VERSION ""

NS_ :

BS_:

BU_: AHLM ASBS CADM CBC DIAGNOST DPDM DTCM ECM EHPS ESC ESL ESM ETM EVCU2 GPF IC IRCM LTM OCM ORC PTS RF_HUB SCCM SGW TBM TCM

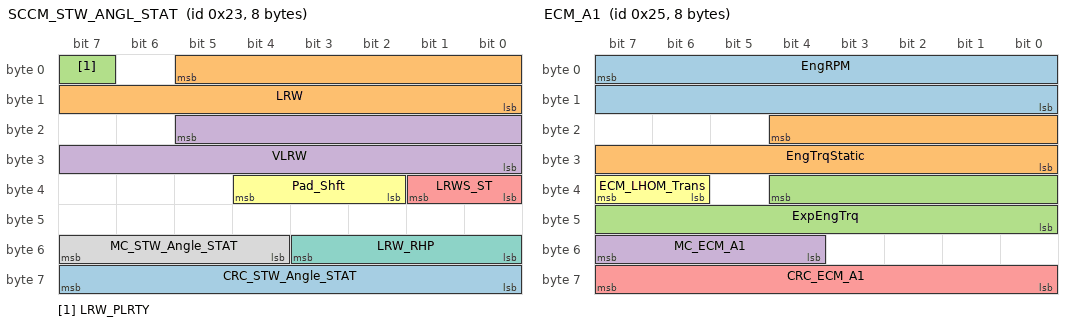
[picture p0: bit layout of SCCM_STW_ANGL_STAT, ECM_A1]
BO_ 35 SCCM_STW_ANGL_STAT: 8 SCCM
 SG_ CRC_STW_Angle_STAT : 56|8@1+ (1,0) [0|0] ""  CADM,ECM,ESC,ETM,EVCU2,IRCM,ORC,SGW,TCM
 SG_ LRW : 5|14@0+ (0.5,-2048) [-2048|2047] "Degrees"  CADM,CBC,DTCM,ECM,EHPS,ESC,EVCU2,IC,IRCM,ORC,SGW,TCM
 SG_ LRW_PLRTY : 7|1@1+ (1,0) [0|0] ""  CADM,ESC,ETM,IC,IRCM,ORC,SGW
 SG_ VLRW : 21|14@0+ (0.5,-2048) [-2048|2047] "∞/s"  CADM,DTCM,ECM,EHPS,ESC,EVCU2,IRCM,SGW
 SG_ LRWS_ST : 32|2@1+ (1,0) [0|0] ""  CADM,CBC,DTCM,ESC,IC,IRCM,ORC,SGW
 SG_ Pad_Shft : 34|3@1+ (1,0) [0|0] ""  ECM,SGW,TCM
 SG_ LRW_RHP : 48|4@1+ (0.1,-0.4) [-0.4|0.4] "Degrees"  CADM,EHPS,SGW
 SG_ MC_STW_Angle_STAT : 52|4@1+ (1,0) [0|15] ""  CADM,ECM,ESC,ETM,EVCU2,IRCM,ORC,SGW,TCM

BO_ 37 ECM_A1: 8 ECM
 SG_ EngRPM : 7|16@0+ (1,0) [0|65534] "rpm"  AHLM,CADM,CBC,DTCM,EHPS,ESC,ETM,EVCU2,IC,IRCM,ORC,RF_HUB,SGW,TBM,TCM
 SG_ EngTrqStatic : 20|13@0+ (0.25,-500) [-500|1547.5] "Nm"  CADM,DTCM,ESC,ETM,IRCM,ORC,SGW,TBM,TCM
 SG_ ExpEngTrq : 36|13@0+ (0.25,-500) [-500|1547.5] "Nm"  CADM,DTCM,ESC,IRCM,SGW
 SG_ MC_ECM_A1 : 52|4@1+ (1,0) [0|15] ""  CADM,ESC,IRCM,SGW,TCM
 SG_ CRC_ECM_A1 : 56|8@1+ (1,0) [0|0] ""  CADM,ESC,IRCM,SGW,TCM
 SG_ ECM_LHOM_Trans : 38|2@1+ (1,0) [0|0] ""  SGW,TCM

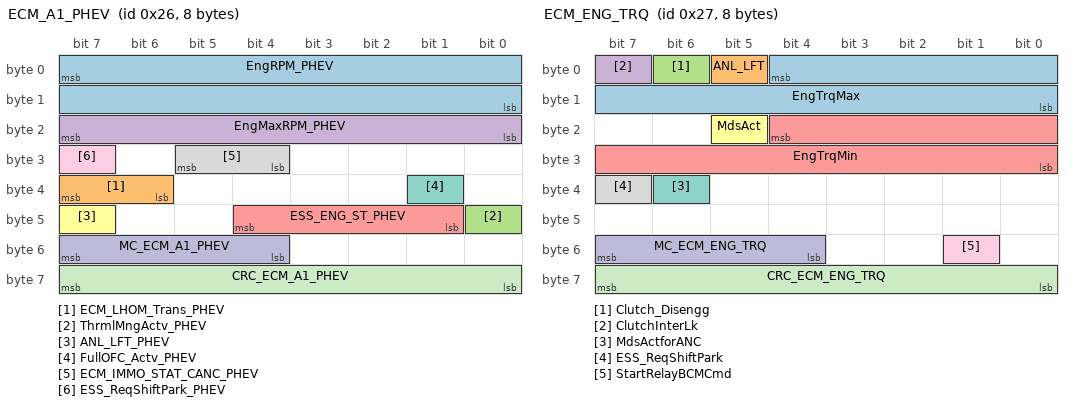
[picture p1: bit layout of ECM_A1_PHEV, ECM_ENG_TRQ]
BO_ 38 ECM_A1_PHEV: 8 ECM
 SG_ EngRPM_PHEV : 7|16@0+ (1,0) [0|65534] "rpm"  AHLM,CADM,CBC,EHPS,ESC,ETM,EVCU2,IC,IRCM,ORC,RF_HUB,SGW,TBM,TCM
 SG_ ECM_LHOM_Trans_PHEV : 38|2@1+ (1,0) [0|0] ""  EVCU2,SGW
 SG_ ThrmlMngActv_PHEV : 40|1@1+ (1,0) [0|0] ""  CADM,EVCU2,IRCM,SGW
 SG_ EngMaxRPM_PHEV : 16|8@1+ (50,0) [0|12700] "rpm"  EVCU2,SGW
 SG_ ESS_ENG_ST_PHEV : 41|4@1+ (1,0) [0|0] ""  CADM,CBC,DTCM,EHPS,ESC,EVCU2,IC,IRCM,ORC,PTS,SGW,TCM
 SG_ ANL_LFT_PHEV : 47|1@1+ (1,0) [0|0] ""  CBC,SGW
 SG_ FullOFC_Actv_PHEV : 33|1@1+ (1,0) [0|0] ""  ESC,SGW
 SG_ ECM_IMMO_STAT_CANC_PHEV : 28|2@1+ (1,0) [0|0] ""  CBC,EVCU2,SGW
 SG_ ESS_ReqShiftPark_PHEV : 31|1@1+ (1,0) [0|0] ""  SGW,TCM
 SG_ MC_ECM_A1_PHEV : 52|4@1+ (1,0) [0|15] ""  CADM,DTCM,ESC,EVCU2,IRCM,SGW,TCM
 SG_ CRC_ECM_A1_PHEV : 56|8@1+ (1,0) [0|0] ""  CADM,DTCM,ESC,EVCU2,IRCM,SGW,TCM

BO_ 39 ECM_ENG_TRQ: 8 ECM
 SG_ EngTrqMax : 4|13@0+ (0.25,-500) [-500|1547.5] "Nm"  CADM,DTCM,ESC,IRCM,SGW,TCM
 SG_ ANL_LFT : 5|1@1+ (1,0) [0|0] ""  CBC,SGW
 SG_ Clutch_Disengg : 6|1@1+ (1,0) [0|0] ""  CADM,CBC,DTCM,ECM,ESC,IRCM,ORC,SGW
 SG_ ClutchInterLk : 7|1@1+ (1,0) [0|0] ""  DTCM,ECM,ESC,ORC,SGW
 SG_ EngTrqMin : 20|13@0+ (0.25,-500) [-500|1547.5] "Nm"  CADM,DTCM,ESC,IRCM,SGW
 SG_ MdsAct : 21|1@1+ (1,0) [0|0] ""  ETM,SGW,TBM
 SG_ MdsActforANC : 38|1@1+ (1,0) [0|0] ""  CBC,SGW
 SG_ ESS_ReqShiftPark : 39|1@1+ (1,0) [0|0] ""  RF_HUB,SGW,TCM
 SG_ StartRelayBCMCmd : 49|1@1+ (1,0) [0|0] ""  CBC,SGW
 SG_ MC_ECM_ENG_TRQ : 52|4@1+ (1,0) [0|15] ""  CADM,ESC,IRCM,SGW
 SG_ CRC_ECM_ENG_TRQ : 56|8@1+ (1,0) [0|0] ""  CADM,ESC,IRCM,SGW

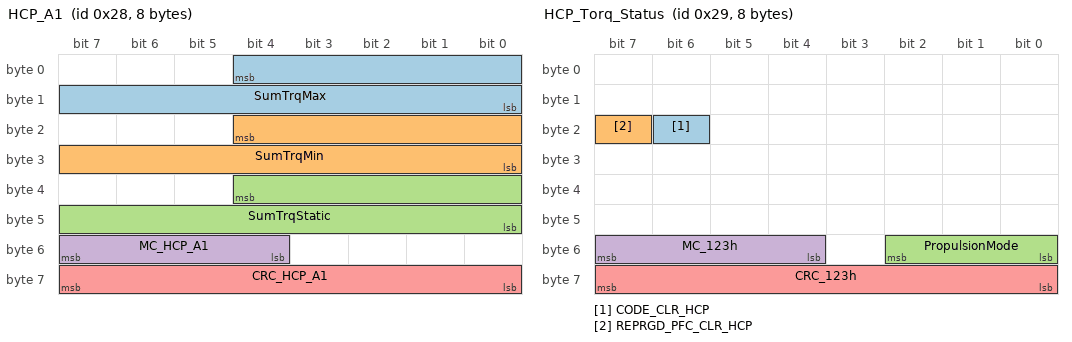
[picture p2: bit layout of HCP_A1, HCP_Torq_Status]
BO_ 40 HCP_A1: 8 EVCU2
 SG_ SumTrqMax : 4|13@0+ (0.25,-500) [-500|1547.5] "Nm"  CADM,DTCM,ESC,IRCM,SGW,TCM
 SG_ SumTrqMin : 20|13@0+ (0.25,-500) [-500|1547.5] "Nm"  CADM,IRCM,SGW
 SG_ SumTrqStatic : 36|13@0+ (0.25,-500) [-500|1547.5] "Nm"  CADM,DTCM,ESC,IRCM,ORC,SGW,TCM
 SG_ MC_HCP_A1 : 52|4@1+ (1,0) [0|15] ""  CADM,DTCM,ECM,ESC,IRCM,SGW,TCM
 SG_ CRC_HCP_A1 : 56|8@1+ (1,0) [0|0] ""  CADM,DTCM,ECM,ESC,IRCM,SGW,TCM

BO_ 41 HCP_Torq_Status: 8 EVCU2
 SG_ CODE_CLR_HCP : 22|1@1+ (1,0) [0|0] ""  ECM,SGW
 SG_ REPRGD_PFC_CLR_HCP : 23|1@1+ (1,0) [0|0] ""  ECM,SGW
 SG_ PropulsionMode : 48|3@1+ (1,0) [0|0] ""  ECM,SGW
 SG_ MC_123h : 52|4@1+ (1,0) [0|15] ""  ECM,SGW,TCM
 SG_ CRC_123h : 56|8@1+ (1,0) [0|255] ""  ECM,SGW,TCM

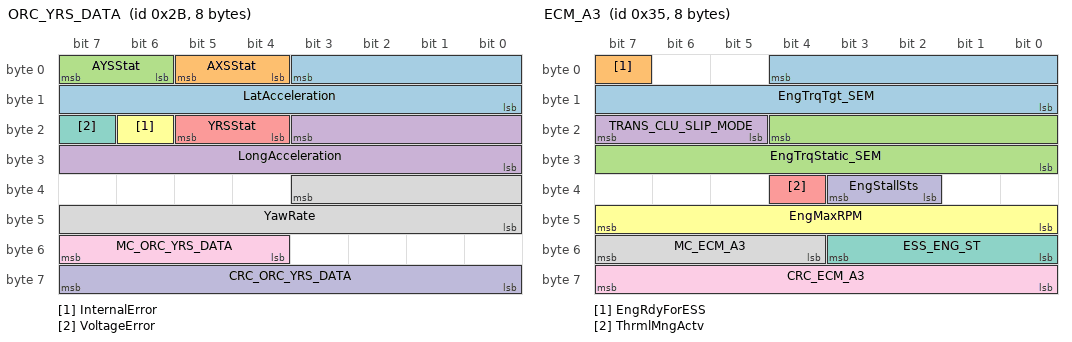
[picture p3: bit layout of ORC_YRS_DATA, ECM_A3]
BO_ 43 ORC_YRS_DATA: 8 ORC
 SG_ LatAcceleration : 3|12@0+ (0.02,-40.96) [-40.96|40.92] "m/s≤"  ESC,EVCU2,SGW
 SG_ AXSStat : 4|2@1+ (1,0) [0|0] ""  ESC,EVCU2,SGW
 SG_ AYSStat : 6|2@1+ (1,0) [0|0] ""  ESC,SGW
 SG_ LongAcceleration : 19|12@0+ (0.02,-40.96) [-40.96|40.92] "m/s≤"  ESC,EVCU2,SGW
 SG_ YRSStat : 20|2@1+ (1,0) [0|0] ""  ESC,EVCU2,SGW
 SG_ InternalError : 22|1@1+ (1,0) [0|0] ""  ESC,SGW
 SG_ VoltageError : 23|1@1+ (1,0) [0|0] ""  ESC,SGW
 SG_ YawRate : 35|12@0+ (0.08,-163.84) [-163.84|163.68] "∞/s"  CADM,ESC,EVCU2,SGW
 SG_ MC_ORC_YRS_DATA : 52|4@1+ (1,0) [0|15] ""  ESC,EVCU2,SGW
 SG_ CRC_ORC_YRS_DATA : 56|8@1+ (1,0) [0|0] ""  ESC,EVCU2,SGW

BO_ 47 WHEEL_SPEED_2: 8 ESC
 SG_ BrkPdlRawStat : 33|10@0+ (0.0048828125,0) [0|4.9951171875] "Volts"  ECM,ETM,ORC,SGW,TBM
 SG_ RAW_OBD_VEHACCEL_X : 48|8@1+ (0.08,-10.24) [-10.24|10.16] "m/s≤"  ECM,SGW

BO_ 53 ECM_A3: 8 ECM
 SG_ EngTrqTgt_SEM : 4|13@0+ (0.25,-500) [-500|1547.5] "Nm"  SGW,TCM
 SG_ EngRdyForESS : 7|1@1+ (1,0) [0|0] ""  SGW,TCM
 SG_ EngTrqStatic_SEM : 20|13@0+ (0.25,-500) [-500|1547.5] "Nm"  SGW,TCM
 SG_ TRANS_CLU_SLIP_MODE : 21|3@1+ (1,0) [0|0] ""  SGW,TCM
 SG_ ThrmlMngActv : 36|1@1+ (1,0) [0|0] ""  CADM,IRCM,SGW
 SG_ EngMaxRPM : 40|8@1+ (50,0) [0|12700] "rpm"  SGW
 SG_ ESS_ENG_ST : 48|4@1+ (1,0) [0|0] ""  CADM,CBC,DTCM,EHPS,ESC,ETM,IC,IRCM,ORC,PTS,RF_HUB,SGW,TBM,TCM
 SG_ MC_ECM_A3 : 52|4@1+ (1,0) [0|15] ""  CADM,EHPS,IRCM,PTS,RF_HUB,SGW,TCM
 SG_ CRC_ECM_A3 : 56|8@1+ (1,0) [0|0] ""  CADM,IRCM,PTS,RF_HUB,SGW,TCM
 SG_ EngStallSts : 34|2@1+ (1,0) [0|0] ""  RF_HUB,SGW

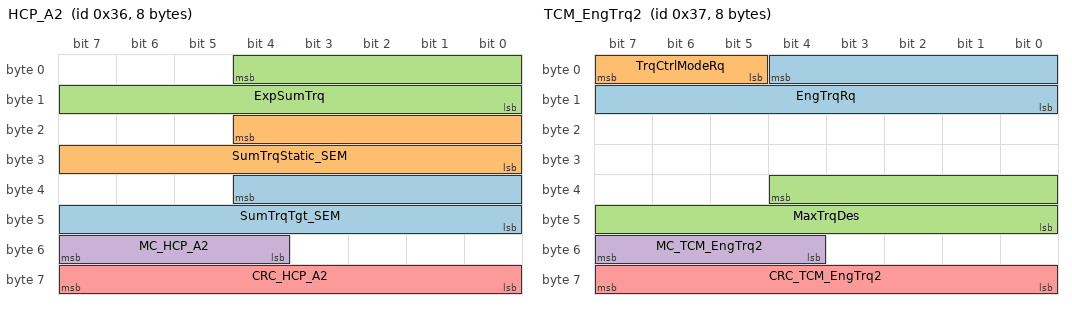
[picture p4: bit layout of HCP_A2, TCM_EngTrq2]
BO_ 54 HCP_A2: 8 EVCU2
 SG_ SumTrqTgt_SEM : 36|13@0+ (0.25,-500) [-500|1547.5] "Nm"  ECM,SGW,TCM
 SG_ SumTrqStatic_SEM : 20|13@0+ (0.25,-500) [-500|1547.5] "Nm"  ECM,SGW,TCM
 SG_ ExpSumTrq : 4|13@0+ (0.25,-500) [-500|1547.5] "Nm"  CADM,DTCM,ESC,IRCM,SGW
 SG_ MC_HCP_A2 : 52|4@1+ (1,0) [0|15] ""  CADM,DTCM,ECM,ESC,IRCM,SGW,TCM
 SG_ CRC_HCP_A2 : 56|8@1+ (1,0) [0|0] ""  CADM,DTCM,ECM,ESC,IRCM,SGW,TCM

BO_ 55 TCM_EngTrq2: 8 TCM
 SG_ EngTrqRq : 4|13@0+ (0.25,-500) [-500|1547.5] "Nm"  ECM,ESC,EVCU2,SGW
 SG_ TrqCtrlModeRq : 5|3@1+ (1,0) [0|0] ""  ECM,ESC,EVCU2,SGW
 SG_ MaxTrqDes : 36|13@0+ (0.25,-500) [-500|1547.5] "Nm"  ECM,EVCU2,SGW
 SG_ MC_TCM_EngTrq2 : 52|4@1+ (1,0) [0|15] ""  CADM,ECM,ESC,EVCU2,IRCM,SGW
 SG_ CRC_TCM_EngTrq2 : 56|8@1+ (1,0) [0|0] ""  CADM,ECM,ESC,EVCU2,IRCM,SGW

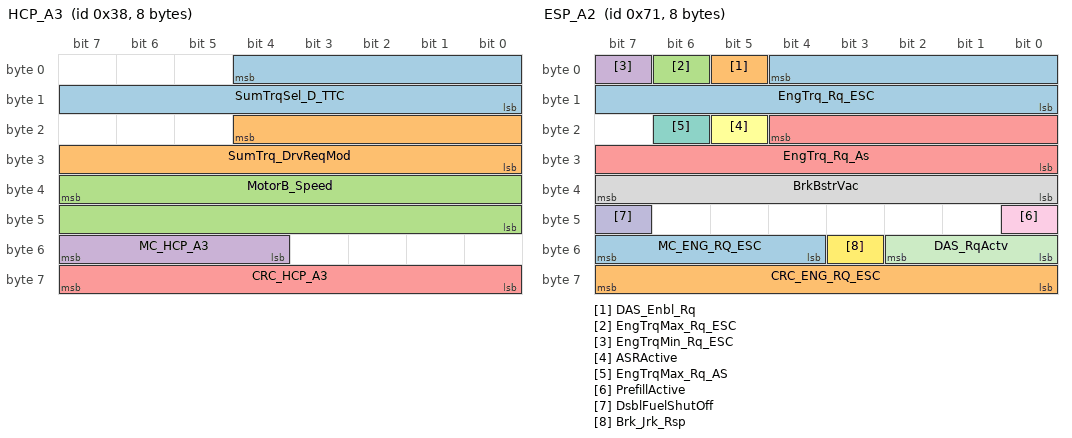
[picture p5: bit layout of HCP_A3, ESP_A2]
BO_ 56 HCP_A3: 8 EVCU2
 SG_ SumTrqSel_D_TTC : 4|13@0+ (0.25,-500) [-500|1547.5] "Nm"  CADM,DTCM,ESC,IRCM,ORC,SGW,TCM
 SG_ SumTrq_DrvReqMod : 20|13@0+ (0.25,-500) [-500|1547.5] "Nm"  CADM,DTCM,ESC,IRCM,SGW,TCM
 SG_ MotorB_Speed : 39|16@0+ (1,-16382) [-16382|49151] "rpm"  DTCM,ECM,ESC,SGW,TCM
 SG_ MC_HCP_A3 : 52|4@1+ (1,0) [0|15] ""  CADM,DTCM,ECM,ESC,IRCM,SGW,TCM
 SG_ CRC_HCP_A3 : 56|8@1+ (1,0) [0|0] ""  CADM,DTCM,ECM,ESC,IRCM,SGW,TCM

BO_ 113 ESP_A2: 8 ESC
 SG_ EngTrq_Rq_ESC : 4|13@0+ (0.25,-500) [-500|1547.5] "Nm"  DTCM,ECM,ETM,EVCU2,SGW,TBM
 SG_ DAS_Enbl_Rq : 5|1@1+ (1,0) [0|0] ""  CADM,EVCU2,IRCM,SGW
 SG_ EngTrqMax_Rq_ESC : 6|1@1+ (1,0) [0|0] ""  ECM,EVCU2,SGW,TCM
 SG_ EngTrqMin_Rq_ESC : 7|1@1+ (1,0) [0|0] ""  ECM,EVCU2,SGW,TCM
 SG_ EngTrq_Rq_As : 20|13@0+ (0.25,-500) [-500|1547.5] "Nm"  CADM,ECM,IRCM,ORC,SGW
 SG_ ASRActive : 21|1@1+ (1,0) [0|0] ""  ETM,ORC,SGW,TBM,TCM
 SG_ EngTrqMax_Rq_AS : 22|1@1+ (1,0) [0|0] ""  ECM,ORC,SGW
 SG_ BrkBstrVac : 32|8@1+ (0.55,-119.7) [-119.7|20] "kPa"  ECM,ORC,SGW
 SG_ PrefillActive : 40|1@1+ (1,0) [0|0] ""  CADM,IRCM,SGW
 SG_ DsblFuelShutOff : 47|1@1+ (1,0) [0|0] ""  ECM,SGW
 SG_ DAS_RqActv : 48|3@1+ (1,0) [0|0] ""  CADM,IRCM,ORC,SGW
 SG_ Brk_Jrk_Rsp : 51|1@1+ (1,0) [0|0] ""  CADM,IRCM,ORC,SGW
 SG_ MC_ENG_RQ_ESC : 52|4@1+ (1,0) [0|15] ""  CADM,ECM,EVCU2,IRCM,SGW,TCM
 SG_ CRC_ENG_RQ_ESC : 56|8@1+ (1,0) [0|0] ""  CADM,ECM,EVCU2,IRCM,SGW,TCM

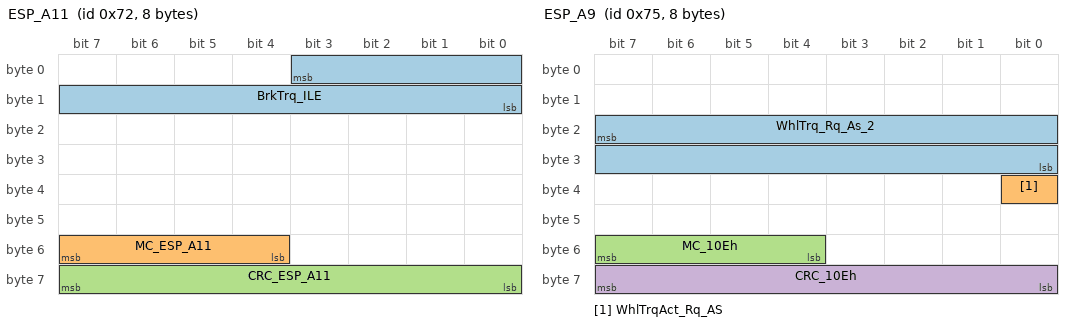
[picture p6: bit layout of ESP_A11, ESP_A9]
BO_ 114 ESP_A11: 8 ESC
 SG_ BrkTrq_ILE : 3|12@0+ (3,0) [0|12282] "Nm"  EVCU2,SGW,TCM
 SG_ MC_ESP_A11 : 52|4@1+ (1,0) [0|15] ""  EVCU2,SGW,TCM
 SG_ CRC_ESP_A11 : 56|8@1+ (1,0) [0|0] ""  EVCU2,SGW,TCM

BO_ 117 ESP_A9: 8 ESC
 SG_ WhlTrq_Rq_As_2 : 23|16@0+ (2,-36878) [-36878|94190] "Nm"  EVCU2,ORC,SGW
 SG_ WhlTrqAct_Rq_AS : 32|1@1+ (1,0) [0|0] ""  EVCU2,SGW
 SG_ MC_10Eh : 52|4@1+ (1,0) [0|15] ""  ECM,EVCU2,SGW
 SG_ CRC_10Eh : 56|8@1+ (1,0) [0|255] ""  ECM,EVCU2,SGW

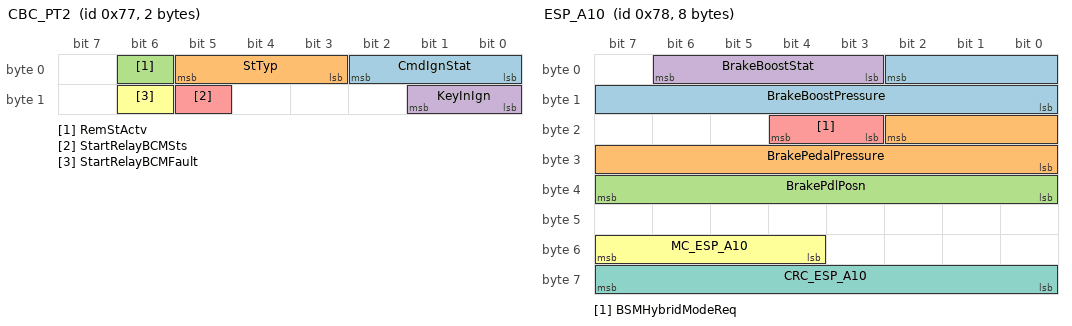
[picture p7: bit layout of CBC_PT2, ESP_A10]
BO_ 119 CBC_PT2: 2 CBC
 SG_ CmdIgnStat : 0|3@1+ (1,0) [0|0] ""  AHLM,ASBS,CADM,DPDM,DTCM,ECM,EHPS,ESC,ESL,ESM,EVCU2,IC,IRCM,OCM,ORC,PTS,RF_HUB,SCCM,SGW,TCM
 SG_ StTyp : 3|3@1+ (1,0) [0|0] ""  DTCM,RF_HUB,SGW
 SG_ RemStActv : 6|1@1+ (1,0) [0|0] ""  DTCM,ECM,ESM,EVCU2,IC,ORC,RF_HUB,SGW,TCM
 SG_ KeyInIgn : 8|2@1+ (1,0) [0|0] ""  ESC,ESL,EVCU2,IC,RF_HUB,SGW
 SG_ StartRelayBCMSts : 13|1@1+ (1,0) [0|0] ""  ECM,SGW
 SG_ StartRelayBCMFault : 14|1@1+ (1,0) [0|0] ""  ECM,SGW

BO_ 120 ESP_A10: 8 ESC
 SG_ BrakeBoostPressure : 2|11@0+ (0.1,0) [0|200] "bar"  ECM,EVCU2,SGW,TCM
 SG_ BrakePedalPressure : 18|11@0+ (0.1,0) [0|200] "bar"  ECM,EVCU2,SGW,TCM
 SG_ BrakePdlPosn : 32|8@1+ (0.4,0) [0|100] "%"  ECM,ETM,EVCU2,ORC,SGW,TBM,TCM
 SG_ BrakeBoostStat : 3|4@1+ (1,0) [0|0] ""  SGW
 SG_ BSMHybridModeReq : 19|2@1+ (1,0) [0|0] ""  EVCU2,SGW
 SG_ MC_ESP_A10 : 52|4@1+ (1,0) [0|15] ""  ECM,EVCU2,SGW,TCM
 SG_ CRC_ESP_A10 : 56|8@1+ (1,0) [0|0] ""  ECM,EVCU2,SGW,TCM

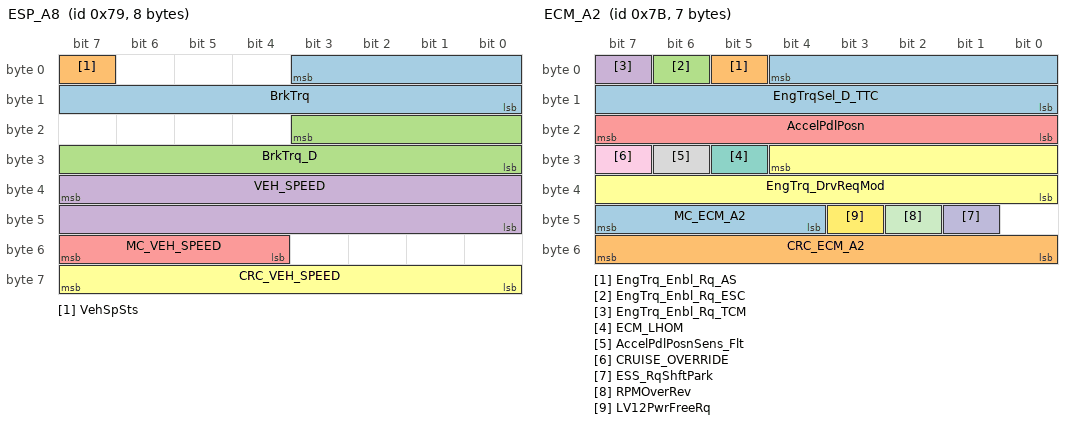
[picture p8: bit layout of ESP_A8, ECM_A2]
BO_ 121 ESP_A8: 8 ESC
 SG_ BrkTrq : 3|12@0+ (3,0) [0|12282] "Nm"  CADM,CBC,DTCM,ECM,EVCU2,IRCM,ORC,SGW,TCM
 SG_ VehSpSts : 7|1@1+ (1,0) [0|0] ""  CADM,EVCU2,IRCM,SGW
 SG_ BrkTrq_D : 19|12@0+ (3,0) [0|12282] "Nm"  CADM,DTCM,ECM,EVCU2,IRCM,SGW,TCM
 SG_ VEH_SPEED : 39|16@0+ (0.0078125,0) [0|511.984375] "km/h"  AHLM,ASBS,CADM,CBC,DTCM,ECM,EHPS,ESL,ETM,EVCU2,IC,IRCM,ORC,PTS,RF_HUB,SGW,TBM,TCM
 SG_ MC_VEH_SPEED : 52|4@1+ (1,0) [0|15] ""  CADM,ECM,ESL,ESM,EVCU2,IC,IRCM,ORC,PTS,RF_HUB,SGW,TCM
 SG_ CRC_VEH_SPEED : 56|8@1+ (1,0) [0|0] ""  CADM,ECM,ESL,ESM,EVCU2,IC,IRCM,ORC,PTS,RF_HUB,SGW,TCM

BO_ 123 ECM_A2: 7 ECM
 SG_ EngTrqSel_D_TTC : 4|13@0+ (0.25,-500) [-500|1547.5] "Nm"  CADM,DTCM,ESC,IRCM,ORC,SGW,TCM
 SG_ EngTrq_Enbl_Rq_AS : 5|1@1+ (1,0) [0|0] ""  CADM,ESC,IRCM,SGW
 SG_ EngTrq_Enbl_Rq_ESC : 6|1@1+ (1,0) [0|0] ""  CADM,ESC,IRCM,SGW
 SG_ EngTrq_Enbl_Rq_TCM : 7|1@1+ (1,0) [0|0] ""  ORC,SGW,TCM
 SG_ AccelPdlPosn : 16|8@1+ (0.4,0) [0|100] "%"  CBC,DTCM,ESC,ETM,IC,SGW,TBM,TCM
 SG_ EngTrq_DrvReqMod : 28|13@0+ (0.25,-500) [-500|1547.5] "Nm"  DTCM,ESC,SGW,TCM
 SG_ ECM_LHOM : 29|1@1+ (1,0) [0|0] ""  CADM,IRCM,SGW
 SG_ AccelPdlPosnSens_Flt : 30|1@1+ (1,0) [0|0] ""  CADM,CBC,DTCM,ESC,IRCM,SGW,TCM
 SG_ CRUISE_OVERRIDE : 31|1@1+ (1,0) [0|0] ""  CADM,ESC,IRCM,ORC,SGW,TCM
 SG_ ESS_RqShftPark : 41|1@1+ (1,0) [0|0] ""  ORC,SGW
 SG_ RPMOverRev : 42|1@1+ (1,0) [0|0] ""  CADM,IRCM,SGW
 SG_ LV12PwrFreeRq : 43|1@1+ (1,0) [0|0] ""  ESC,SGW,TCM
 SG_ MC_ECM_A2 : 44|4@1+ (1,0) [0|15] ""  CADM,ESC,IRCM,SGW,TCM
 SG_ CRC_ECM_A2 : 48|8@1+ (1,0) [0|0] ""  CADM,ESC,IRCM,SGW,TCM

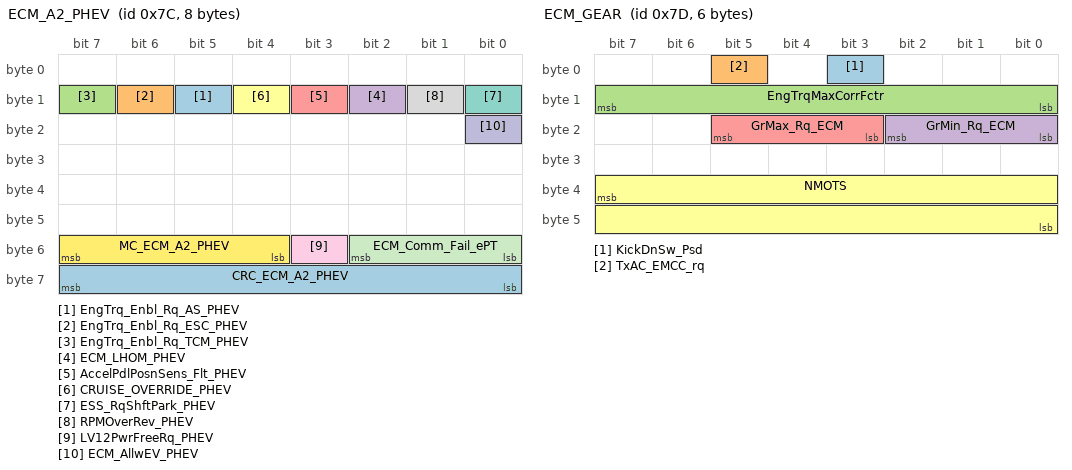
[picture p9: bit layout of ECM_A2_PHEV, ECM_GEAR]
BO_ 124 ECM_A2_PHEV: 8 ECM
 SG_ EngTrq_Enbl_Rq_AS_PHEV : 13|1@1+ (1,0) [0|0] ""  CADM,IRCM,SGW
 SG_ EngTrq_Enbl_Rq_ESC_PHEV : 14|1@1+ (1,0) [0|0] ""  CADM,EVCU2,IRCM,SGW
 SG_ EngTrq_Enbl_Rq_TCM_PHEV : 15|1@1+ (1,0) [0|0] ""  EVCU2,ORC,SGW
 SG_ ECM_LHOM_PHEV : 10|1@1+ (1,0) [0|0] ""  CADM,EVCU2,IRCM,SGW,TCM
 SG_ AccelPdlPosnSens_Flt_PHEV : 11|1@1+ (1,0) [0|0] ""  CADM,IRCM,SGW
 SG_ CRUISE_OVERRIDE_PHEV : 12|1@1+ (1,0) [0|0] ""  CADM,IRCM,SGW
 SG_ ESS_RqShftPark_PHEV : 8|1@1+ (1,0) [0|0] ""  ORC,SGW
 SG_ RPMOverRev_PHEV : 9|1@1+ (1,0) [0|0] ""  CADM,EVCU2,IRCM,SGW
 SG_ LV12PwrFreeRq_PHEV : 51|1@1+ (1,0) [0|0] ""  ESC,EVCU2,SGW
 SG_ ECM_AllwEV_PHEV : 16|1@1+ (1,0) [0|0] ""  EVCU2,SGW
 SG_ ECM_Comm_Fail_ePT : 48|3@1+ (1,0) [0|0] ""  EVCU2,SGW,TCM
 SG_ MC_ECM_A2_PHEV : 52|4@1+ (1,0) [0|15] ""  CADM,DTCM,ESC,EVCU2,IRCM,SGW,TCM
 SG_ CRC_ECM_A2_PHEV : 56|8@1+ (1,0) [0|0] ""  CADM,DTCM,ESC,EVCU2,IRCM,SGW,TCM

BO_ 125 ECM_GEAR: 6 ECM
 SG_ KickDnSw_Psd : 3|1@1+ (1,0) [0|0] ""  ESC,SGW
 SG_ TxAC_EMCC_rq : 5|1@1+ (1,0) [0|0] ""  SGW,TCM
 SG_ EngTrqMaxCorrFctr : 8|8@1+ (0.0078,0) [0|1.98] "Nm"  SGW,TCM
 SG_ GrMin_Rq_ECM : 16|3@1+ (1,0) [0|0] ""  SGW,TCM
 SG_ GrMax_Rq_ECM : 19|3@1+ (1,0) [0|0] ""  SGW,TCM
 SG_ NMOTS : 39|16@0+ (1,0) [0|65534] "rpm"  ESC,SGW,TCM

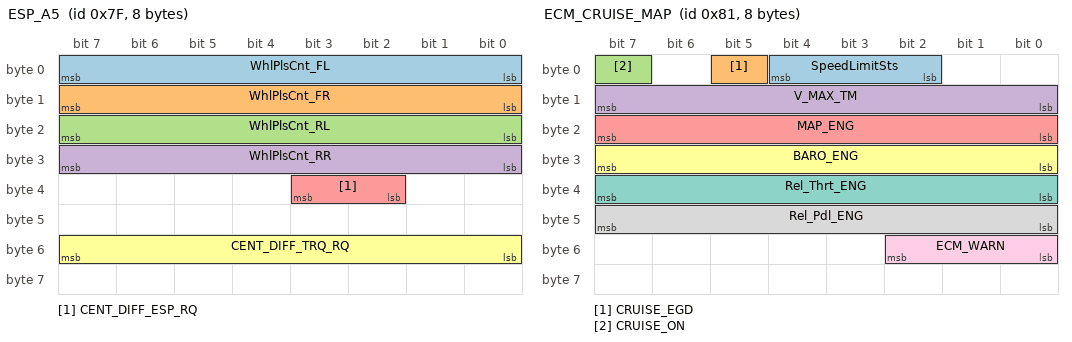
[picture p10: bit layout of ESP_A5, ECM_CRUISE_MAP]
BO_ 127 ESP_A5: 8 ESC
 SG_ WhlPlsCnt_FL : 0|8@1+ (1,0) [0|254] "Impulse"  CADM,CBC,IRCM,PTS,RF_HUB,SGW,TBM
 SG_ WhlPlsCnt_FR : 8|8@1+ (1,0) [0|254] "Impulse"  CADM,CBC,IRCM,PTS,RF_HUB,SGW,TBM
 SG_ WhlPlsCnt_RL : 16|8@1+ (1,0) [0|254] "Impulse"  CADM,CBC,IRCM,PTS,RF_HUB,SGW,TBM
 SG_ WhlPlsCnt_RR : 24|8@1+ (1,0) [0|254] "Impulse"  CADM,CBC,IRCM,PTS,RF_HUB,SGW,TBM
 SG_ CENT_DIFF_ESP_RQ : 34|2@1+ (1,0) [0|0] ""  DTCM,SGW
 SG_ CENT_DIFF_TRQ_RQ : 48|8@1+ (10,0) [0|2540] "Nm"  DTCM,SGW

BO_ 129 ECM_CRUISE_MAP: 8 ECM
 SG_ SpeedLimitSts : 2|3@1+ (1,0) [0|0] ""  CADM,IC,IRCM,ORC,SGW
 SG_ CRUISE_EGD : 5|1@1+ (1,0) [0|0] ""  CBC,ESC,ETM,IC,ORC,SGW,TBM,TCM
 SG_ CRUISE_ON : 7|1@1+ (1,0) [0|0] ""  CBC,ESC,IC,ORC,SGW,TCM
 SG_ V_MAX_TM : 8|8@1+ (1,0) [0|250] "km/h(mph)"  SGW,TCM
 SG_ MAP_ENG : 16|8@1+ (0.8,0) [0|203.2] "kPa"  ESC,ETM,SGW,TBM
 SG_ BARO_ENG : 24|8@1+ (1,0) [0|254] "kPaA"  ESC,ETM,SGW,TBM
 SG_ Rel_Thrt_ENG : 32|8@1+ (0.019607843,0) [0|4.98] "Volts"  ESC,ETM,SGW,TBM
 SG_ Rel_Pdl_ENG : 40|8@1+ (0.019607843,0) [0|4.98] "Volts"  ESC,ETM,SGW,TBM
 SG_ ECM_WARN : 48|3@1+ (1,0) [0|0] ""  IC,SGW

BO_ 131 ESP_A1: 8 ESC
 SG_ Brk_Stat : 0|2@1+ (1,0) [0|0] ""  CBC,ECM,ETM,IC,ORC,PTS,SGW,TBM
 SG_ BrkPdl_Stat : 2|2@1+ (1,0) [0|0] ""  CADM,CBC,DTCM,ECM,ETM,EVCU2,IRCM,ORC,RF_HUB,SGW,TBM,TCM
 SG_ BrkPdl_Flt : 4|1@1+ (1,0) [0|0] ""  CADM,ECM,ETM,EVCU2,IRCM,ORC,SGW,TBM
 SG_ BrkIntrvntn_Actv_ESP : 5|1@1+ (1,0) [0|0] ""  CADM,DTCM,ECM,ETM,EVCU2,ORC,SGW,TBM,TCM
 SG_ BrkIntrvntn_Actv_AS : 6|1@1+ (1,0) [0|0] ""  CADM,ETM,IRCM,SGW,TBM,TCM
 SG_ BrkIntrvntn_Enbl : 7|1@1+ (1,0) [0|0] ""  ECM,ORC,SGW,TCM
 SG_ EmgBrk_Actv : 8|1@1+ (1,0) [0|0] ""  ORC,SGW
 SG_ FullBrk_Actv : 9|1@1+ (1,0) [0|0] ""  ORC,SGW
 SG_ ESP_Sys_Stat : 10|2@1+ (1,0) [0|0] ""  ECM,ETM,EVCU2,SGW,TBM,TCM
 SG_ SelSpdSts : 12|2@1+ (1,0) [0|0] ""  CBC,DTCM,ECM,EVCU2,IC,SGW,TCM
 SG_ ABS_BrkEvt : 14|1@1+ (1,0) [0|0] ""  CADM,CBC,DTCM,ETM,EVCU2,ORC,SGW,TBM,TCM
 SG_ DTR_CC_Engaged : 15|1@1+ (1,0) [0|0] ""  CBC,ECM,EVCU2,SGW,TCM
 SG_ GrMin_Rq_ESC : 16|3@1+ (1,0) [0|0] ""  SGW,TCM
 SG_ GrMax_Rq_ESC : 19|3@1+ (1,0) [0|0] ""  SGW,TCM
 SG_ GrMinMax_Rq_DTR : 22|1@1+ (1,0) [0|0] ""  SGW,TCM
 SG_ DTR_CC_Enabled : 23|1@1+ (1,0) [0|0] ""  ECM,EVCU2,SGW
 SG_ Brk_Thermdl : 25|1@1+ (1,0) [0|0] ""  CADM,EVCU2,IRCM,SGW
 SG_ ShftChrDsp_Rq_ESC : 26|4@1+ (1,0) [0|0] ""  ECM,SGW,TCM
 SG_ RollTestMd_Actv : 30|2@1+ (1,0) [0|0] ""  CADM,DTCM,ECM,IRCM,SGW
 SG_ REF_VEH_SPEED : 33|10@0+ (0.5,0) [0|511] "km/h"  EVCU2,ORC,SGW,TCM
 SG_ SPCR_AS_Off_Rq : 38|2@1+ (1,0) [0|0] ""  CADM,ECM,EVCU2,IRCM,SGW
 SG_ MC_Brk_Stat : 52|4@1+ (1,0) [0|15] ""  CADM,ECM,EVCU2,IC,IRCM,PTS,RF_HUB,SGW,TCM
 SG_ CRC_Brk_Stat : 56|8@1+ (1,0) [0|0] ""  CADM,ECM,EVCU2,IC,IRCM,PTS,RF_HUB,SGW,TCM
 SG_ HillHolderActive : 24|1@1+ (1,0) [0|0] ""  SGW,TCM

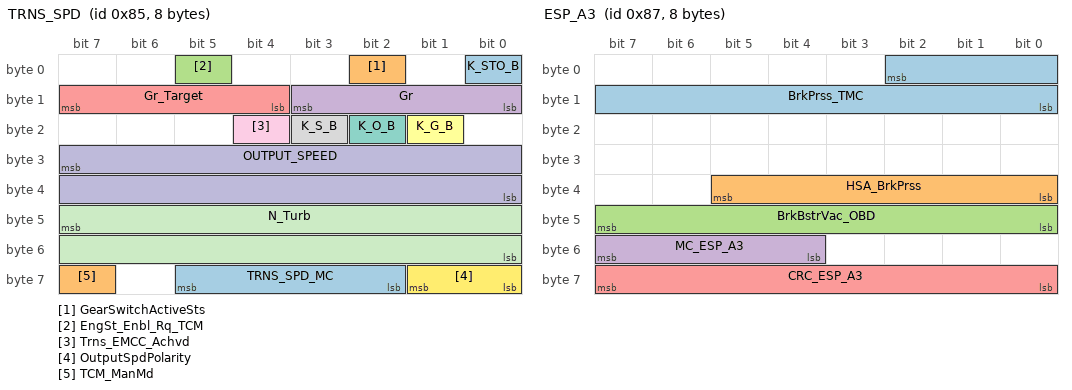
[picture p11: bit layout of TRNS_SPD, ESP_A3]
BO_ 133 TRNS_SPD: 8 TCM
 SG_ K_STO_B : 0|1@1+ (1,0) [0|0] ""  ECM,ETM,EVCU2,SGW,TBM
 SG_ GearSwitchActiveSts : 2|1@1+ (1,0) [0|0] ""  ESC,ETM,SGW,TBM
 SG_ EngSt_Enbl_Rq_TCM : 5|1@1+ (1,0) [0|0] ""  ETM,RF_HUB,SGW,TBM
 SG_ Gr : 8|4@1+ (1,0) [0|0] ""  CBC,DTCM,ECM,ESC,ETM,EVCU2,IC,ORC,RF_HUB,SGW,TBM
 SG_ Gr_Target : 12|4@1+ (1,0) [0|0] ""  CBC,DTCM,ECM,ESC,EVCU2,SGW
 SG_ K_G_B : 17|1@1+ (1,0) [0|0] ""  ECM,ESC,ETM,EVCU2,SGW,TBM
 SG_ K_O_B : 18|1@1+ (1,0) [0|0] ""  ECM,ESC,ETM,EVCU2,SGW,TBM
 SG_ K_S_B : 19|1@1+ (1,0) [0|0] ""  ECM,ESC,ETM,EVCU2,SGW,TBM
 SG_ Trns_EMCC_Achvd : 20|1@1+ (1,0) [0|0] ""  ECM,ETM,SGW,TBM
 SG_ OUTPUT_SPEED : 31|16@0+ (1,0) [0|65534] "rpm"  DTCM,ECM,ESC,ETM,EVCU2,SGW,TBM
 SG_ N_Turb : 47|16@0+ (1,0) [0|65534] "rpm"  ECM,ETM,EVCU2,SGW,TBM
 SG_ OutputSpdPolarity : 56|2@1+ (1,0) [0|0] ""  ESC,ETM,EVCU2,SGW,TBM
 SG_ TRNS_SPD_MC : 58|4@1+ (1,0) [0|15] ""  ECM,ESC,ETM,EVCU2,SGW,TBM
 SG_ TCM_ManMd : 63|1@1+ (1,0) [0|0] ""  DTCM,ECM,ETM,EVCU2,IC,SGW

BO_ 135 ESP_A3: 8 ESC
 SG_ BrkPrss_TMC : 2|11@0+ (0.1,0) [0|200] "bar"  ECM,ETM,ORC,SGW,TBM,TCM
 SG_ HSA_BrkPrss : 32|6@1+ (1,0) [0|50] "bar"  ECM,ETM,ORC,SGW,TBM
 SG_ BrkBstrVac_OBD : 40|8@1+ (0.019607843,0) [0|5] "Volts"  ECM,SGW
 SG_ MC_ESP_A3 : 52|4@1+ (1,0) [0|15] ""  ECM,PTS,SGW,TCM
 SG_ CRC_ESP_A3 : 56|8@1+ (1,0) [0|0] ""  ECM,PTS,SGW,TCM

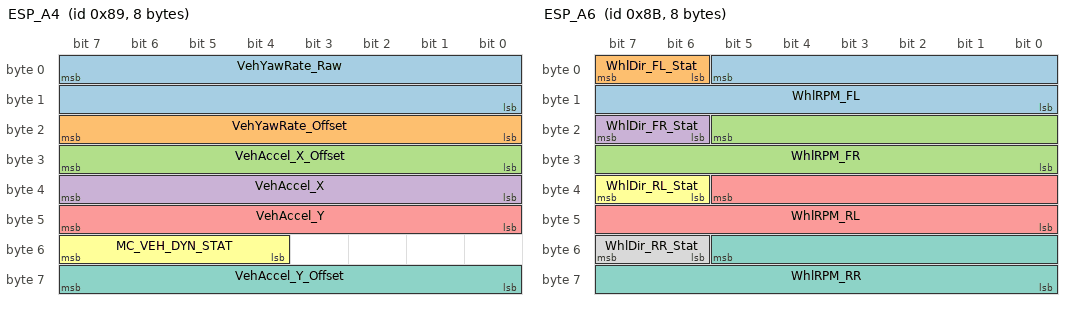
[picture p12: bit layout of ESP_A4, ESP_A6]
BO_ 137 ESP_A4: 8 ESC
 SG_ VehYawRate_Raw : 7|16@0+ (0.01,-327.68) [-327.68|327.66] "∞/s"  CADM,CBC,DTCM,ECM,ETM,IRCM,ORC,SGW,TBM
 SG_ VehYawRate_Offset : 16|8@1+ (0.08,-10.24) [-6.96|6.96] ""  CADM,DTCM,ECM,IRCM,ORC,SGW
 SG_ VehAccel_X_Offset : 24|8@1+ (0.02,-2.56) [-2.56|2.52] "m/s≤"  CADM,DTCM,ECM,ETM,IRCM,ORC,SGW,TBM,TCM
 SG_ VehAccel_X : 32|8@1+ (0.08,-10.24) [-10.24|10.08] "m/s≤"  CADM,CBC,DTCM,ECM,ETM,IRCM,ORC,SGW,TBM,TCM
 SG_ VehAccel_Y : 40|8@1+ (0.08,-10.24) [-10.24|10.08] "m/s≤"  CADM,CBC,DTCM,ECM,ETM,EVCU2,IRCM,ORC,SGW,TBM,TCM
 SG_ MC_VEH_DYN_STAT : 52|4@1+ (1,0) [0|15] ""  CADM,ECM,ETM,IRCM,ORC,PTS,SGW
 SG_ VehAccel_Y_Offset : 56|8@1+ (0.02,-2.56) [-2.56|2.52] "m/s≤"  CADM,DTCM,ECM,ETM,IRCM,ORC,SGW,TBM,TCM

BO_ 139 ESP_A6: 8 ESC
 SG_ WhlRPM_FL : 5|14@0+ (0.5,0) [0|8191] "rpm"  CADM,DTCM,ECM,ETM,EVCU2,IRCM,ORC,PTS,SGW,TBM,TCM
 SG_ WhlDir_FL_Stat : 6|2@1+ (1,0) [0|0] ""  CADM,CBC,EVCU2,IRCM,PTS,SGW,TBM,TCM
 SG_ WhlRPM_FR : 21|14@0+ (0.5,0) [0|8191] "rpm"  CADM,DTCM,ECM,ETM,EVCU2,IRCM,ORC,PTS,SGW,TBM,TCM
 SG_ WhlDir_FR_Stat : 22|2@1+ (1,0) [0|0] ""  CADM,CBC,EVCU2,IRCM,PTS,SGW,TBM,TCM
 SG_ WhlRPM_RL : 37|14@0+ (0.5,0) [0|8191] "rpm"  CADM,DTCM,ECM,ETM,EVCU2,IRCM,ORC,PTS,SGW,TBM,TCM
 SG_ WhlDir_RL_Stat : 38|2@1+ (1,0) [0|0] ""  CADM,CBC,EVCU2,IRCM,PTS,SGW,TBM,TCM
 SG_ WhlRPM_RR : 53|14@0+ (0.5,0) [0|8191] "rpm"  CADM,DTCM,ECM,ETM,EVCU2,IRCM,ORC,PTS,SGW,TBM,TCM
 SG_ WhlDir_RR_Stat : 54|2@1+ (1,0) [0|0] ""  CADM,CBC,EVCU2,IRCM,PTS,SGW,TBM,TCM

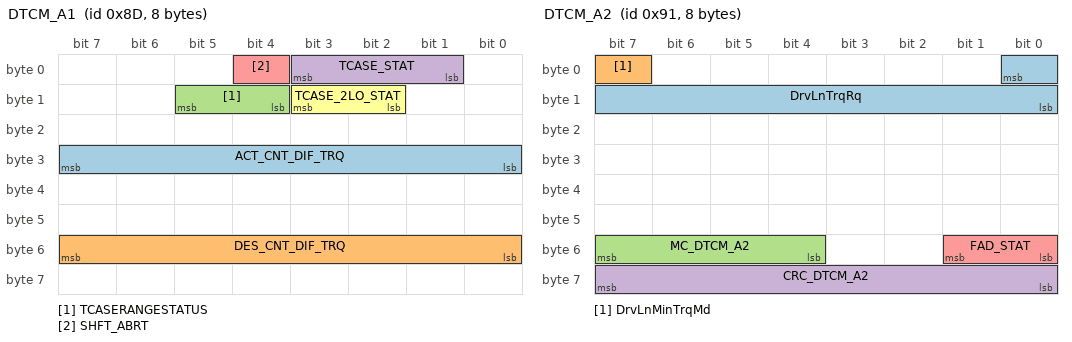
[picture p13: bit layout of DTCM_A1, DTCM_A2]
BO_ 141 DTCM_A1: 8 DTCM
 SG_ ACT_CNT_DIF_TRQ : 24|8@1+ (10,0) [0|2540] "Nm"  ESC,SGW
 SG_ DES_CNT_DIF_TRQ : 48|8@1+ (10,0) [0|2540] "Nm"  SGW
 SG_ TCASERANGESTATUS : 12|2@1+ (1,0) [0|0] ""  ECM,EVCU2,SGW,TCM
 SG_ TCASE_STAT : 1|3@1+ (1,0) [0|0] ""  ASBS,CADM,CBC,ECM,ESC,ETM,EVCU2,IC,IRCM,ORC,PTS,RF_HUB,SGW,TBM,TCM
 SG_ SHFT_ABRT : 4|1@1+ (1,0) [0|0] ""  SGW
 SG_ TCASE_2LO_STAT : 10|2@1+ (1,0) [0|0] ""  SGW

BO_ 145 DTCM_A2: 8 DTCM
 SG_ DrvLnTrqRq : 0|9@0+ (2,0) [0|1020] "Nm"  ECM,EVCU2,SGW
 SG_ DrvLnMinTrqMd : 7|1@1+ (1,0) [0|0] ""  ECM,EVCU2,SGW
 SG_ MC_DTCM_A2 : 52|4@1+ (1,0) [0|15] ""  ECM,EVCU2,SGW,TCM
 SG_ CRC_DTCM_A2 : 56|8@1+ (1,0) [0|0] ""  ECM,EVCU2,SGW,TCM
 SG_ FAD_STAT : 48|2@1+ (1,0) [0|0] ""  SGW,TCM

BO_TX_BU_ 125 : ECM,EVCU2;
BO_TX_BU_ 129 : ECM,EVCU2;

CM_ "Excel Convert to DBC - Written by Vector North America, Inc. 2018";
CM_ SG_ 35 CRC_STW_Angle_STAT "CRC-checksum byte 1 to 7 according to SAE J1850";
CM_ SG_ 35 LRW "Steering wheel angle";
CM_ SG_ 35 LRW_PLRTY "Steering angle polarity (0=ISO 8855 Polarity and CCW = Positive)";
CM_ SG_ 35 VLRW "Delta steering wheel angle";
CM_ SG_ 35 LRWS_ST "Steering wheel angle sensor status";
CM_ SG_ 35 Pad_Shft "Paddle Shift";
CM_ SG_ 35 LRW_RHP "Steering wheel angle remainder high precision";
CM_ SG_ 35 MC_STW_Angle_STAT "Message counter";
CM_ SG_ 37 EngRPM "Engine revolutions per minute";
CM_ SG_ 37 EngTrqStatic "Static engine torque / Effective engine torque";
CM_ SG_ 37 ExpEngTrq "Expected Engine Torque based on target engine speed";
CM_ SG_ 37 MC_ECM_A1 "Message counter";
CM_ SG_ 37 CRC_ECM_A1 "CRC-checksum byte 1 to 7 according to SAE J1850";
CM_ SG_ 37 ECM_LHOM_Trans "Torque Accuracy Information for Transmission";
CM_ SG_ 38 EngRPM_PHEV "Engine revolutions per minute";
CM_ SG_ 38 ECM_LHOM_Trans_PHEV "Torque Accuracy Information for Transmission";
CM_ SG_ 38 ThrmlMngActv_PHEV "Indicates ECM RPM Limitation Status, Active = 1";
CM_ SG_ 38 EngMaxRPM_PHEV "Engine maximum RPM";
CM_ SG_ 38 ESS_ENG_ST_PHEV "ESS Engine State";
CM_ SG_ 38 ANL_LFT_PHEV "Starter motor running (Cranking)";
CM_ SG_ 38 FullOFC_Actv_PHEV "Cylinder cut-out";
CM_ SG_ 38 ECM_IMMO_STAT_CANC_PHEV "ECM immobilizer status";
CM_ SG_ 38 ESS_ReqShiftPark_PHEV "ESS Request shift to Park.  1 = True, 0 = False";
CM_ SG_ 38 MC_ECM_A1_PHEV "Message counter";
CM_ SG_ 38 CRC_ECM_A1_PHEV "CRC-checksum byte 1 to 7 according to SAE J1850";
CM_ SG_ 39 EngTrqMax "Maximum engine torque";
CM_ SG_ 39 ANL_LFT "Starter motor running (Cranking)";
CM_ SG_ 39 Clutch_Disengg "Clutch upstop position:  Upstop=[0]; partial=[1]";
CM_ SG_ 39 ClutchInterLk "Clutch interlock switch, clutch depressed = [0]";
CM_ SG_ 39 EngTrqMin "Minimum engine torque";
CM_ SG_ 39 MdsAct "MDS Active";
CM_ SG_ 39 MdsActforANC "MDS active for ANC; Active = [1]";
CM_ SG_ 39 ESS_ReqShiftPark "ESS Request shift to Park.  1 = True, 0 = False";
CM_ SG_ 39 StartRelayBCMCmd "Engine restart request for StopStart function";
CM_ SG_ 39 MC_ECM_ENG_TRQ "Message counter";
CM_ SG_ 39 CRC_ECM_ENG_TRQ "CRC-checksum byte 1 to 7 according to SAE J1850";
CM_ SG_ 40 SumTrqMax "Maximum Sum Torque";
CM_ SG_ 40 SumTrqMin "Minimum Sum Torque";
CM_ SG_ 40 SumTrqStatic "Static Sum Torque / Effective Sum Torque";
CM_ SG_ 40 MC_HCP_A1 "Message counter";
CM_ SG_ 40 CRC_HCP_A1 "CRC-checksum byte 1 to 7 according to SAE J1850";
CM_ SG_ 41 CODE_CLR_HCP "Clear emission related faults; 0= not clear 1= Clear";
CM_ SG_ 41 REPRGD_PFC_CLR_HCP "Set readiness to 'incomplete'; 0 = Do nothing; 1= Set incomplete";
CM_ SG_ 41 PropulsionMode "Propulsion mode of the vehicle";
CM_ SG_ 41 MC_123h "Message counter";
CM_ SG_ 41 CRC_123h "CRC-checksum byte 1 to 7 according to SAE J1850";
CM_ SG_ 43 LatAcceleration "Raw lateral acceleration";
CM_ SG_ 43 AXSStat "Longitudinal signal status";
CM_ SG_ 43 AYSStat "Latitudinal signal status";
CM_ SG_ 43 LongAcceleration "Raw longitudinal acceleration";
CM_ SG_ 43 YRSStat "Yaw rate signal status";
CM_ SG_ 43 InternalError "ORC ESC internal error; True = [1]";
CM_ SG_ 43 VoltageError "ORC ESC voltage error; True = [1]";
CM_ SG_ 43 YawRate "Raw yaw acceleration";
CM_ SG_ 43 MC_ORC_YRS_DATA "Message counter";
CM_ SG_ 43 CRC_ORC_YRS_DATA "CRC-checksum byte 1 to 7 according to SAE J1850";
CM_ SG_ 47 BrkPdlRawStat "Brake pedal state raw value";
CM_ SG_ 47 RAW_OBD_VEHACCEL_X "Raw vehicle acceleration in the X direction";
CM_ SG_ 53 EngTrqTgt_SEM "Target Torque  - trans trq. request";
CM_ SG_ 53 EngRdyForESS "Engine is ready for ESS action (1 = ready)";
CM_ SG_ 53 EngTrqStatic_SEM "Static engine torque - trans trq request";
CM_ SG_ 53 TRANS_CLU_SLIP_MODE "Clutch Slip Request Mode";
CM_ SG_ 53 ThrmlMngActv "Indicates ECM RPM Limitation Status, Active = 1";
CM_ SG_ 53 EngMaxRPM "Engine maximum RPM";
CM_ SG_ 53 ESS_ENG_ST "ESS Engine State";
CM_ SG_ 53 MC_ECM_A3 "Message counter";
CM_ SG_ 53 CRC_ECM_A3 "CRC-checksum byte 1 to 7 according to SAE J1850";
CM_ SG_ 53 EngStallSts "Engine stall status message";
CM_ SG_ 54 SumTrqTgt_SEM "Target Torque  - Transmission Torque Request";
CM_ SG_ 54 SumTrqStatic_SEM "Static Sum Torque - Transmission Torque Request";
CM_ SG_ 54 ExpSumTrq "Expected Sum Torque based on target  transmission input speed";
CM_ SG_ 54 MC_HCP_A2 "Message counter";
CM_ SG_ 54 CRC_HCP_A2 "CRC-checksum byte 1 to 7 according to SAE J1850";
CM_ SG_ 55 EngTrqRq "Requested engine torque";
CM_ SG_ 55 TrqCtrlModeRq "Torque control mode request";
CM_ SG_ 55 MaxTrqDes "Maximum engine torque desired";
CM_ SG_ 55 MC_TCM_EngTrq2 "Message counter";
CM_ SG_ 55 CRC_TCM_EngTrq2 "CRC-checksum byte 1 to 7 according to SAE J1850";
CM_ SG_ 56 SumTrqSel_D_TTC "Corrected (substitute) driver torque demand";
CM_ SG_ 56 SumTrq_DrvReqMod "Driver requested sum torque modifed";
CM_ SG_ 56 MotorB_Speed "Electric Motor Revolutions Per Minute, Initialization = 0xFFFE";
CM_ SG_ 56 MC_HCP_A3 "Message counter";
CM_ SG_ 56 CRC_HCP_A3 "CRC-checksum byte 1 to 6 according to SAE J1850";
CM_ SG_ 113 EngTrq_Rq_ESC "Engine torque request";
CM_ SG_ 113 DAS_Enbl_Rq "Enable DAS request; True = [1]";
CM_ SG_ 113 EngTrqMax_Rq_ESC "Engine torque request maximum";
CM_ SG_ 113 EngTrqMin_Rq_ESC "Engine torque request minimum";
CM_ SG_ 113 EngTrq_Rq_As "Engine torque request";
CM_ SG_ 113 ASRActive "Traction control is active";
CM_ SG_ 113 EngTrqMax_Rq_AS "Engine torque request maximum; True = [1]";
CM_ SG_ 113 BrkBstrVac "Brake Booster Vacuum Level";
CM_ SG_ 113 PrefillActive "Brake prefill is active - True = [1]";
CM_ SG_ 113 DsblFuelShutOff "Disable fuel shutoff; True = [1]";
CM_ SG_ 113 DAS_RqActv "DAS request active";
CM_ SG_ 113 Brk_Jrk_Rsp "Brake jerk response; True = [1]";
CM_ SG_ 113 MC_ENG_RQ_ESC "Message counter";
CM_ SG_ 113 CRC_ENG_RQ_ESC "CRC-checksum byte 1 to 7 according to SAE J1850";
CM_ SG_ 114 BrkTrq_ILE "Actual brake torque for ILE inetraction";
CM_ SG_ 114 MC_ESP_A11 "Message counter";
CM_ SG_ 114 CRC_ESP_A11 "CRC-checksum byte 1 to 7 according to SAE J1850";
CM_ SG_ 117 WhlTrq_Rq_As_2 "ACC torque request in wheel Domain.";
CM_ SG_ 117 WhlTrqAct_Rq_AS "Wheel torque request active; True = [1]";
CM_ SG_ 117 MC_10Eh "Message counter";
CM_ SG_ 117 CRC_10Eh "CRC-checksum byte 1 to 7 according to SAE J1850";
CM_ SG_ 119 CmdIgnStat "Commanded ignition switch status";
CM_ SG_ 119 StTyp "Type of start being requested";
CM_ SG_ 119 RemStActv "Ignition run active for remote start (0=not active, 1=active)";
CM_ SG_ 119 KeyInIgn "Key in ignition status";
CM_ SG_ 119 StartRelayBCMSts "CBC starter relay status; [1] = ON";
CM_ SG_ 119 StartRelayBCMFault "CBC starter relay fault detected";
CM_ SG_ 120 BrakeBoostPressure "Pressure Information from Brake Booster Pedal Pressure Sensor";
CM_ SG_ 120 BrakePedalPressure "Pressure Information from Brake Pedal Simulator Pressure Sensor";
CM_ SG_ 120 BrakePdlPosn "Brake pedal travel sensor 0-100% (0 = upstop)";
CM_ SG_ 120 BrakeBoostStat "Brake eBoost Status";
CM_ SG_ 120 BSMHybridModeReq "Hybrid Drive Mode Request";
CM_ SG_ 120 MC_ESP_A10 "Message counter";
CM_ SG_ 120 CRC_ESP_A10 "CRC-checksum byte 1 to 7 according to SAE J1850";
CM_ SG_ 121 BrkTrq "Actual brake torque";
CM_ SG_ 121 VehSpSts "Vehicle is stopped status signal";
CM_ SG_ 121 BrkTrq_D "Brake torque requested by driver";
CM_ SG_ 121 VEH_SPEED "Vehicle speed";
CM_ SG_ 121 MC_VEH_SPEED "Message counter";
CM_ SG_ 121 CRC_VEH_SPEED "CRC-checksum byte 1 to 7 according to SAE J1850";
CM_ SG_ 123 EngTrqSel_D_TTC "Corrected (substitute) driver torque demand";
CM_ SG_ 123 EngTrq_Enbl_Rq_AS "Allow LCM torque requests";
CM_ SG_ 123 EngTrq_Enbl_Rq_ESC "Allow ESC torque request";
CM_ SG_ 123 EngTrq_Enbl_Rq_TCM "Allow TRANS torque request";
CM_ SG_ 123 AccelPdlPosn "Throttle Pedal Position (Calculated)";
CM_ SG_ 123 EngTrq_DrvReqMod "Driver requested engine torque modifed";
CM_ SG_ 123 ECM_LHOM "Engine in limp home mode";
CM_ SG_ 123 AccelPdlPosnSens_Flt "Accelerator pedal position sensor fault";
CM_ SG_ 123 CRUISE_OVERRIDE "Driver is over-riding cruise set speed";
CM_ SG_ 123 ESS_RqShftPark "ESS Request shift to Park.  1 = True, 0 = False";
CM_ SG_ 123 RPMOverRev "RPM Overrev condition has occurred";
CM_ SG_ 123 LV12PwrFreeRq "Level 1 or 2 power free request - engine controller has depowered the throttle body";
CM_ SG_ 123 MC_ECM_A2 "Message counter";
CM_ SG_ 123 CRC_ECM_A2 "CRC-checksum byte 1 to 6 according to SAE J1850";
CM_ SG_ 124 EngTrq_Enbl_Rq_AS_PHEV "Allow LCM torque requests";
CM_ SG_ 124 EngTrq_Enbl_Rq_ESC_PHEV "Allow ESC torque request";
CM_ SG_ 124 EngTrq_Enbl_Rq_TCM_PHEV "Allow TRANS torque request";
CM_ SG_ 124 ECM_LHOM_PHEV "Engine in limp home mode";
CM_ SG_ 124 AccelPdlPosnSens_Flt_PHEV "Accelerator pedal position sensor fault";
CM_ SG_ 124 CRUISE_OVERRIDE_PHEV "Driver is over-riding cruise set speed";
CM_ SG_ 124 ESS_RqShftPark_PHEV "ESS Request shift to Park.  1 = True, 0 = False";
CM_ SG_ 124 RPMOverRev_PHEV "RPM Overrev condition has occurred";
CM_ SG_ 124 LV12PwrFreeRq_PHEV "Level 1 or 2 power free request - engine controller has depowered the throttle body";
CM_ SG_ 124 ECM_AllwEV_PHEV "ECM allow EV mode; 0 EV_not_allowed 1 EV_allowed";
CM_ SG_ 124 ECM_Comm_Fail_ePT "ECM_Comm_Fail_ePT";
CM_ SG_ 124 MC_ECM_A2_PHEV "Message counter";
CM_ SG_ 124 CRC_ECM_A2_PHEV "CRC-checksum byte 1 to 6 according to SAE J1850";
CM_ SG_ 125 KickDnSw_Psd "kick-down (change-over scenario open!)";
CM_ SG_ 125 TxAC_EMCC_rq "Transmission  AC converter clutch slip request; [1] = True";
CM_ SG_ 125 EngTrqMaxCorrFctr "Factor of reduction from max. torque";
CM_ SG_ 125 GrMin_Rq_ECM "Target gear lower limit (ECM requested limit)";
CM_ SG_ 125 GrMax_Rq_ECM "Target gear upper limit (ECM requested limit)";
CM_ SG_ 125 NMOTS "Target idle speed";
CM_ SG_ 127 WhlPlsCnt_FL "Wheel pulse counter front left (96 per rotation)";
CM_ SG_ 127 WhlPlsCnt_FR "Wheel pulse counter front right (96 per rotation)";
CM_ SG_ 127 WhlPlsCnt_RL "Wheel pulse counter rear left (96 per rotation)";
CM_ SG_ 127 WhlPlsCnt_RR "Wheel pulse counter rear right (96 per rotation)";
CM_ SG_ 127 CENT_DIFF_ESP_RQ "ESP Requested Center  Differential State";
CM_ SG_ 127 CENT_DIFF_TRQ_RQ "Desired Torque for Center Diff";
CM_ SG_ 129 SpeedLimitSts "Speed limiter status";
CM_ SG_ 129 CRUISE_EGD "Cruise system is controlling speed";
CM_ SG_ 129 CRUISE_ON "Cruise control system 'on'";
CM_ SG_ 129 V_MAX_TM "Max. or cruise control set speed";
CM_ SG_ 129 MAP_ENG "Intake manifold pressure, extended rangeEDR ONLY - Intake manifold pressure";
CM_ SG_ 129 BARO_ENG "Ambient air pressure (barometric pressure)";
CM_ SG_ 129 Rel_Thrt_ENG "Relative throttle value";
CM_ SG_ 129 Rel_Pdl_ENG "Relative pedal value";
CM_ SG_ 129 ECM_WARN "HMI warnings";
CM_ SG_ 131 Brk_Stat "Brake state";
CM_ SG_ 131 BrkPdl_Stat "Brake pedal state";
CM_ SG_ 131 BrkPdl_Flt "Brake Pedal Fault is active, 1=Faulted";
CM_ SG_ 131 BrkIntrvntn_Actv_ESP "Brake intervention by ESP active";
CM_ SG_ 131 BrkIntrvntn_Actv_AS "Brake intervention by assistance system active";
CM_ SG_ 131 BrkIntrvntn_Enbl "Brake intervention enabled";
CM_ SG_ 131 EmgBrk_Actv "Emergency braking";
CM_ SG_ 131 FullBrk_Actv "Maximum (hard) braking (ALS controls all wheels)";
CM_ SG_ 131 ESP_Sys_Stat "ESP system state";
CM_ SG_ 131 SelSpdSts "Select speed status";
CM_ SG_ 131 ABS_BrkEvt "Any ABS brake event";
CM_ SG_ 131 DTR_CC_Engaged "ACC is engaged; True = [1]";
CM_ SG_ 131 GrMin_Rq_ESC "Requested gear, lower limit";
CM_ SG_ 131 GrMax_Rq_ESC "Requested gear, upper limit";
CM_ SG_ 131 GrMinMax_Rq_DTR "Gear limit request from DTR";
CM_ SG_ 131 DTR_CC_Enabled "ACC is enabled; True = [1]";
CM_ SG_ 131 Brk_Thermdl "Brake thermal over target";
CM_ SG_ 131 ShftChrDsp_Rq_ESC "Shift characteristic displacement request";
CM_ SG_ 131 RollTestMd_Actv "Roller test bench mode active";
CM_ SG_ 131 REF_VEH_SPEED "Reference vehicle actual speed";
CM_ SG_ 131 SPCR_AS_Off_Rq "Assistance system off request";
CM_ SG_ 131 MC_Brk_Stat "Message counter";
CM_ SG_ 131 CRC_Brk_Stat "CRC-checksum byte 1 to 7 according to SAE J1850";
CM_ SG_ 131 HillHolderActive "HillHolderActive";
CM_ SG_ 133 K_STO_B "Conf. (torque converter lock-up) clutch 'starts to open'";
CM_ SG_ 133 GearSwitchActiveSts "Transmission shift in progress";
CM_ SG_ 133 EngSt_Enbl_Rq_TCM "Enable engine start request";
CM_ SG_ 133 Gr "Current Gear";
CM_ SG_ 133 Gr_Target "Target Gear";
CM_ SG_ 133 K_G_B "Conf. (torque converter lock-up) clutch 'closed'";
CM_ SG_ 133 K_O_B "Conf. (torque converter lock-up) clutch 'open'";
CM_ SG_ 133 K_S_B "Conf. (torque converter lock-up) clutch 'slip'";
CM_ SG_ 133 Trns_EMCC_Achvd "Trans A/C Converter Clutch Slipping; [1] = True";
CM_ SG_ 133 OUTPUT_SPEED "Output Shaft Speed";
CM_ SG_ 133 N_Turb "Unfiltered turbine speed (n_t_v)";
CM_ SG_ 133 OutputSpdPolarity "Output shaft speed polarity";
CM_ SG_ 133 TRNS_SPD_MC "TRNS_SPD message counter";
CM_ SG_ 133 TCM_ManMd "Transmission in manual mode";
CM_ SG_ 135 BrkPrss_TMC "Master cylinder pressure";
CM_ SG_ 135 HSA_BrkPrss "Hill start assist brake pressure";
CM_ SG_ 135 BrkBstrVac_OBD "Brake booster vacuum level, raw";
CM_ SG_ 135 MC_ESP_A3 "Message counter";
CM_ SG_ 135 CRC_ESP_A3 "CRC-checksum byte 1 to 7 according to SAE J1850";
CM_ SG_ 137 VehYawRate_Raw "Vehicle yaw rate unfiltered/unadjusted (+ means left)";
CM_ SG_ 137 VehYawRate_Offset "Offset of vehicle yaw rate unfiltered/unadjusted (+ means left)";
CM_ SG_ 137 VehAccel_X_Offset "Offset of vehicle longitudinal acceleration (+ means forward)";
CM_ SG_ 137 VehAccel_X "Vehicle longitudinal acceleration (+ means forward)";
CM_ SG_ 137 VehAccel_Y "Vehicle lateral acceleration (+ means left, specific to center of gravity, offset-corrected )";
CM_ SG_ 137 MC_VEH_DYN_STAT "Message counter";
CM_ SG_ 137 VehAccel_Y_Offset "Offset of vehicle lateral acceleration (+ means left)";
CM_ SG_ 139 WhlRPM_FL "Wheel rpm front left";
CM_ SG_ 139 WhlDir_FL_Stat "Direction of rotation of front left wheel";
CM_ SG_ 139 WhlRPM_FR "Wheel rpm front right";
CM_ SG_ 139 WhlDir_FR_Stat "Direction of rotation of front right wheel";
CM_ SG_ 139 WhlRPM_RL "Wheel rpm rear left";
CM_ SG_ 139 WhlDir_RL_Stat "Direction of rotation of rear left wheel";
CM_ SG_ 139 WhlRPM_RR "Wheel rpm rear right";
CM_ SG_ 139 WhlDir_RR_Stat "Direction of rotation of rear right wheel";
CM_ SG_ 141 ACT_CNT_DIF_TRQ "Actual center differential torque lock";
CM_ SG_ 141 DES_CNT_DIF_TRQ "Desired center differential torque lock";
CM_ SG_ 141 TCASERANGESTATUS "This signal is used for update the Transfer case Range status";
CM_ SG_ 141 TCASE_STAT "Transfer Case Status";
CM_ SG_ 141 SHFT_ABRT "Shift has been abortet";
CM_ SG_ 141 TCASE_2LO_STAT "Status of transfer case in 2WD LOW";
CM_ SG_ 145 DrvLnTrqRq "Drive line requested engine torque";
CM_ SG_ 145 DrvLnMinTrqMd "Drive line engine torque request: min.-mode";
CM_ SG_ 145 MC_DTCM_A2 "Message counter";
CM_ SG_ 145 CRC_DTCM_A2 "CRC-checksum byte 1 to 7 according to SAE J1850";
CM_ SG_ 145 FAD_STAT "Status of the FAD (Front Axle Disconnect)";
BA_DEF_ BO_  "App-Botschaft" ENUM  "nein","ja";
BA_DEF_ BO_  "CanMsgMinLen" INT 0 8;
BA_DEF_ BO_  "DiagRequest" ENUM  "nein","ja";
BA_DEF_ BO_  "DiagResponse" ENUM  "nein","ja";
BA_DEF_ BO_  "DiagState" ENUM  "nein","ja";
BA_DEF_ BO_  "GenMsgCycleTime" INT 0 65535;
BA_DEF_ BO_  "GenMsgCycleTimeActive" INT 0 65535;
BA_DEF_ BO_  "GenMsgDelayTime" INT 0 65535;
BA_DEF_ BO_  "GenMsgNrOfRepetitions" INT 0 65535;
BA_DEF_ BO_  "GenMsgSendType" ENUM  "cyclicX","spontanX","cyclicIfActiveX","spontanWithDelay","cyclicAndSpontanX","cyclicAndSpontanWithDelay","spontanWithRepitition","cyclicIfActiveAndSpontanWD","cyclicIfActiveFast","cyclicWithRepeatOnDemand","none";
BA_DEF_ BO_  "GenMsgStartDelayTime" INT 0 65535;
BA_DEF_ BO_  "GenMsgStartValue" STRING ;
BA_DEF_ BO_  "NWM-Botschaft" ENUM  "nein","ja";
BA_DEF_ BO_  "TpTxIndex" INT 0 99;
BA_DEF_  "Baudrate" INT 0 1000000;
BA_DEF_  "Manufacturer" ENUM  "DBAG","VAG","BMWAG","PAG","GM";
BA_DEF_  "NBTMax" INT 0 255;
BA_DEF_  "NBTMin" INT 0 255;
BA_DEF_  "NmMessageCount" INT 0 64;
BA_DEF_  "NWM-Basisadresse" HEX 0 536870911;
BA_DEF_  "NWM-Typ" ENUM  "zentral (MB-W210)","dezentral (MB-OSAN)","keines","VAG-OSEK","BMW-OSEK","PAG-OSEK","DBAG-OSEK";
BA_DEF_  "SamplePointMax" FLOAT 0 100;
BA_DEF_  "SamplePointMin" FLOAT 0 100;
BA_DEF_  "Version" HEX 0 4080;
BA_DEF_  "VersionWeek" INT 0 53;
BA_DEF_  "VersionYear" INT 0 99;
BA_DEF_ BU_  "NWM-Knoten" ENUM  "nein","ja";
BA_DEF_ BU_  "NWM-Stationsadresse" HEX 0 63;
BA_DEF_ BU_  "TpNodeBaseAddress" HEX 0 65535;
BA_DEF_ BU_  "TpOwnSystemEcuNumber" HEX 0 255;
BA_DEF_ SG_  "FlexKomComment" STRING ;
BA_DEF_ SG_  "FlexKomIsMotorola" ENUM  "nein","ja";
BA_DEF_ SG_  "FlexKomSID" INT 0 2147483647;
BA_DEF_ SG_  "FlexKomSigLaenge" INT 0 64;
BA_DEF_ SG_  "FlexKomSigName" STRING ;
BA_DEF_ SG_  "FlexKomSigStartPos" INT 0 63;
BA_DEF_ SG_  "FlexKomSigStartValue" STRING ;
BA_DEF_ SG_  "GenSigCycleTime" INT 0 65535;
BA_DEF_ SG_  "GenSigCycleTimeActive" INT 0 65535;
BA_DEF_ SG_  "GenSigSendType" ENUM  "cyclicX","spontanX","cyclicIfActiveX","spontanWithDelay","cyclicAndSpontanX","cyclicAndSpontanWithDelay","spontanWithRepitition","cyclicIfActiveAndSpontanWD","cyclicIfActiveFast","cyclicWithRepeatOnDemand","none";
BA_DEF_ SG_  "GenSigSNA" STRING ;
BA_DEF_ SG_  "GenSigStartValue" HEX 0 2147483648;
BA_DEF_ SG_  "GenSigTimeout_AHLM" INT 0 65535;
BA_DEF_ SG_  "GenSigTimeout_ASBS" INT 0 65535;
BA_DEF_ SG_  "GenSigTimeout_CBC" INT 0 65535;
BA_DEF_ SG_  "GenSigTimeout_DPDM" INT 0 65535;
BA_DEF_ SG_  "GenSigTimeout_DTCM" INT 0 65535;
BA_DEF_ SG_  "GenSigTimeout_EHPS" INT 0 65535;
BA_DEF_ SG_  "GenSigTimeout_ESC" INT 0 65535;
BA_DEF_ SG_  "GenSigTimeout_ESL" INT 0 65535;
BA_DEF_ SG_  "GenSigTimeout_ESM" INT 0 65535;
BA_DEF_ SG_  "GenSigTimeout_ETM" INT 0 65535;
BA_DEF_ SG_  "GenSigTimeout_IC" INT 0 65535;
BA_DEF_ SG_  "GenSigTimeout_OCM" INT 0 65535;
BA_DEF_ SG_  "GenSigTimeout_ORC" INT 0 65535;
BA_DEF_ SG_  "GenSigTimeout_PTS" INT 0 65535;
BA_DEF_ SG_  "GenSigTimeout_RF_HUB" INT 0 65535;
BA_DEF_ SG_  "GenSigTimeout_SCCM" INT 0 65535;
BA_DEF_ SG_  "GenSigTimeout_TBM" INT 0 65535;
BA_DEF_ SG_  "GenSigTimeout_TCM" INT 0 65535;
BA_DEF_ SG_  "GenSigTimeout_TPM" INT 0 65535;
BA_DEF_ SG_  "RID" STRING ;
BA_DEF_ SG_  "SystemSignalLongSymbol" STRING ;
BA_DEF_DEF_  "App-Botschaft" "nein";
BA_DEF_DEF_  "CanMsgMinLen" 0;
BA_DEF_DEF_  "DiagRequest" "nein";
BA_DEF_DEF_  "DiagResponse" "nein";
BA_DEF_DEF_  "DiagState" "nein";
BA_DEF_DEF_  "GenMsgCycleTime" 0;
BA_DEF_DEF_  "GenMsgCycleTimeActive" 0;
BA_DEF_DEF_  "GenMsgDelayTime" 0;
BA_DEF_DEF_  "GenMsgNrOfRepetitions" 0;
BA_DEF_DEF_  "GenMsgSendType" "cyclicX";
BA_DEF_DEF_  "GenMsgStartDelayTime" 0;
BA_DEF_DEF_  "GenMsgStartValue" "";
BA_DEF_DEF_  "NWM-Botschaft" "nein";
BA_DEF_DEF_  "TpTxIndex" 0;
BA_DEF_DEF_  "Baudrate" 500000;
BA_DEF_DEF_  "Manufacturer" "DBAG";
BA_DEF_DEF_  "NBTMax" 20;
BA_DEF_DEF_  "NBTMin" 10;
BA_DEF_DEF_  "NmMessageCount" 64;
BA_DEF_DEF_  "NWM-Basisadresse" 1024;
BA_DEF_DEF_  "NWM-Typ" "DBAG-OSEK";
BA_DEF_DEF_  "SamplePointMax" 81.25;
BA_DEF_DEF_  "SamplePointMin" 75;
BA_DEF_DEF_  "Version" 1;
BA_DEF_DEF_  "VersionWeek" 1;
BA_DEF_DEF_  "VersionYear" 23;
BA_DEF_DEF_  "NWM-Knoten" "nein";
BA_DEF_DEF_  "NWM-Stationsadresse" 0;
BA_DEF_DEF_  "TpNodeBaseAddress" 0;
BA_DEF_DEF_  "TpOwnSystemEcuNumber" 0;
BA_DEF_DEF_  "FlexKomComment" "";
BA_DEF_DEF_  "FlexKomIsMotorola" "nein";
BA_DEF_DEF_  "FlexKomSID" 0;
BA_DEF_DEF_  "FlexKomSigLaenge" 0;
BA_DEF_DEF_  "FlexKomSigName" "";
BA_DEF_DEF_  "FlexKomSigStartPos" 0;
BA_DEF_DEF_  "FlexKomSigStartValue" "";
BA_DEF_DEF_  "GenSigCycleTime" 0;
BA_DEF_DEF_  "GenSigCycleTimeActive" 0;
BA_DEF_DEF_  "GenSigSendType" "cyclicX";
BA_DEF_DEF_  "GenSigSNA" "";
BA_DEF_DEF_  "GenSigStartValue" 0;
BA_DEF_DEF_  "GenSigTimeout_AHLM" 0;
BA_DEF_DEF_  "GenSigTimeout_ASBS" 0;
BA_DEF_DEF_  "GenSigTimeout_CBC" 0;
BA_DEF_DEF_  "GenSigTimeout_DPDM" 0;
BA_DEF_DEF_  "GenSigTimeout_DTCM" 0;
BA_DEF_DEF_  "GenSigTimeout_EHPS" 0;
BA_DEF_DEF_  "GenSigTimeout_ESC" 0;
BA_DEF_DEF_  "GenSigTimeout_ESL" 0;
BA_DEF_DEF_  "GenSigTimeout_ESM" 0;
BA_DEF_DEF_  "GenSigTimeout_ETM" 0;
BA_DEF_DEF_  "GenSigTimeout_IC" 0;
BA_DEF_DEF_  "GenSigTimeout_OCM" 0;
BA_DEF_DEF_  "GenSigTimeout_ORC" 0;
BA_DEF_DEF_  "GenSigTimeout_PTS" 0;
BA_DEF_DEF_  "GenSigTimeout_RF_HUB" 0;
BA_DEF_DEF_  "GenSigTimeout_SCCM" 0;
BA_DEF_DEF_  "GenSigTimeout_TBM" 0;
BA_DEF_DEF_  "GenSigTimeout_TCM" 0;
BA_DEF_DEF_  "GenSigTimeout_TPM" 0;
BA_DEF_DEF_  "RID" "";
BA_DEF_DEF_  "SystemSignalLongSymbol" "";
BA_ "NWM-Stationsadresse" BU_ CBC 1;
BA_ "NWM-Knoten" BU_ CBC 1;
BA_ "NWM-Stationsadresse" BU_ EHPS 26;
BA_ "NWM-Knoten" BU_ EHPS 1;
BA_ "NWM-Stationsadresse" BU_ ESC 7;
BA_ "NWM-Knoten" BU_ ESC 1;
BA_ "NWM-Stationsadresse" BU_ ESL 8;
BA_ "NWM-Knoten" BU_ ESL 1;
BA_ "NWM-Stationsadresse" BU_ ESM 9;
BA_ "NWM-Knoten" BU_ ESM 1;
BA_ "NWM-Stationsadresse" BU_ EVCU2 58;
BA_ "NWM-Knoten" BU_ EVCU2 1;
BA_ "NWM-Stationsadresse" BU_ IC 2;
BA_ "NWM-Knoten" BU_ IC 1;
BA_ "NWM-Knoten" BU_ RF_HUB 1;
BA_ "NWM-Stationsadresse" BU_ SCCM 35;
BA_ "NWM-Knoten" BU_ SCCM 1;
BA_ "GenMsgStartValue" BO_ 35 "3FFF3FFF030000FFh";
BA_ "GenMsgNrOfRepetitions" BO_ 35 2;
BA_ "GenMsgDelayTime" BO_ 35 20;
BA_ "GenMsgCycleTime" BO_ 35 10;
BA_ "GenMsgStartValue" BO_ 37 "FFFF1FFF1FFF00FFh";
BA_ "GenMsgNrOfRepetitions" BO_ 37 2;
BA_ "GenMsgDelayTime" BO_ 37 20;
BA_ "GenMsgCycleTime" BO_ 37 10;
BA_ "GenMsgStartValue" BO_ 38 "FFFFFF00201E00FFh";
BA_ "GenMsgNrOfRepetitions" BO_ 38 2;
BA_ "GenMsgDelayTime" BO_ 38 20;
BA_ "GenMsgCycleTime" BO_ 38 10;
BA_ "GenMsgStartValue" BO_ 39 "9FFF1FFF1FFF00FFh";
BA_ "GenMsgNrOfRepetitions" BO_ 39 2;
BA_ "GenMsgDelayTime" BO_ 39 20;
BA_ "GenMsgCycleTime" BO_ 39 10;
BA_ "GenMsgStartValue" BO_ 40 "1FFF1FFF1FFF00FFh";
BA_ "GenMsgNrOfRepetitions" BO_ 40 2;
BA_ "GenMsgDelayTime" BO_ 40 20;
BA_ "GenMsgCycleTime" BO_ 40 10;
BA_ "GenMsgStartValue" BO_ 41 "00000000000000FFh";
BA_ "GenMsgNrOfRepetitions" BO_ 41 2;
BA_ "GenMsgDelayTime" BO_ 41 20;
BA_ "GenMsgCycleTime" BO_ 41 10;
BA_ "GenMsgStartValue" BO_ 43 "000000000FFF00FFh";
BA_ "GenMsgNrOfRepetitions" BO_ 43 2;
BA_ "GenMsgDelayTime" BO_ 43 20;
BA_ "GenMsgCycleTime" BO_ 43 10;
BA_ "GenMsgStartValue" BO_ 47 "FFFFFFFF00000000h";
BA_ "GenMsgNrOfRepetitions" BO_ 47 2;
BA_ "GenMsgDelayTime" BO_ 47 20;
BA_ "GenMsgCycleTime" BO_ 47 10;
BA_ "GenMsgStartValue" BO_ 53 "5FFF1FFF00FF0FFFh";
BA_ "GenMsgNrOfRepetitions" BO_ 53 2;
BA_ "GenMsgDelayTime" BO_ 53 20;
BA_ "GenMsgCycleTime" BO_ 53 10;
BA_ "GenMsgStartValue" BO_ 54 "1FFF1FFF1FFF00FFh";
BA_ "GenMsgNrOfRepetitions" BO_ 54 2;
BA_ "GenMsgDelayTime" BO_ 54 20;
BA_ "GenMsgCycleTime" BO_ 54 10;
BA_ "GenMsgStartValue" BO_ 55 "1FFF1FFF1FFF00FFh";
BA_ "GenMsgNrOfRepetitions" BO_ 55 2;
BA_ "GenMsgDelayTime" BO_ 55 20;
BA_ "GenMsgCycleTime" BO_ 55 10;
BA_ "GenMsgStartValue" BO_ 56 "1FFF1FFFFFFE00FFh";
BA_ "GenMsgNrOfRepetitions" BO_ 56 2;
BA_ "GenMsgDelayTime" BO_ 56 20;
BA_ "GenMsgCycleTime" BO_ 56 10;
BA_ "GenMsgStartValue" BO_ 113 "00000000FF0000FFh";
BA_ "GenMsgNrOfRepetitions" BO_ 113 2;
BA_ "GenMsgDelayTime" BO_ 113 20;
BA_ "GenMsgCycleTime" BO_ 113 20;
BA_ "GenMsgStartValue" BO_ 114 "00000000000000FFh";
BA_ "GenMsgNrOfRepetitions" BO_ 114 2;
BA_ "GenMsgDelayTime" BO_ 114 20;
BA_ "GenMsgCycleTime" BO_ 114 20;
BA_ "GenMsgStartValue" BO_ 117 "00000000000000FFh";
BA_ "GenMsgNrOfRepetitions" BO_ 117 2;
BA_ "GenMsgDelayTime" BO_ 117 20;
BA_ "GenMsgCycleTime" BO_ 117 20;
BA_ "GenMsgStartValue" BO_ 119 "0000h";
BA_ "GenMsgNrOfRepetitions" BO_ 119 2;
BA_ "GenMsgDelayTime" BO_ 119 20;
BA_ "GenMsgCycleTime" BO_ 119 20;
BA_ "GenMsgStartValue" BO_ 120 "00000000000000FFh";
BA_ "GenMsgNrOfRepetitions" BO_ 120 2;
BA_ "GenMsgDelayTime" BO_ 120 20;
BA_ "GenMsgCycleTime" BO_ 120 20;
BA_ "GenMsgStartValue" BO_ 121 "0FFF0FFFFFFF00FFh";
BA_ "GenMsgNrOfRepetitions" BO_ 121 2;
BA_ "GenMsgDelayTime" BO_ 121 20;
BA_ "GenMsgCycleTime" BO_ 121 20;
BA_ "GenMsgStartValue" BO_ 123 "1FFFFF1FFF00FFh";
BA_ "GenMsgNrOfRepetitions" BO_ 123 2;
BA_ "GenMsgDelayTime" BO_ 123 20;
BA_ "GenMsgCycleTime" BO_ 123 20;
BA_ "GenMsgStartValue" BO_ 124 "FF0000001FFF00FFh";
BA_ "GenMsgNrOfRepetitions" BO_ 124 2;
BA_ "GenMsgDelayTime" BO_ 124 20;
BA_ "GenMsgCycleTime" BO_ 124 20;
BA_ "GenMsgStartValue" BO_ 125 "00FF000FFFFFh";
BA_ "GenMsgNrOfRepetitions" BO_ 125 2;
BA_ "GenMsgDelayTime" BO_ 125 20;
BA_ "GenMsgCycleTime" BO_ 125 20;
BA_ "GenMsgStartValue" BO_ 127 "0000000000FFFFFFh";
BA_ "GenMsgNrOfRepetitions" BO_ 127 2;
BA_ "GenMsgDelayTime" BO_ 127 20;
BA_ "GenMsgCycleTime" BO_ 127 20;
BA_ "GenMsgStartValue" BO_ 129 "08FFFF00FFFF00FFh";
BA_ "GenMsgNrOfRepetitions" BO_ 129 2;
BA_ "GenMsgDelayTime" BO_ 129 20;
BA_ "GenMsgCycleTime" BO_ 129 20;
BA_ "GenMsgStartValue" BO_ 131 "0F3400C003FF00FFh";
BA_ "GenMsgNrOfRepetitions" BO_ 131 2;
BA_ "GenMsgDelayTime" BO_ 131 20;
BA_ "GenMsgCycleTime" BO_ 131 20;
BA_ "GenMsgStartValue" BO_ 133 "00FF00FFFFFFFF00h";
BA_ "GenMsgNrOfRepetitions" BO_ 133 2;
BA_ "GenMsgDelayTime" BO_ 133 20;
BA_ "GenMsgCycleTime" BO_ 133 20;
BA_ "GenMsgStartValue" BO_ 135 "7000FFFF00FF00FFh";
BA_ "GenMsgNrOfRepetitions" BO_ 135 2;
BA_ "GenMsgDelayTime" BO_ 135 20;
BA_ "GenMsgCycleTime" BO_ 135 20;
BA_ "GenMsgStartValue" BO_ 137 "FFFFFFFFFFFF00FFh";
BA_ "GenMsgNrOfRepetitions" BO_ 137 2;
BA_ "GenMsgDelayTime" BO_ 137 20;
BA_ "GenMsgCycleTime" BO_ 137 20;
BA_ "GenMsgStartValue" BO_ 139 "FFFFFFFFFFFFFFFFh";
BA_ "GenMsgNrOfRepetitions" BO_ 139 2;
BA_ "GenMsgDelayTime" BO_ 139 20;
BA_ "GenMsgCycleTime" BO_ 139 20;
BA_ "GenMsgStartValue" BO_ 141 "CEC0FFFFFFFFFFFFh";
BA_ "GenMsgNrOfRepetitions" BO_ 141 2;
BA_ "GenMsgDelayTime" BO_ 141 20;
BA_ "GenMsgCycleTime" BO_ 141 20;
BA_ "GenMsgStartValue" BO_ 145 "01FF7F00000000FFh";
BA_ "GenMsgNrOfRepetitions" BO_ 145 2;
BA_ "GenMsgDelayTime" BO_ 145 20;
BA_ "GenMsgCycleTime" BO_ 145 20;
BA_ "GenSigTimeout_ORC" SG_ 35 CRC_STW_Angle_STAT 35;
BA_ "GenSigTimeout_ETM" SG_ 35 CRC_STW_Angle_STAT 105;
BA_ "GenSigStartValue" SG_ 35 CRC_STW_Angle_STAT 255;
BA_ "GenSigSNA" SG_ 35 CRC_STW_Angle_STAT "FFh";
BA_ "GenSigCycleTime" SG_ 35 CRC_STW_Angle_STAT 10;
BA_ "FlexKomSigStartValue" SG_ 35 CRC_STW_Angle_STAT "3FFF3FFF030000FFh";
BA_ "FlexKomSigStartPos" SG_ 35 CRC_STW_Angle_STAT 7;
BA_ "FlexKomSigName" SG_ 35 CRC_STW_Angle_STAT "LRW_ST";
BA_ "FlexKomSigLaenge" SG_ 35 CRC_STW_Angle_STAT 64;
BA_ "FlexKomSID" SG_ 35 CRC_STW_Angle_STAT 418;
BA_ "FlexKomIsMotorola" SG_ 35 CRC_STW_Angle_STAT 1;
BA_ "FlexKomComment" SG_ 35 CRC_STW_Angle_STAT "Steering wheel angle state";
BA_ "RID" SG_ 35 LRW "1020 1197";
BA_ "GenSigTimeout_ORC" SG_ 35 LRW 35;
BA_ "GenSigTimeout_IC" SG_ 35 LRW 105;
BA_ "GenSigTimeout_EHPS" SG_ 35 LRW 105;
BA_ "GenSigTimeout_DTCM" SG_ 35 LRW 105;
BA_ "GenSigTimeout_CBC" SG_ 35 LRW 105;
BA_ "GenSigStartValue" SG_ 35 LRW 16383;
BA_ "GenSigSNA" SG_ 35 LRW "3FFFh";
BA_ "GenSigCycleTime" SG_ 35 LRW 10;
BA_ "FlexKomSigStartValue" SG_ 35 LRW "3FFF3FFF030000FFh";
BA_ "FlexKomSigStartPos" SG_ 35 LRW 7;
BA_ "FlexKomSigName" SG_ 35 LRW "LRW_ST";
BA_ "FlexKomSigLaenge" SG_ 35 LRW 64;
BA_ "FlexKomSID" SG_ 35 LRW 418;
BA_ "FlexKomIsMotorola" SG_ 35 LRW 1;
BA_ "FlexKomComment" SG_ 35 LRW "Steering wheel angle state";
BA_ "RID" SG_ 35 LRW_PLRTY "5030";
BA_ "GenSigTimeout_ORC" SG_ 35 LRW_PLRTY 35;
BA_ "GenSigTimeout_ETM" SG_ 35 LRW_PLRTY 105;
BA_ "GenSigTimeout_DTCM" SG_ 35 LRW_PLRTY 105;
BA_ "GenSigSNA" SG_ 35 LRW_PLRTY "0h";
BA_ "GenSigCycleTime" SG_ 35 LRW_PLRTY 10;
BA_ "FlexKomSigStartValue" SG_ 35 LRW_PLRTY "3FFF3FFF030000FFh";
BA_ "FlexKomSigStartPos" SG_ 35 LRW_PLRTY 7;
BA_ "FlexKomSigName" SG_ 35 LRW_PLRTY "LRW_ST";
BA_ "FlexKomSigLaenge" SG_ 35 LRW_PLRTY 64;
BA_ "FlexKomSID" SG_ 35 LRW_PLRTY 418;
BA_ "FlexKomIsMotorola" SG_ 35 LRW_PLRTY 1;
BA_ "FlexKomComment" SG_ 35 LRW_PLRTY "Steering wheel angle state";
BA_ "GenSigTimeout_ORC" SG_ 35 VLRW 35;
BA_ "GenSigTimeout_ETM" SG_ 35 VLRW 105;
BA_ "GenSigTimeout_EHPS" SG_ 35 VLRW 105;
BA_ "GenSigTimeout_DTCM" SG_ 35 VLRW 105;
BA_ "GenSigStartValue" SG_ 35 VLRW 16383;
BA_ "GenSigSNA" SG_ 35 VLRW "3FFFh";
BA_ "GenSigCycleTime" SG_ 35 VLRW 10;
BA_ "FlexKomSigStartValue" SG_ 35 VLRW "3FFF3FFF030000FFh";
BA_ "FlexKomSigStartPos" SG_ 35 VLRW 7;
BA_ "FlexKomSigName" SG_ 35 VLRW "LRW_ST";
BA_ "FlexKomSigLaenge" SG_ 35 VLRW 64;
BA_ "FlexKomSID" SG_ 35 VLRW 418;
BA_ "FlexKomIsMotorola" SG_ 35 VLRW 1;
BA_ "FlexKomComment" SG_ 35 VLRW "Steering wheel angle state";
BA_ "RID" SG_ 35 LRWS_ST "1206";
BA_ "GenSigTimeout_ORC" SG_ 35 LRWS_ST 35;
BA_ "GenSigTimeout_ETM" SG_ 35 LRWS_ST 105;
BA_ "GenSigTimeout_DTCM" SG_ 35 LRWS_ST 105;
BA_ "GenSigStartValue" SG_ 35 LRWS_ST 3;
BA_ "GenSigSNA" SG_ 35 LRWS_ST "3h";
BA_ "GenSigCycleTime" SG_ 35 LRWS_ST 10;
BA_ "FlexKomSigStartValue" SG_ 35 LRWS_ST "3FFF3FFF030000FFh";
BA_ "FlexKomSigStartPos" SG_ 35 LRWS_ST 7;
BA_ "FlexKomSigName" SG_ 35 LRWS_ST "LRW_ST";
BA_ "FlexKomSigLaenge" SG_ 35 LRWS_ST 64;
BA_ "FlexKomSID" SG_ 35 LRWS_ST 418;
BA_ "FlexKomIsMotorola" SG_ 35 LRWS_ST 1;
BA_ "FlexKomComment" SG_ 35 LRWS_ST "Steering wheel angle state";
BA_ "GenSigTimeout_ETM" SG_ 35 Pad_Shft 105;
BA_ "GenSigSNA" SG_ 35 Pad_Shft "7h";
BA_ "GenSigCycleTime" SG_ 35 Pad_Shft 10;
BA_ "FlexKomSigStartValue" SG_ 35 Pad_Shft "3FFF3FFF030000FFh";
BA_ "FlexKomSigStartPos" SG_ 35 Pad_Shft 7;
BA_ "FlexKomSigName" SG_ 35 Pad_Shft "LRW_ST";
BA_ "FlexKomSigLaenge" SG_ 35 Pad_Shft 64;
BA_ "FlexKomSID" SG_ 35 Pad_Shft 418;
BA_ "FlexKomIsMotorola" SG_ 35 Pad_Shft 1;
BA_ "FlexKomComment" SG_ 35 Pad_Shft "Steering wheel angle state";
BA_ "GenSigTimeout_ETM" SG_ 35 LRW_RHP 105;
BA_ "GenSigTimeout_EHPS" SG_ 35 LRW_RHP 105;
BA_ "GenSigSNA" SG_ 35 LRW_RHP "0h";
BA_ "GenSigCycleTime" SG_ 35 LRW_RHP 10;
BA_ "FlexKomSigStartValue" SG_ 35 LRW_RHP "3FFF3FFF030000FFh";
BA_ "FlexKomSigStartPos" SG_ 35 LRW_RHP 7;
BA_ "FlexKomSigName" SG_ 35 LRW_RHP "LRW_ST";
BA_ "FlexKomSigLaenge" SG_ 35 LRW_RHP 64;
BA_ "FlexKomSID" SG_ 35 LRW_RHP 418;
BA_ "FlexKomIsMotorola" SG_ 35 LRW_RHP 1;
BA_ "FlexKomComment" SG_ 35 LRW_RHP "Steering wheel angle state";
BA_ "GenSigTimeout_ORC" SG_ 35 MC_STW_Angle_STAT 35;
BA_ "GenSigTimeout_ETM" SG_ 35 MC_STW_Angle_STAT 105;
BA_ "GenSigSNA" SG_ 35 MC_STW_Angle_STAT "0h";
BA_ "GenSigCycleTime" SG_ 35 MC_STW_Angle_STAT 10;
BA_ "FlexKomSigStartValue" SG_ 35 MC_STW_Angle_STAT "3FFF3FFF030000FFh";
BA_ "FlexKomSigStartPos" SG_ 35 MC_STW_Angle_STAT 7;
BA_ "FlexKomSigName" SG_ 35 MC_STW_Angle_STAT "LRW_ST";
BA_ "FlexKomSigLaenge" SG_ 35 MC_STW_Angle_STAT 64;
BA_ "FlexKomSID" SG_ 35 MC_STW_Angle_STAT 418;
BA_ "FlexKomIsMotorola" SG_ 35 MC_STW_Angle_STAT 1;
BA_ "FlexKomComment" SG_ 35 MC_STW_Angle_STAT "Steering wheel angle state";
BA_ "RID" SG_ 37 EngRPM "2185";
BA_ "GenSigTimeout_TCM" SG_ 37 EngRPM 105;
BA_ "GenSigTimeout_ORC" SG_ 37 EngRPM 35;
BA_ "GenSigTimeout_IC" SG_ 37 EngRPM 105;
BA_ "GenSigTimeout_ESM" SG_ 37 EngRPM 105;
BA_ "GenSigTimeout_EHPS" SG_ 37 EngRPM 105;
BA_ "GenSigTimeout_DTCM" SG_ 37 EngRPM 105;
BA_ "GenSigTimeout_CBC" SG_ 37 EngRPM 105;
BA_ "GenSigStartValue" SG_ 37 EngRPM 65535;
BA_ "GenSigSNA" SG_ 37 EngRPM "FFFFh";
BA_ "GenSigCycleTime" SG_ 37 EngRPM 10;
BA_ "FlexKomSigStartValue" SG_ 37 EngRPM "FFFF1FFF1FFF00FFh";
BA_ "FlexKomSigStartPos" SG_ 37 EngRPM 7;
BA_ "FlexKomSigName" SG_ 37 EngRPM "ECM_A1_PKT";
BA_ "FlexKomSigLaenge" SG_ 37 EngRPM 64;
BA_ "FlexKomSID" SG_ 37 EngRPM 446;
BA_ "FlexKomIsMotorola" SG_ 37 EngRPM 1;
BA_ "FlexKomComment" SG_ 37 EngRPM "ECM_A1 Packet";
BA_ "RID" SG_ 37 EngTrqStatic "2184";
BA_ "GenSigTimeout_TCM" SG_ 37 EngTrqStatic 105;
BA_ "GenSigTimeout_IC" SG_ 37 EngTrqStatic 105;
BA_ "GenSigTimeout_DTCM" SG_ 37 EngTrqStatic 105;
BA_ "GenSigTimeout_CBC" SG_ 37 EngTrqStatic 105;
BA_ "GenSigStartValue" SG_ 37 EngTrqStatic 8191;
BA_ "GenSigSNA" SG_ 37 EngTrqStatic "1FFFh";
BA_ "GenSigCycleTime" SG_ 37 EngTrqStatic 10;
BA_ "FlexKomSigStartValue" SG_ 37 EngTrqStatic "FFFF1FFF1FFF00FFh";
BA_ "FlexKomSigStartPos" SG_ 37 EngTrqStatic 7;
BA_ "FlexKomSigName" SG_ 37 EngTrqStatic "ECM_A1_PKT";
BA_ "FlexKomSigLaenge" SG_ 37 EngTrqStatic 64;
BA_ "FlexKomSID" SG_ 37 EngTrqStatic 446;
BA_ "FlexKomIsMotorola" SG_ 37 EngTrqStatic 1;
BA_ "FlexKomComment" SG_ 37 EngTrqStatic "ECM_A1 Packet";
BA_ "GenSigTimeout_DTCM" SG_ 37 ExpEngTrq 105;
BA_ "GenSigStartValue" SG_ 37 ExpEngTrq 8191;
BA_ "GenSigSNA" SG_ 37 ExpEngTrq "1FFFh";
BA_ "GenSigCycleTime" SG_ 37 ExpEngTrq 10;
BA_ "FlexKomSigStartValue" SG_ 37 ExpEngTrq "FFFF1FFF1FFF00FFh";
BA_ "FlexKomSigStartPos" SG_ 37 ExpEngTrq 7;
BA_ "FlexKomSigName" SG_ 37 ExpEngTrq "ECM_A1_PKT";
BA_ "FlexKomSigLaenge" SG_ 37 ExpEngTrq 64;
BA_ "FlexKomSID" SG_ 37 ExpEngTrq 446;
BA_ "FlexKomIsMotorola" SG_ 37 ExpEngTrq 1;
BA_ "FlexKomComment" SG_ 37 ExpEngTrq "ECM_A1 Packet";
BA_ "GenSigSNA" SG_ 37 MC_ECM_A1 "0h";
BA_ "GenSigCycleTime" SG_ 37 MC_ECM_A1 10;
BA_ "FlexKomSigStartValue" SG_ 37 MC_ECM_A1 "FFFF1FFF1FFF00FFh";
BA_ "FlexKomSigStartPos" SG_ 37 MC_ECM_A1 7;
BA_ "FlexKomSigName" SG_ 37 MC_ECM_A1 "ECM_A1_PKT";
BA_ "FlexKomSigLaenge" SG_ 37 MC_ECM_A1 64;
BA_ "FlexKomSID" SG_ 37 MC_ECM_A1 446;
BA_ "FlexKomIsMotorola" SG_ 37 MC_ECM_A1 1;
BA_ "FlexKomComment" SG_ 37 MC_ECM_A1 "ECM_A1 Packet";
BA_ "GenSigStartValue" SG_ 37 CRC_ECM_A1 255;
BA_ "GenSigSNA" SG_ 37 CRC_ECM_A1 "FFh";
BA_ "GenSigCycleTime" SG_ 37 CRC_ECM_A1 10;
BA_ "FlexKomSigStartValue" SG_ 37 CRC_ECM_A1 "FFFF1FFF1FFF00FFh";
BA_ "FlexKomSigStartPos" SG_ 37 CRC_ECM_A1 7;
BA_ "FlexKomSigName" SG_ 37 CRC_ECM_A1 "ECM_A1_PKT";
BA_ "FlexKomSigLaenge" SG_ 37 CRC_ECM_A1 64;
BA_ "FlexKomSID" SG_ 37 CRC_ECM_A1 446;
BA_ "FlexKomIsMotorola" SG_ 37 CRC_ECM_A1 1;
BA_ "FlexKomComment" SG_ 37 CRC_ECM_A1 "ECM_A1 Packet";
BA_ "GenSigSNA" SG_ 37 ECM_LHOM_Trans "0h";
BA_ "GenSigCycleTime" SG_ 37 ECM_LHOM_Trans 10;
BA_ "FlexKomSigStartValue" SG_ 37 ECM_LHOM_Trans "FFFF1FFF1FFF00FFh";
BA_ "FlexKomSigStartPos" SG_ 37 ECM_LHOM_Trans 7;
BA_ "FlexKomSigName" SG_ 37 ECM_LHOM_Trans "ECM_A1_PKT";
BA_ "FlexKomSigLaenge" SG_ 37 ECM_LHOM_Trans 64;
BA_ "FlexKomSID" SG_ 37 ECM_LHOM_Trans 446;
BA_ "FlexKomIsMotorola" SG_ 37 ECM_LHOM_Trans 1;
BA_ "FlexKomComment" SG_ 37 ECM_LHOM_Trans "ECM_A1 Packet";
BA_ "RID" SG_ 38 EngRPM_PHEV "2185";
BA_ "GenSigTimeout_TCM" SG_ 38 EngRPM_PHEV 105;
BA_ "GenSigTimeout_ORC" SG_ 38 EngRPM_PHEV 35;
BA_ "GenSigTimeout_IC" SG_ 38 EngRPM_PHEV 105;
BA_ "GenSigTimeout_ESM" SG_ 38 EngRPM_PHEV 105;
BA_ "GenSigTimeout_EHPS" SG_ 38 EngRPM_PHEV 105;
BA_ "GenSigTimeout_DTCM" SG_ 38 EngRPM_PHEV 105;
BA_ "GenSigTimeout_CBC" SG_ 38 EngRPM_PHEV 105;
BA_ "GenSigStartValue" SG_ 38 EngRPM_PHEV 65535;
BA_ "GenSigSNA" SG_ 38 EngRPM_PHEV "FFFFh";
BA_ "GenSigCycleTime" SG_ 38 EngRPM_PHEV 10;
BA_ "FlexKomSigStartValue" SG_ 38 EngRPM_PHEV "FFFFFF00201E00FFh";
BA_ "FlexKomSigStartPos" SG_ 38 EngRPM_PHEV 7;
BA_ "FlexKomSigName" SG_ 38 EngRPM_PHEV "ECM_A1_PHEV_PKT";
BA_ "FlexKomSigLaenge" SG_ 38 EngRPM_PHEV 64;
BA_ "FlexKomSID" SG_ 38 EngRPM_PHEV 2992;
BA_ "FlexKomIsMotorola" SG_ 38 EngRPM_PHEV 1;
BA_ "FlexKomComment" SG_ 38 EngRPM_PHEV "ECM_A1_PHEV_PKT";
BA_ "GenSigSNA" SG_ 38 ECM_LHOM_Trans_PHEV "0h";
BA_ "GenSigCycleTime" SG_ 38 ECM_LHOM_Trans_PHEV 10;
BA_ "FlexKomSigStartValue" SG_ 38 ECM_LHOM_Trans_PHEV "FFFFFF00201E00FFh";
BA_ "FlexKomSigStartPos" SG_ 38 ECM_LHOM_Trans_PHEV 7;
BA_ "FlexKomSigName" SG_ 38 ECM_LHOM_Trans_PHEV "ECM_A1_PHEV_PKT";
BA_ "FlexKomSigLaenge" SG_ 38 ECM_LHOM_Trans_PHEV 64;
BA_ "FlexKomSID" SG_ 38 ECM_LHOM_Trans_PHEV 2992;
BA_ "FlexKomIsMotorola" SG_ 38 ECM_LHOM_Trans_PHEV 1;
BA_ "FlexKomComment" SG_ 38 ECM_LHOM_Trans_PHEV "ECM_A1_PHEV_PKT";
BA_ "RID" SG_ 38 ThrmlMngActv_PHEV "1613";
BA_ "GenSigSNA" SG_ 38 ThrmlMngActv_PHEV "0h";
BA_ "GenSigCycleTime" SG_ 38 ThrmlMngActv_PHEV 10;
BA_ "FlexKomSigStartValue" SG_ 38 ThrmlMngActv_PHEV "FFFFFF00201E00FFh";
BA_ "FlexKomSigStartPos" SG_ 38 ThrmlMngActv_PHEV 7;
BA_ "FlexKomSigName" SG_ 38 ThrmlMngActv_PHEV "ECM_A1_PHEV_PKT";
BA_ "FlexKomSigLaenge" SG_ 38 ThrmlMngActv_PHEV 64;
BA_ "FlexKomSID" SG_ 38 ThrmlMngActv_PHEV 2992;
BA_ "FlexKomIsMotorola" SG_ 38 ThrmlMngActv_PHEV 1;
BA_ "FlexKomComment" SG_ 38 ThrmlMngActv_PHEV "ECM_A1_PHEV_PKT";
BA_ "GenSigStartValue" SG_ 38 EngMaxRPM_PHEV 255;
BA_ "GenSigSNA" SG_ 38 EngMaxRPM_PHEV "FFh";
BA_ "GenSigCycleTime" SG_ 38 EngMaxRPM_PHEV 10;
BA_ "FlexKomSigStartValue" SG_ 38 EngMaxRPM_PHEV "FFFFFF00201E00FFh";
BA_ "FlexKomSigStartPos" SG_ 38 EngMaxRPM_PHEV 7;
BA_ "FlexKomSigName" SG_ 38 EngMaxRPM_PHEV "ECM_A1_PHEV_PKT";
BA_ "FlexKomSigLaenge" SG_ 38 EngMaxRPM_PHEV 64;
BA_ "FlexKomSID" SG_ 38 EngMaxRPM_PHEV 2992;
BA_ "FlexKomIsMotorola" SG_ 38 EngMaxRPM_PHEV 1;
BA_ "FlexKomComment" SG_ 38 EngMaxRPM_PHEV "ECM_A1_PHEV_PKT";
BA_ "RID" SG_ 38 ESS_ENG_ST_PHEV "1653";
BA_ "GenSigTimeout_RF_HUB" SG_ 38 ESS_ENG_ST_PHEV 105;
BA_ "GenSigTimeout_ORC" SG_ 38 ESS_ENG_ST_PHEV 35;
BA_ "GenSigTimeout_CBC" SG_ 38 ESS_ENG_ST_PHEV 105;
BA_ "GenSigStartValue" SG_ 38 ESS_ENG_ST_PHEV 15;
BA_ "GenSigSNA" SG_ 38 ESS_ENG_ST_PHEV "Fh";
BA_ "GenSigCycleTime" SG_ 38 ESS_ENG_ST_PHEV 10;
BA_ "FlexKomSigStartValue" SG_ 38 ESS_ENG_ST_PHEV "FFFFFF00201E00FFh";
BA_ "FlexKomSigStartPos" SG_ 38 ESS_ENG_ST_PHEV 7;
BA_ "FlexKomSigName" SG_ 38 ESS_ENG_ST_PHEV "ECM_A1_PHEV_PKT";
BA_ "FlexKomSigLaenge" SG_ 38 ESS_ENG_ST_PHEV 64;
BA_ "FlexKomSID" SG_ 38 ESS_ENG_ST_PHEV 2992;
BA_ "FlexKomIsMotorola" SG_ 38 ESS_ENG_ST_PHEV 1;
BA_ "FlexKomComment" SG_ 38 ESS_ENG_ST_PHEV "ECM_A1_PHEV_PKT";
BA_ "GenSigTimeout_CBC" SG_ 38 ANL_LFT_PHEV 105;
BA_ "GenSigSNA" SG_ 38 ANL_LFT_PHEV "0h";
BA_ "GenSigCycleTime" SG_ 38 ANL_LFT_PHEV 10;
BA_ "FlexKomSigStartValue" SG_ 38 ANL_LFT_PHEV "FFFFFF00201E00FFh";
BA_ "FlexKomSigStartPos" SG_ 38 ANL_LFT_PHEV 7;
BA_ "FlexKomSigName" SG_ 38 ANL_LFT_PHEV "ECM_A1_PHEV_PKT";
BA_ "FlexKomSigLaenge" SG_ 38 ANL_LFT_PHEV 64;
BA_ "FlexKomSID" SG_ 38 ANL_LFT_PHEV 2992;
BA_ "FlexKomIsMotorola" SG_ 38 ANL_LFT_PHEV 1;
BA_ "FlexKomComment" SG_ 38 ANL_LFT_PHEV "ECM_A1_PHEV_PKT";
BA_ "RID" SG_ 38 FullOFC_Actv_PHEV "1822";
BA_ "GenSigSNA" SG_ 38 FullOFC_Actv_PHEV "0h";
BA_ "GenSigCycleTime" SG_ 38 FullOFC_Actv_PHEV 10;
BA_ "FlexKomSigStartValue" SG_ 38 FullOFC_Actv_PHEV "FFFFFF00201E00FFh";
BA_ "FlexKomSigStartPos" SG_ 38 FullOFC_Actv_PHEV 7;
BA_ "FlexKomSigName" SG_ 38 FullOFC_Actv_PHEV "ECM_A1_PHEV_PKT";
BA_ "FlexKomSigLaenge" SG_ 38 FullOFC_Actv_PHEV 64;
BA_ "FlexKomSID" SG_ 38 FullOFC_Actv_PHEV 2992;
BA_ "FlexKomIsMotorola" SG_ 38 FullOFC_Actv_PHEV 1;
BA_ "FlexKomComment" SG_ 38 FullOFC_Actv_PHEV "ECM_A1_PHEV_PKT";
BA_ "GenSigSNA" SG_ 38 ECM_IMMO_STAT_CANC_PHEV "3h";
BA_ "GenSigCycleTime" SG_ 38 ECM_IMMO_STAT_CANC_PHEV 10;
BA_ "FlexKomSigStartValue" SG_ 38 ECM_IMMO_STAT_CANC_PHEV "FFFFFF00201E00FFh";
BA_ "FlexKomSigStartPos" SG_ 38 ECM_IMMO_STAT_CANC_PHEV 7;
BA_ "FlexKomSigName" SG_ 38 ECM_IMMO_STAT_CANC_PHEV "ECM_A1_PHEV_PKT";
BA_ "FlexKomSigLaenge" SG_ 38 ECM_IMMO_STAT_CANC_PHEV 64;
BA_ "FlexKomSID" SG_ 38 ECM_IMMO_STAT_CANC_PHEV 2992;
BA_ "FlexKomIsMotorola" SG_ 38 ECM_IMMO_STAT_CANC_PHEV 1;
BA_ "FlexKomComment" SG_ 38 ECM_IMMO_STAT_CANC_PHEV "ECM_A1_PHEV_PKT";
BA_ "GenSigSNA" SG_ 38 ESS_ReqShiftPark_PHEV "0h";
BA_ "GenSigCycleTime" SG_ 38 ESS_ReqShiftPark_PHEV 10;
BA_ "FlexKomSigStartValue" SG_ 38 ESS_ReqShiftPark_PHEV "FFFFFF00201E00FFh";
BA_ "FlexKomSigStartPos" SG_ 38 ESS_ReqShiftPark_PHEV 7;
BA_ "FlexKomSigName" SG_ 38 ESS_ReqShiftPark_PHEV "ECM_A1_PHEV_PKT";
BA_ "FlexKomSigLaenge" SG_ 38 ESS_ReqShiftPark_PHEV 64;
BA_ "FlexKomSID" SG_ 38 ESS_ReqShiftPark_PHEV 2992;
BA_ "FlexKomIsMotorola" SG_ 38 ESS_ReqShiftPark_PHEV 1;
BA_ "FlexKomComment" SG_ 38 ESS_ReqShiftPark_PHEV "ECM_A1_PHEV_PKT";
BA_ "GenSigSNA" SG_ 38 MC_ECM_A1_PHEV "0h";
BA_ "GenSigCycleTime" SG_ 38 MC_ECM_A1_PHEV 10;
BA_ "FlexKomSigStartValue" SG_ 38 MC_ECM_A1_PHEV "FFFFFF00201E00FFh";
BA_ "FlexKomSigStartPos" SG_ 38 MC_ECM_A1_PHEV 7;
BA_ "FlexKomSigName" SG_ 38 MC_ECM_A1_PHEV "ECM_A1_PHEV_PKT";
BA_ "FlexKomSigLaenge" SG_ 38 MC_ECM_A1_PHEV 64;
BA_ "FlexKomSID" SG_ 38 MC_ECM_A1_PHEV 2992;
BA_ "FlexKomIsMotorola" SG_ 38 MC_ECM_A1_PHEV 1;
BA_ "FlexKomComment" SG_ 38 MC_ECM_A1_PHEV "ECM_A1_PHEV_PKT";
BA_ "GenSigStartValue" SG_ 38 CRC_ECM_A1_PHEV 255;
BA_ "GenSigSNA" SG_ 38 CRC_ECM_A1_PHEV "FFh";
BA_ "GenSigCycleTime" SG_ 38 CRC_ECM_A1_PHEV 10;
BA_ "FlexKomSigStartValue" SG_ 38 CRC_ECM_A1_PHEV "FFFFFF00201E00FFh";
BA_ "FlexKomSigStartPos" SG_ 38 CRC_ECM_A1_PHEV 7;
BA_ "FlexKomSigName" SG_ 38 CRC_ECM_A1_PHEV "ECM_A1_PHEV_PKT";
BA_ "FlexKomSigLaenge" SG_ 38 CRC_ECM_A1_PHEV 64;
BA_ "FlexKomSID" SG_ 38 CRC_ECM_A1_PHEV 2992;
BA_ "FlexKomIsMotorola" SG_ 38 CRC_ECM_A1_PHEV 1;
BA_ "FlexKomComment" SG_ 38 CRC_ECM_A1_PHEV "ECM_A1_PHEV_PKT";
BA_ "GenSigTimeout_IC" SG_ 39 EngTrqMax 105;
BA_ "GenSigStartValue" SG_ 39 EngTrqMax 8191;
BA_ "GenSigSNA" SG_ 39 EngTrqMax "1FFFh";
BA_ "GenSigCycleTime" SG_ 39 EngTrqMax 10;
BA_ "FlexKomSigStartValue" SG_ 39 EngTrqMax "9FFF1FFF1FFF00FFh";
BA_ "FlexKomSigStartPos" SG_ 39 EngTrqMax 7;
BA_ "FlexKomSigName" SG_ 39 EngTrqMax "ECM_ENG_TRQ_Pkt";
BA_ "FlexKomSigLaenge" SG_ 39 EngTrqMax 64;
BA_ "FlexKomSID" SG_ 39 EngTrqMax 1853;
BA_ "FlexKomIsMotorola" SG_ 39 EngTrqMax 1;
BA_ "FlexKomComment" SG_ 39 EngTrqMax "ECM_ENG_TRQ packet";
BA_ "GenSigTimeout_CBC" SG_ 39 ANL_LFT 105;
BA_ "GenSigSNA" SG_ 39 ANL_LFT "0h";
BA_ "GenSigCycleTime" SG_ 39 ANL_LFT 10;
BA_ "FlexKomSigStartValue" SG_ 39 ANL_LFT "9FFF1FFF1FFF00FFh";
BA_ "FlexKomSigStartPos" SG_ 39 ANL_LFT 7;
BA_ "FlexKomSigName" SG_ 39 ANL_LFT "ECM_ENG_TRQ_Pkt";
BA_ "FlexKomSigLaenge" SG_ 39 ANL_LFT 64;
BA_ "FlexKomSID" SG_ 39 ANL_LFT 1853;
BA_ "FlexKomIsMotorola" SG_ 39 ANL_LFT 1;
BA_ "FlexKomComment" SG_ 39 ANL_LFT "ECM_ENG_TRQ packet";
BA_ "GenSigTimeout_ORC" SG_ 39 Clutch_Disengg 35;
BA_ "GenSigSNA" SG_ 39 Clutch_Disengg "0h";
BA_ "GenSigCycleTime" SG_ 39 Clutch_Disengg 10;
BA_ "FlexKomSigStartValue" SG_ 39 Clutch_Disengg "9FFF1FFF1FFF00FFh";
BA_ "FlexKomSigStartPos" SG_ 39 Clutch_Disengg 7;
BA_ "FlexKomSigName" SG_ 39 Clutch_Disengg "ECM_ENG_TRQ_Pkt";
BA_ "FlexKomSigLaenge" SG_ 39 Clutch_Disengg 64;
BA_ "FlexKomSID" SG_ 39 Clutch_Disengg 1853;
BA_ "FlexKomIsMotorola" SG_ 39 Clutch_Disengg 1;
BA_ "FlexKomComment" SG_ 39 Clutch_Disengg "ECM_ENG_TRQ packet";
BA_ "GenSigTimeout_ORC" SG_ 39 ClutchInterLk 35;
BA_ "GenSigTimeout_DTCM" SG_ 39 ClutchInterLk 105;
BA_ "GenSigStartValue" SG_ 39 ClutchInterLk 1;
BA_ "GenSigSNA" SG_ 39 ClutchInterLk "1h";
BA_ "GenSigCycleTime" SG_ 39 ClutchInterLk 10;
BA_ "FlexKomSigStartValue" SG_ 39 ClutchInterLk "9FFF1FFF1FFF00FFh";
BA_ "FlexKomSigStartPos" SG_ 39 ClutchInterLk 7;
BA_ "FlexKomSigName" SG_ 39 ClutchInterLk "ECM_ENG_TRQ_Pkt";
BA_ "FlexKomSigLaenge" SG_ 39 ClutchInterLk 64;
BA_ "FlexKomSID" SG_ 39 ClutchInterLk 1853;
BA_ "FlexKomIsMotorola" SG_ 39 ClutchInterLk 1;
BA_ "FlexKomComment" SG_ 39 ClutchInterLk "ECM_ENG_TRQ packet";
BA_ "GenSigTimeout_IC" SG_ 39 EngTrqMin 105;
BA_ "GenSigStartValue" SG_ 39 EngTrqMin 8191;
BA_ "GenSigSNA" SG_ 39 EngTrqMin "1FFFh";
BA_ "GenSigCycleTime" SG_ 39 EngTrqMin 10;
BA_ "FlexKomSigStartValue" SG_ 39 EngTrqMin "9FFF1FFF1FFF00FFh";
BA_ "FlexKomSigStartPos" SG_ 39 EngTrqMin 7;
BA_ "FlexKomSigName" SG_ 39 EngTrqMin "ECM_ENG_TRQ_Pkt";
BA_ "FlexKomSigLaenge" SG_ 39 EngTrqMin 64;
BA_ "FlexKomSID" SG_ 39 EngTrqMin 1853;
BA_ "FlexKomIsMotorola" SG_ 39 EngTrqMin 1;
BA_ "FlexKomComment" SG_ 39 EngTrqMin "ECM_ENG_TRQ packet";
BA_ "RID" SG_ 39 MdsAct "2097";
BA_ "GenSigTimeout_IC" SG_ 39 MdsAct 105;
BA_ "GenSigSNA" SG_ 39 MdsAct "0h";
BA_ "GenSigCycleTime" SG_ 39 MdsAct 10;
BA_ "FlexKomSigStartValue" SG_ 39 MdsAct "9FFF1FFF1FFF00FFh";
BA_ "FlexKomSigStartPos" SG_ 39 MdsAct 7;
BA_ "FlexKomSigName" SG_ 39 MdsAct "ECM_ENG_TRQ_Pkt";
BA_ "FlexKomSigLaenge" SG_ 39 MdsAct 64;
BA_ "FlexKomSID" SG_ 39 MdsAct 1853;
BA_ "FlexKomIsMotorola" SG_ 39 MdsAct 1;
BA_ "FlexKomComment" SG_ 39 MdsAct "ECM_ENG_TRQ packet";
BA_ "RID" SG_ 39 MdsActforANC "2102";
BA_ "GenSigSNA" SG_ 39 MdsActforANC "0h";
BA_ "GenSigCycleTime" SG_ 39 MdsActforANC 10;
BA_ "FlexKomSigStartValue" SG_ 39 MdsActforANC "9FFF1FFF1FFF00FFh";
BA_ "FlexKomSigStartPos" SG_ 39 MdsActforANC 7;
BA_ "FlexKomSigName" SG_ 39 MdsActforANC "ECM_ENG_TRQ_Pkt";
BA_ "FlexKomSigLaenge" SG_ 39 MdsActforANC 64;
BA_ "FlexKomSID" SG_ 39 MdsActforANC 1853;
BA_ "FlexKomIsMotorola" SG_ 39 MdsActforANC 1;
BA_ "FlexKomComment" SG_ 39 MdsActforANC "ECM_ENG_TRQ packet";
BA_ "GenSigSNA" SG_ 39 ESS_ReqShiftPark "0h";
BA_ "GenSigCycleTime" SG_ 39 ESS_ReqShiftPark 10;
BA_ "FlexKomSigStartValue" SG_ 39 ESS_ReqShiftPark "9FFF1FFF1FFF00FFh";
BA_ "FlexKomSigStartPos" SG_ 39 ESS_ReqShiftPark 7;
BA_ "FlexKomSigName" SG_ 39 ESS_ReqShiftPark "ECM_ENG_TRQ_Pkt";
BA_ "FlexKomSigLaenge" SG_ 39 ESS_ReqShiftPark 64;
BA_ "FlexKomSID" SG_ 39 ESS_ReqShiftPark 1853;
BA_ "FlexKomIsMotorola" SG_ 39 ESS_ReqShiftPark 1;
BA_ "FlexKomComment" SG_ 39 ESS_ReqShiftPark "ECM_ENG_TRQ packet";
BA_ "GenSigSNA" SG_ 39 StartRelayBCMCmd "0h";
BA_ "GenSigCycleTime" SG_ 39 StartRelayBCMCmd 10;
BA_ "FlexKomSigStartValue" SG_ 39 StartRelayBCMCmd "9FFF1FFF1FFF00FFh";
BA_ "FlexKomSigStartPos" SG_ 39 StartRelayBCMCmd 7;
BA_ "FlexKomSigName" SG_ 39 StartRelayBCMCmd "ECM_ENG_TRQ_Pkt";
BA_ "FlexKomSigLaenge" SG_ 39 StartRelayBCMCmd 64;
BA_ "FlexKomSID" SG_ 39 StartRelayBCMCmd 1853;
BA_ "FlexKomIsMotorola" SG_ 39 StartRelayBCMCmd 1;
BA_ "FlexKomComment" SG_ 39 StartRelayBCMCmd "ECM_ENG_TRQ packet";
BA_ "GenSigSNA" SG_ 39 MC_ECM_ENG_TRQ "0h";
BA_ "GenSigCycleTime" SG_ 39 MC_ECM_ENG_TRQ 10;
BA_ "FlexKomSigStartValue" SG_ 39 MC_ECM_ENG_TRQ "9FFF1FFF1FFF00FFh";
BA_ "FlexKomSigStartPos" SG_ 39 MC_ECM_ENG_TRQ 7;
BA_ "FlexKomSigName" SG_ 39 MC_ECM_ENG_TRQ "ECM_ENG_TRQ_Pkt";
BA_ "FlexKomSigLaenge" SG_ 39 MC_ECM_ENG_TRQ 64;
BA_ "FlexKomSID" SG_ 39 MC_ECM_ENG_TRQ 1853;
BA_ "FlexKomIsMotorola" SG_ 39 MC_ECM_ENG_TRQ 1;
BA_ "FlexKomComment" SG_ 39 MC_ECM_ENG_TRQ "ECM_ENG_TRQ packet";
BA_ "GenSigStartValue" SG_ 39 CRC_ECM_ENG_TRQ 255;
BA_ "GenSigSNA" SG_ 39 CRC_ECM_ENG_TRQ "FFh";
BA_ "GenSigCycleTime" SG_ 39 CRC_ECM_ENG_TRQ 10;
BA_ "FlexKomSigStartValue" SG_ 39 CRC_ECM_ENG_TRQ "9FFF1FFF1FFF00FFh";
BA_ "FlexKomSigStartPos" SG_ 39 CRC_ECM_ENG_TRQ 7;
BA_ "FlexKomSigName" SG_ 39 CRC_ECM_ENG_TRQ "ECM_ENG_TRQ_Pkt";
BA_ "FlexKomSigLaenge" SG_ 39 CRC_ECM_ENG_TRQ 64;
BA_ "FlexKomSID" SG_ 39 CRC_ECM_ENG_TRQ 1853;
BA_ "FlexKomIsMotorola" SG_ 39 CRC_ECM_ENG_TRQ 1;
BA_ "FlexKomComment" SG_ 39 CRC_ECM_ENG_TRQ "ECM_ENG_TRQ packet";
BA_ "GenSigTimeout_IC" SG_ 40 SumTrqMax 105;
BA_ "GenSigStartValue" SG_ 40 SumTrqMax 8191;
BA_ "GenSigSNA" SG_ 40 SumTrqMax "1FFFh";
BA_ "GenSigCycleTime" SG_ 40 SumTrqMax 10;
BA_ "FlexKomSigStartValue" SG_ 40 SumTrqMax "1FFF1FFF1FFF00FFh";
BA_ "FlexKomSigStartPos" SG_ 40 SumTrqMax 7;
BA_ "FlexKomSigName" SG_ 40 SumTrqMax "HCP_A1_PKT";
BA_ "FlexKomSigLaenge" SG_ 40 SumTrqMax 64;
BA_ "FlexKomSID" SG_ 40 SumTrqMax 2990;
BA_ "FlexKomIsMotorola" SG_ 40 SumTrqMax 1;
BA_ "FlexKomComment" SG_ 40 SumTrqMax "HCP_A1_PKT";
BA_ "GenSigTimeout_IC" SG_ 40 SumTrqMin 105;
BA_ "GenSigStartValue" SG_ 40 SumTrqMin 8191;
BA_ "GenSigSNA" SG_ 40 SumTrqMin "1FFFh";
BA_ "GenSigCycleTime" SG_ 40 SumTrqMin 10;
BA_ "FlexKomSigStartValue" SG_ 40 SumTrqMin "1FFF1FFF1FFF00FFh";
BA_ "FlexKomSigStartPos" SG_ 40 SumTrqMin 7;
BA_ "FlexKomSigName" SG_ 40 SumTrqMin "HCP_A1_PKT";
BA_ "FlexKomSigLaenge" SG_ 40 SumTrqMin 64;
BA_ "FlexKomSID" SG_ 40 SumTrqMin 2990;
BA_ "FlexKomIsMotorola" SG_ 40 SumTrqMin 1;
BA_ "FlexKomComment" SG_ 40 SumTrqMin "HCP_A1_PKT";
BA_ "RID" SG_ 40 SumTrqStatic "2184";
BA_ "GenSigTimeout_TCM" SG_ 40 SumTrqStatic 105;
BA_ "GenSigTimeout_IC" SG_ 40 SumTrqStatic 105;
BA_ "GenSigTimeout_DTCM" SG_ 40 SumTrqStatic 105;
BA_ "GenSigTimeout_CBC" SG_ 40 SumTrqStatic 105;
BA_ "GenSigStartValue" SG_ 40 SumTrqStatic 8191;
BA_ "GenSigSNA" SG_ 40 SumTrqStatic "1FFFh";
BA_ "GenSigCycleTime" SG_ 40 SumTrqStatic 10;
BA_ "FlexKomSigStartValue" SG_ 40 SumTrqStatic "1FFF1FFF1FFF00FFh";
BA_ "FlexKomSigStartPos" SG_ 40 SumTrqStatic 7;
BA_ "FlexKomSigName" SG_ 40 SumTrqStatic "HCP_A1_PKT";
BA_ "FlexKomSigLaenge" SG_ 40 SumTrqStatic 64;
BA_ "FlexKomSID" SG_ 40 SumTrqStatic 2990;
BA_ "FlexKomIsMotorola" SG_ 40 SumTrqStatic 1;
BA_ "FlexKomComment" SG_ 40 SumTrqStatic "HCP_A1_PKT";
BA_ "GenSigSNA" SG_ 40 MC_HCP_A1 "0h";
BA_ "GenSigCycleTime" SG_ 40 MC_HCP_A1 10;
BA_ "FlexKomSigStartValue" SG_ 40 MC_HCP_A1 "1FFF1FFF1FFF00FFh";
BA_ "FlexKomSigStartPos" SG_ 40 MC_HCP_A1 7;
BA_ "FlexKomSigName" SG_ 40 MC_HCP_A1 "HCP_A1_PKT";
BA_ "FlexKomSigLaenge" SG_ 40 MC_HCP_A1 64;
BA_ "FlexKomSID" SG_ 40 MC_HCP_A1 2990;
BA_ "FlexKomIsMotorola" SG_ 40 MC_HCP_A1 1;
BA_ "FlexKomComment" SG_ 40 MC_HCP_A1 "HCP_A1_PKT";
BA_ "GenSigStartValue" SG_ 40 CRC_HCP_A1 255;
BA_ "GenSigSNA" SG_ 40 CRC_HCP_A1 "FFh";
BA_ "GenSigCycleTime" SG_ 40 CRC_HCP_A1 10;
BA_ "FlexKomSigStartValue" SG_ 40 CRC_HCP_A1 "1FFF1FFF1FFF00FFh";
BA_ "FlexKomSigStartPos" SG_ 40 CRC_HCP_A1 7;
BA_ "FlexKomSigName" SG_ 40 CRC_HCP_A1 "HCP_A1_PKT";
BA_ "FlexKomSigLaenge" SG_ 40 CRC_HCP_A1 64;
BA_ "FlexKomSID" SG_ 40 CRC_HCP_A1 2990;
BA_ "FlexKomIsMotorola" SG_ 40 CRC_HCP_A1 1;
BA_ "FlexKomComment" SG_ 40 CRC_HCP_A1 "HCP_A1_PKT";
BA_ "GenSigSNA" SG_ 41 CODE_CLR_HCP "0h";
BA_ "GenSigCycleTime" SG_ 41 CODE_CLR_HCP 10;
BA_ "FlexKomSigStartValue" SG_ 41 CODE_CLR_HCP "00000000000000FFh";
BA_ "FlexKomSigStartPos" SG_ 41 CODE_CLR_HCP 7;
BA_ "FlexKomSigName" SG_ 41 CODE_CLR_HCP "HCP_Torq_Status";
BA_ "FlexKomSigLaenge" SG_ 41 CODE_CLR_HCP 64;
BA_ "FlexKomSID" SG_ 41 CODE_CLR_HCP 2222;
BA_ "FlexKomIsMotorola" SG_ 41 CODE_CLR_HCP 1;
BA_ "FlexKomComment" SG_ 41 CODE_CLR_HCP ".";
BA_ "GenSigSNA" SG_ 41 REPRGD_PFC_CLR_HCP "0h";
BA_ "GenSigCycleTime" SG_ 41 REPRGD_PFC_CLR_HCP 10;
BA_ "FlexKomSigStartValue" SG_ 41 REPRGD_PFC_CLR_HCP "00000000000000FFh";
BA_ "FlexKomSigStartPos" SG_ 41 REPRGD_PFC_CLR_HCP 7;
BA_ "FlexKomSigName" SG_ 41 REPRGD_PFC_CLR_HCP "HCP_Torq_Status";
BA_ "FlexKomSigLaenge" SG_ 41 REPRGD_PFC_CLR_HCP 64;
BA_ "FlexKomSID" SG_ 41 REPRGD_PFC_CLR_HCP 2222;
BA_ "FlexKomIsMotorola" SG_ 41 REPRGD_PFC_CLR_HCP 1;
BA_ "FlexKomComment" SG_ 41 REPRGD_PFC_CLR_HCP ".";
BA_ "GenSigSNA" SG_ 41 PropulsionMode "7h";
BA_ "GenSigCycleTime" SG_ 41 PropulsionMode 10;
BA_ "FlexKomSigStartValue" SG_ 41 PropulsionMode "00000000000000FFh";
BA_ "FlexKomSigStartPos" SG_ 41 PropulsionMode 7;
BA_ "FlexKomSigName" SG_ 41 PropulsionMode "HCP_Torq_Status";
BA_ "FlexKomSigLaenge" SG_ 41 PropulsionMode 64;
BA_ "FlexKomSID" SG_ 41 PropulsionMode 2222;
BA_ "FlexKomIsMotorola" SG_ 41 PropulsionMode 1;
BA_ "FlexKomComment" SG_ 41 PropulsionMode ".";
BA_ "GenSigSNA" SG_ 41 MC_123h "0h";
BA_ "GenSigCycleTime" SG_ 41 MC_123h 10;
BA_ "FlexKomSigStartValue" SG_ 41 MC_123h "00000000000000FFh";
BA_ "FlexKomSigStartPos" SG_ 41 MC_123h 7;
BA_ "FlexKomSigName" SG_ 41 MC_123h "HCP_Torq_Status";
BA_ "FlexKomSigLaenge" SG_ 41 MC_123h 64;
BA_ "FlexKomSID" SG_ 41 MC_123h 2222;
BA_ "FlexKomIsMotorola" SG_ 41 MC_123h 1;
BA_ "FlexKomComment" SG_ 41 MC_123h ".";
BA_ "GenSigStartValue" SG_ 41 CRC_123h 255;
BA_ "GenSigSNA" SG_ 41 CRC_123h "FFh";
BA_ "GenSigCycleTime" SG_ 41 CRC_123h 10;
BA_ "FlexKomSigStartValue" SG_ 41 CRC_123h "00000000000000FFh";
BA_ "FlexKomSigStartPos" SG_ 41 CRC_123h 7;
BA_ "FlexKomSigName" SG_ 41 CRC_123h "HCP_Torq_Status";
BA_ "FlexKomSigLaenge" SG_ 41 CRC_123h 64;
BA_ "FlexKomSID" SG_ 41 CRC_123h 2222;
BA_ "FlexKomIsMotorola" SG_ 41 CRC_123h 1;
BA_ "FlexKomComment" SG_ 41 CRC_123h ".";
BA_ "GenSigSNA" SG_ 43 LatAcceleration "FFFh";
BA_ "GenSigCycleTime" SG_ 43 LatAcceleration 10;
BA_ "FlexKomSigStartValue" SG_ 43 LatAcceleration "000000000FFF00FFh";
BA_ "FlexKomSigStartPos" SG_ 43 LatAcceleration 7;
BA_ "FlexKomSigName" SG_ 43 LatAcceleration "ORC_YRS_PKT";
BA_ "FlexKomSigLaenge" SG_ 43 LatAcceleration 64;
BA_ "FlexKomSID" SG_ 43 LatAcceleration 1587;
BA_ "FlexKomIsMotorola" SG_ 43 LatAcceleration 1;
BA_ "FlexKomComment" SG_ 43 LatAcceleration "Accelerometer data packet";
BA_ "GenSigSNA" SG_ 43 AXSStat "0h";
BA_ "GenSigCycleTime" SG_ 43 AXSStat 10;
BA_ "FlexKomSigStartValue" SG_ 43 AXSStat "000000000FFF00FFh";
BA_ "FlexKomSigStartPos" SG_ 43 AXSStat 7;
BA_ "FlexKomSigName" SG_ 43 AXSStat "ORC_YRS_PKT";
BA_ "FlexKomSigLaenge" SG_ 43 AXSStat 64;
BA_ "FlexKomSID" SG_ 43 AXSStat 1587;
BA_ "FlexKomIsMotorola" SG_ 43 AXSStat 1;
BA_ "FlexKomComment" SG_ 43 AXSStat "Accelerometer data packet";
BA_ "GenSigSNA" SG_ 43 AYSStat "0h";
BA_ "GenSigCycleTime" SG_ 43 AYSStat 10;
BA_ "FlexKomSigStartValue" SG_ 43 AYSStat "000000000FFF00FFh";
BA_ "FlexKomSigStartPos" SG_ 43 AYSStat 7;
BA_ "FlexKomSigName" SG_ 43 AYSStat "ORC_YRS_PKT";
BA_ "FlexKomSigLaenge" SG_ 43 AYSStat 64;
BA_ "FlexKomSID" SG_ 43 AYSStat 1587;
BA_ "FlexKomIsMotorola" SG_ 43 AYSStat 1;
BA_ "FlexKomComment" SG_ 43 AYSStat "Accelerometer data packet";
BA_ "GenSigSNA" SG_ 43 LongAcceleration "FFFh";
BA_ "GenSigCycleTime" SG_ 43 LongAcceleration 10;
BA_ "FlexKomSigStartValue" SG_ 43 LongAcceleration "000000000FFF00FFh";
BA_ "FlexKomSigStartPos" SG_ 43 LongAcceleration 7;
BA_ "FlexKomSigName" SG_ 43 LongAcceleration "ORC_YRS_PKT";
BA_ "FlexKomSigLaenge" SG_ 43 LongAcceleration 64;
BA_ "FlexKomSID" SG_ 43 LongAcceleration 1587;
BA_ "FlexKomIsMotorola" SG_ 43 LongAcceleration 1;
BA_ "FlexKomComment" SG_ 43 LongAcceleration "Accelerometer data packet";
BA_ "GenSigSNA" SG_ 43 YRSStat "0h";
BA_ "GenSigCycleTime" SG_ 43 YRSStat 10;
BA_ "FlexKomSigStartValue" SG_ 43 YRSStat "000000000FFF00FFh";
BA_ "FlexKomSigStartPos" SG_ 43 YRSStat 7;
BA_ "FlexKomSigName" SG_ 43 YRSStat "ORC_YRS_PKT";
BA_ "FlexKomSigLaenge" SG_ 43 YRSStat 64;
BA_ "FlexKomSID" SG_ 43 YRSStat 1587;
BA_ "FlexKomIsMotorola" SG_ 43 YRSStat 1;
BA_ "FlexKomComment" SG_ 43 YRSStat "Accelerometer data packet";
BA_ "GenSigSNA" SG_ 43 InternalError "0h";
BA_ "GenSigCycleTime" SG_ 43 InternalError 10;
BA_ "FlexKomSigStartValue" SG_ 43 InternalError "000000000FFF00FFh";
BA_ "FlexKomSigStartPos" SG_ 43 InternalError 7;
BA_ "FlexKomSigName" SG_ 43 InternalError "ORC_YRS_PKT";
BA_ "FlexKomSigLaenge" SG_ 43 InternalError 64;
BA_ "FlexKomSID" SG_ 43 InternalError 1587;
BA_ "FlexKomIsMotorola" SG_ 43 InternalError 1;
BA_ "FlexKomComment" SG_ 43 InternalError "Accelerometer data packet";
BA_ "GenSigSNA" SG_ 43 VoltageError "0h";
BA_ "GenSigCycleTime" SG_ 43 VoltageError 10;
BA_ "FlexKomSigStartValue" SG_ 43 VoltageError "000000000FFF00FFh";
BA_ "FlexKomSigStartPos" SG_ 43 VoltageError 7;
BA_ "FlexKomSigName" SG_ 43 VoltageError "ORC_YRS_PKT";
BA_ "FlexKomSigLaenge" SG_ 43 VoltageError 64;
BA_ "FlexKomSID" SG_ 43 VoltageError 1587;
BA_ "FlexKomIsMotorola" SG_ 43 VoltageError 1;
BA_ "FlexKomComment" SG_ 43 VoltageError "Accelerometer data packet";
BA_ "GenSigStartValue" SG_ 43 YawRate 4095;
BA_ "GenSigSNA" SG_ 43 YawRate "FFFh";
BA_ "GenSigCycleTime" SG_ 43 YawRate 10;
BA_ "FlexKomSigStartValue" SG_ 43 YawRate "000000000FFF00FFh";
BA_ "FlexKomSigStartPos" SG_ 43 YawRate 7;
BA_ "FlexKomSigName" SG_ 43 YawRate "ORC_YRS_PKT";
BA_ "FlexKomSigLaenge" SG_ 43 YawRate 64;
BA_ "FlexKomSID" SG_ 43 YawRate 1587;
BA_ "FlexKomIsMotorola" SG_ 43 YawRate 1;
BA_ "FlexKomComment" SG_ 43 YawRate "Accelerometer data packet";
BA_ "GenSigSNA" SG_ 43 MC_ORC_YRS_DATA "0h";
BA_ "GenSigCycleTime" SG_ 43 MC_ORC_YRS_DATA 10;
BA_ "FlexKomSigStartValue" SG_ 43 MC_ORC_YRS_DATA "000000000FFF00FFh";
BA_ "FlexKomSigStartPos" SG_ 43 MC_ORC_YRS_DATA 7;
BA_ "FlexKomSigName" SG_ 43 MC_ORC_YRS_DATA "ORC_YRS_PKT";
BA_ "FlexKomSigLaenge" SG_ 43 MC_ORC_YRS_DATA 64;
BA_ "FlexKomSID" SG_ 43 MC_ORC_YRS_DATA 1587;
BA_ "FlexKomIsMotorola" SG_ 43 MC_ORC_YRS_DATA 1;
BA_ "FlexKomComment" SG_ 43 MC_ORC_YRS_DATA "Accelerometer data packet";
BA_ "GenSigStartValue" SG_ 43 CRC_ORC_YRS_DATA 255;
BA_ "GenSigSNA" SG_ 43 CRC_ORC_YRS_DATA "FFh";
BA_ "GenSigCycleTime" SG_ 43 CRC_ORC_YRS_DATA 10;
BA_ "FlexKomSigStartValue" SG_ 43 CRC_ORC_YRS_DATA "000000000FFF00FFh";
BA_ "FlexKomSigStartPos" SG_ 43 CRC_ORC_YRS_DATA 7;
BA_ "FlexKomSigName" SG_ 43 CRC_ORC_YRS_DATA "ORC_YRS_PKT";
BA_ "FlexKomSigLaenge" SG_ 43 CRC_ORC_YRS_DATA 64;
BA_ "FlexKomSID" SG_ 43 CRC_ORC_YRS_DATA 1587;
BA_ "FlexKomIsMotorola" SG_ 43 CRC_ORC_YRS_DATA 1;
BA_ "FlexKomComment" SG_ 43 CRC_ORC_YRS_DATA "Accelerometer data packet";
BA_ "GenSigSNA" SG_ 47 BrkPdlRawStat "0h";
BA_ "GenSigCycleTime" SG_ 47 BrkPdlRawStat 10;
BA_ "FlexKomSigStartValue" SG_ 47 BrkPdlRawStat "0000h";
BA_ "FlexKomSigStartPos" SG_ 47 BrkPdlRawStat 39;
BA_ "FlexKomSigName" SG_ 47 BrkPdlRawStat "BrkPdlRawStat";
BA_ "FlexKomSigLaenge" SG_ 47 BrkPdlRawStat 16;
BA_ "FlexKomSID" SG_ 47 BrkPdlRawStat 2437;
BA_ "FlexKomIsMotorola" SG_ 47 BrkPdlRawStat 1;
BA_ "FlexKomComment" SG_ 47 BrkPdlRawStat "Brake pedal state raw value";
BA_ "GenSigSNA" SG_ 47 RAW_OBD_VEHACCEL_X "0h";
BA_ "GenSigCycleTime" SG_ 47 RAW_OBD_VEHACCEL_X 10;
BA_ "FlexKomSigStartValue" SG_ 47 RAW_OBD_VEHACCEL_X "00h";
BA_ "FlexKomSigStartPos" SG_ 47 RAW_OBD_VEHACCEL_X 55;
BA_ "FlexKomSigName" SG_ 47 RAW_OBD_VEHACCEL_X "RAW_OBD_VEHACCEL_X";
BA_ "FlexKomSigLaenge" SG_ 47 RAW_OBD_VEHACCEL_X 8;
BA_ "FlexKomSID" SG_ 47 RAW_OBD_VEHACCEL_X 2596;
BA_ "FlexKomIsMotorola" SG_ 47 RAW_OBD_VEHACCEL_X 1;
BA_ "FlexKomComment" SG_ 47 RAW_OBD_VEHACCEL_X "Raw vehicle acceleration in the X direction";
BA_ "GenSigStartValue" SG_ 53 EngTrqTgt_SEM 8191;
BA_ "GenSigSNA" SG_ 53 EngTrqTgt_SEM "1FFFh";
BA_ "GenSigCycleTime" SG_ 53 EngTrqTgt_SEM 10;
BA_ "FlexKomSigStartValue" SG_ 53 EngTrqTgt_SEM "5FFF1FFF00FF0FFFh";
BA_ "FlexKomSigStartPos" SG_ 53 EngTrqTgt_SEM 7;
BA_ "FlexKomSigName" SG_ 53 EngTrqTgt_SEM "ECM_A3_PKT";
BA_ "FlexKomSigLaenge" SG_ 53 EngTrqTgt_SEM 64;
BA_ "FlexKomSID" SG_ 53 EngTrqTgt_SEM 1369;
BA_ "FlexKomIsMotorola" SG_ 53 EngTrqTgt_SEM 1;
BA_ "FlexKomComment" SG_ 53 EngTrqTgt_SEM "ECM_A3 message packet";
BA_ "GenSigSNA" SG_ 53 EngRdyForESS "0h";
BA_ "GenSigCycleTime" SG_ 53 EngRdyForESS 10;
BA_ "FlexKomSigStartValue" SG_ 53 EngRdyForESS "5FFF1FFF00FF0FFFh";
BA_ "FlexKomSigStartPos" SG_ 53 EngRdyForESS 7;
BA_ "FlexKomSigName" SG_ 53 EngRdyForESS "ECM_A3_PKT";
BA_ "FlexKomSigLaenge" SG_ 53 EngRdyForESS 64;
BA_ "FlexKomSID" SG_ 53 EngRdyForESS 1369;
BA_ "FlexKomIsMotorola" SG_ 53 EngRdyForESS 1;
BA_ "FlexKomComment" SG_ 53 EngRdyForESS "ECM_A3 message packet";
BA_ "GenSigStartValue" SG_ 53 EngTrqStatic_SEM 8191;
BA_ "GenSigSNA" SG_ 53 EngTrqStatic_SEM "1FFFh";
BA_ "GenSigCycleTime" SG_ 53 EngTrqStatic_SEM 10;
BA_ "FlexKomSigStartValue" SG_ 53 EngTrqStatic_SEM "5FFF1FFF00FF0FFFh";
BA_ "FlexKomSigStartPos" SG_ 53 EngTrqStatic_SEM 7;
BA_ "FlexKomSigName" SG_ 53 EngTrqStatic_SEM "ECM_A3_PKT";
BA_ "FlexKomSigLaenge" SG_ 53 EngTrqStatic_SEM 64;
BA_ "FlexKomSID" SG_ 53 EngTrqStatic_SEM 1369;
BA_ "FlexKomIsMotorola" SG_ 53 EngTrqStatic_SEM 1;
BA_ "FlexKomComment" SG_ 53 EngTrqStatic_SEM "ECM_A3 message packet";
BA_ "RID" SG_ 53 TRANS_CLU_SLIP_MODE "2105";
BA_ "GenSigTimeout_CBC" SG_ 53 TRANS_CLU_SLIP_MODE 105;
BA_ "GenSigSNA" SG_ 53 TRANS_CLU_SLIP_MODE "7h";
BA_ "GenSigCycleTime" SG_ 53 TRANS_CLU_SLIP_MODE 10;
BA_ "FlexKomSigStartValue" SG_ 53 TRANS_CLU_SLIP_MODE "5FFF1FFF00FF0FFFh";
BA_ "FlexKomSigStartPos" SG_ 53 TRANS_CLU_SLIP_MODE 7;
BA_ "FlexKomSigName" SG_ 53 TRANS_CLU_SLIP_MODE "ECM_A3_PKT";
BA_ "FlexKomSigLaenge" SG_ 53 TRANS_CLU_SLIP_MODE 64;
BA_ "FlexKomSID" SG_ 53 TRANS_CLU_SLIP_MODE 1369;
BA_ "FlexKomIsMotorola" SG_ 53 TRANS_CLU_SLIP_MODE 1;
BA_ "FlexKomComment" SG_ 53 TRANS_CLU_SLIP_MODE "ECM_A3 message packet";
BA_ "GenSigSNA" SG_ 53 ThrmlMngActv "0h";
BA_ "GenSigCycleTime" SG_ 53 ThrmlMngActv 10;
BA_ "FlexKomSigStartValue" SG_ 53 ThrmlMngActv "5FFF1FFF00FF0FFFh";
BA_ "FlexKomSigStartPos" SG_ 53 ThrmlMngActv 7;
BA_ "FlexKomSigName" SG_ 53 ThrmlMngActv "ECM_A3_PKT";
BA_ "FlexKomSigLaenge" SG_ 53 ThrmlMngActv 64;
BA_ "FlexKomSID" SG_ 53 ThrmlMngActv 1369;
BA_ "FlexKomIsMotorola" SG_ 53 ThrmlMngActv 1;
BA_ "FlexKomComment" SG_ 53 ThrmlMngActv "ECM_A3 message packet";
BA_ "GenSigStartValue" SG_ 53 EngMaxRPM 255;
BA_ "GenSigSNA" SG_ 53 EngMaxRPM "FFh";
BA_ "GenSigCycleTime" SG_ 53 EngMaxRPM 10;
BA_ "FlexKomSigStartValue" SG_ 53 EngMaxRPM "5FFF1FFF00FF0FFFh";
BA_ "FlexKomSigStartPos" SG_ 53 EngMaxRPM 7;
BA_ "FlexKomSigName" SG_ 53 EngMaxRPM "ECM_A3_PKT";
BA_ "FlexKomSigLaenge" SG_ 53 EngMaxRPM 64;
BA_ "FlexKomSID" SG_ 53 EngMaxRPM 1369;
BA_ "FlexKomIsMotorola" SG_ 53 EngMaxRPM 1;
BA_ "FlexKomComment" SG_ 53 EngMaxRPM "ECM_A3 message packet";
BA_ "RID" SG_ 53 ESS_ENG_ST "1653";
BA_ "GenSigTimeout_RF_HUB" SG_ 53 ESS_ENG_ST 105;
BA_ "GenSigTimeout_ORC" SG_ 53 ESS_ENG_ST 35;
BA_ "GenSigTimeout_CBC" SG_ 53 ESS_ENG_ST 105;
BA_ "GenSigStartValue" SG_ 53 ESS_ENG_ST 15;
BA_ "GenSigSNA" SG_ 53 ESS_ENG_ST "Fh";
BA_ "GenSigCycleTime" SG_ 53 ESS_ENG_ST 10;
BA_ "FlexKomSigStartValue" SG_ 53 ESS_ENG_ST "5FFF1FFF00FF0FFFh";
BA_ "FlexKomSigStartPos" SG_ 53 ESS_ENG_ST 7;
BA_ "FlexKomSigName" SG_ 53 ESS_ENG_ST "ECM_A3_PKT";
BA_ "FlexKomSigLaenge" SG_ 53 ESS_ENG_ST 64;
BA_ "FlexKomSID" SG_ 53 ESS_ENG_ST 1369;
BA_ "FlexKomIsMotorola" SG_ 53 ESS_ENG_ST 1;
BA_ "FlexKomComment" SG_ 53 ESS_ENG_ST "ECM_A3 message packet";
BA_ "GenSigSNA" SG_ 53 MC_ECM_A3 "0h";
BA_ "GenSigCycleTime" SG_ 53 MC_ECM_A3 10;
BA_ "FlexKomSigStartValue" SG_ 53 MC_ECM_A3 "5FFF1FFF00FF0FFFh";
BA_ "FlexKomSigStartPos" SG_ 53 MC_ECM_A3 7;
BA_ "FlexKomSigName" SG_ 53 MC_ECM_A3 "ECM_A3_PKT";
BA_ "FlexKomSigLaenge" SG_ 53 MC_ECM_A3 64;
BA_ "FlexKomSID" SG_ 53 MC_ECM_A3 1369;
BA_ "FlexKomIsMotorola" SG_ 53 MC_ECM_A3 1;
BA_ "FlexKomComment" SG_ 53 MC_ECM_A3 "ECM_A3 message packet";
BA_ "GenSigStartValue" SG_ 53 CRC_ECM_A3 255;
BA_ "GenSigSNA" SG_ 53 CRC_ECM_A3 "FFh";
BA_ "GenSigCycleTime" SG_ 53 CRC_ECM_A3 10;
BA_ "FlexKomSigStartValue" SG_ 53 CRC_ECM_A3 "5FFF1FFF00FF0FFFh";
BA_ "FlexKomSigStartPos" SG_ 53 CRC_ECM_A3 7;
BA_ "FlexKomSigName" SG_ 53 CRC_ECM_A3 "ECM_A3_PKT";
BA_ "FlexKomSigLaenge" SG_ 53 CRC_ECM_A3 64;
BA_ "FlexKomSID" SG_ 53 CRC_ECM_A3 1369;
BA_ "FlexKomIsMotorola" SG_ 53 CRC_ECM_A3 1;
BA_ "FlexKomComment" SG_ 53 CRC_ECM_A3 "ECM_A3 message packet";
BA_ "GenSigSNA" SG_ 53 EngStallSts "3h";
BA_ "GenSigCycleTime" SG_ 53 EngStallSts 10;
BA_ "FlexKomSigStartValue" SG_ 53 EngStallSts "5FFF1FFF00FF0FFFh";
BA_ "FlexKomSigStartPos" SG_ 53 EngStallSts 7;
BA_ "FlexKomSigName" SG_ 53 EngStallSts "ECM_A3_PKT";
BA_ "FlexKomSigLaenge" SG_ 53 EngStallSts 64;
BA_ "FlexKomSID" SG_ 53 EngStallSts 1369;
BA_ "FlexKomIsMotorola" SG_ 53 EngStallSts 1;
BA_ "FlexKomComment" SG_ 53 EngStallSts "ECM_A3 message packet";
BA_ "GenSigStartValue" SG_ 54 SumTrqTgt_SEM 8191;
BA_ "GenSigSNA" SG_ 54 SumTrqTgt_SEM "1FFFh";
BA_ "GenSigCycleTime" SG_ 54 SumTrqTgt_SEM 10;
BA_ "FlexKomSigStartValue" SG_ 54 SumTrqTgt_SEM "1FFF1FFF1FFF00FFh";
BA_ "FlexKomSigStartPos" SG_ 54 SumTrqTgt_SEM 7;
BA_ "FlexKomSigName" SG_ 54 SumTrqTgt_SEM "HCP_A2_PKT";
BA_ "FlexKomSigLaenge" SG_ 54 SumTrqTgt_SEM 64;
BA_ "FlexKomSID" SG_ 54 SumTrqTgt_SEM 2994;
BA_ "FlexKomIsMotorola" SG_ 54 SumTrqTgt_SEM 1;
BA_ "FlexKomComment" SG_ 54 SumTrqTgt_SEM "HCP_A2_PKT";
BA_ "GenSigStartValue" SG_ 54 SumTrqStatic_SEM 8191;
BA_ "GenSigSNA" SG_ 54 SumTrqStatic_SEM "1FFFh";
BA_ "GenSigCycleTime" SG_ 54 SumTrqStatic_SEM 10;
BA_ "FlexKomSigStartValue" SG_ 54 SumTrqStatic_SEM "1FFF1FFF1FFF00FFh";
BA_ "FlexKomSigStartPos" SG_ 54 SumTrqStatic_SEM 7;
BA_ "FlexKomSigName" SG_ 54 SumTrqStatic_SEM "HCP_A2_PKT";
BA_ "FlexKomSigLaenge" SG_ 54 SumTrqStatic_SEM 64;
BA_ "FlexKomSID" SG_ 54 SumTrqStatic_SEM 2994;
BA_ "FlexKomIsMotorola" SG_ 54 SumTrqStatic_SEM 1;
BA_ "FlexKomComment" SG_ 54 SumTrqStatic_SEM "HCP_A2_PKT";
BA_ "GenSigTimeout_DTCM" SG_ 54 ExpSumTrq 105;
BA_ "GenSigStartValue" SG_ 54 ExpSumTrq 8191;
BA_ "GenSigSNA" SG_ 54 ExpSumTrq "1FFFh";
BA_ "GenSigCycleTime" SG_ 54 ExpSumTrq 10;
BA_ "FlexKomSigStartValue" SG_ 54 ExpSumTrq "1FFF1FFF1FFF00FFh";
BA_ "FlexKomSigStartPos" SG_ 54 ExpSumTrq 7;
BA_ "FlexKomSigName" SG_ 54 ExpSumTrq "HCP_A2_PKT";
BA_ "FlexKomSigLaenge" SG_ 54 ExpSumTrq 64;
BA_ "FlexKomSID" SG_ 54 ExpSumTrq 2994;
BA_ "FlexKomIsMotorola" SG_ 54 ExpSumTrq 1;
BA_ "FlexKomComment" SG_ 54 ExpSumTrq "HCP_A2_PKT";
BA_ "GenSigSNA" SG_ 54 MC_HCP_A2 "0h";
BA_ "GenSigCycleTime" SG_ 54 MC_HCP_A2 10;
BA_ "FlexKomSigStartValue" SG_ 54 MC_HCP_A2 "1FFF1FFF1FFF00FFh";
BA_ "FlexKomSigStartPos" SG_ 54 MC_HCP_A2 7;
BA_ "FlexKomSigName" SG_ 54 MC_HCP_A2 "HCP_A2_PKT";
BA_ "FlexKomSigLaenge" SG_ 54 MC_HCP_A2 64;
BA_ "FlexKomSID" SG_ 54 MC_HCP_A2 2994;
BA_ "FlexKomIsMotorola" SG_ 54 MC_HCP_A2 1;
BA_ "FlexKomComment" SG_ 54 MC_HCP_A2 "HCP_A2_PKT";
BA_ "GenSigStartValue" SG_ 54 CRC_HCP_A2 255;
BA_ "GenSigSNA" SG_ 54 CRC_HCP_A2 "FFh";
BA_ "GenSigCycleTime" SG_ 54 CRC_HCP_A2 10;
BA_ "FlexKomSigStartValue" SG_ 54 CRC_HCP_A2 "1FFF1FFF1FFF00FFh";
BA_ "FlexKomSigStartPos" SG_ 54 CRC_HCP_A2 7;
BA_ "FlexKomSigName" SG_ 54 CRC_HCP_A2 "HCP_A2_PKT";
BA_ "FlexKomSigLaenge" SG_ 54 CRC_HCP_A2 64;
BA_ "FlexKomSID" SG_ 54 CRC_HCP_A2 2994;
BA_ "FlexKomIsMotorola" SG_ 54 CRC_HCP_A2 1;
BA_ "FlexKomComment" SG_ 54 CRC_HCP_A2 "HCP_A2_PKT";
BA_ "GenSigStartValue" SG_ 55 EngTrqRq 8191;
BA_ "GenSigSNA" SG_ 55 EngTrqRq "1FFFh";
BA_ "GenSigCycleTime" SG_ 55 EngTrqRq 10;
BA_ "FlexKomSigStartValue" SG_ 55 EngTrqRq "1FFF1FFF1FFF00FFh";
BA_ "FlexKomSigStartPos" SG_ 55 EngTrqRq 7;
BA_ "FlexKomSigName" SG_ 55 EngTrqRq "TCM_EngTrq2_Pkt";
BA_ "FlexKomSigLaenge" SG_ 55 EngTrqRq 64;
BA_ "FlexKomSID" SG_ 55 EngTrqRq 1379;
BA_ "FlexKomIsMotorola" SG_ 55 EngTrqRq 1;
BA_ "FlexKomComment" SG_ 55 EngTrqRq "Engine Torque Pkt";
BA_ "GenSigSNA" SG_ 55 TrqCtrlModeRq "7h";
BA_ "GenSigCycleTime" SG_ 55 TrqCtrlModeRq 10;
BA_ "FlexKomSigStartValue" SG_ 55 TrqCtrlModeRq "1FFF1FFF1FFF00FFh";
BA_ "FlexKomSigStartPos" SG_ 55 TrqCtrlModeRq 7;
BA_ "FlexKomSigName" SG_ 55 TrqCtrlModeRq "TCM_EngTrq2_Pkt";
BA_ "FlexKomSigLaenge" SG_ 55 TrqCtrlModeRq 64;
BA_ "FlexKomSID" SG_ 55 TrqCtrlModeRq 1379;
BA_ "FlexKomIsMotorola" SG_ 55 TrqCtrlModeRq 1;
BA_ "FlexKomComment" SG_ 55 TrqCtrlModeRq "Engine Torque Pkt";
BA_ "GenSigStartValue" SG_ 55 MaxTrqDes 8191;
BA_ "GenSigSNA" SG_ 55 MaxTrqDes "1FFFh";
BA_ "GenSigCycleTime" SG_ 55 MaxTrqDes 10;
BA_ "FlexKomSigStartValue" SG_ 55 MaxTrqDes "1FFF1FFF1FFF00FFh";
BA_ "FlexKomSigStartPos" SG_ 55 MaxTrqDes 7;
BA_ "FlexKomSigName" SG_ 55 MaxTrqDes "TCM_EngTrq2_Pkt";
BA_ "FlexKomSigLaenge" SG_ 55 MaxTrqDes 64;
BA_ "FlexKomSID" SG_ 55 MaxTrqDes 1379;
BA_ "FlexKomIsMotorola" SG_ 55 MaxTrqDes 1;
BA_ "FlexKomComment" SG_ 55 MaxTrqDes "Engine Torque Pkt";
BA_ "GenSigSNA" SG_ 55 MC_TCM_EngTrq2 "0h";
BA_ "GenSigCycleTime" SG_ 55 MC_TCM_EngTrq2 10;
BA_ "FlexKomSigStartValue" SG_ 55 MC_TCM_EngTrq2 "1FFF1FFF1FFF00FFh";
BA_ "FlexKomSigStartPos" SG_ 55 MC_TCM_EngTrq2 7;
BA_ "FlexKomSigName" SG_ 55 MC_TCM_EngTrq2 "TCM_EngTrq2_Pkt";
BA_ "FlexKomSigLaenge" SG_ 55 MC_TCM_EngTrq2 64;
BA_ "FlexKomSID" SG_ 55 MC_TCM_EngTrq2 1379;
BA_ "FlexKomIsMotorola" SG_ 55 MC_TCM_EngTrq2 1;
BA_ "FlexKomComment" SG_ 55 MC_TCM_EngTrq2 "Engine Torque Pkt";
BA_ "GenSigStartValue" SG_ 55 CRC_TCM_EngTrq2 255;
BA_ "GenSigSNA" SG_ 55 CRC_TCM_EngTrq2 "FFh";
BA_ "GenSigCycleTime" SG_ 55 CRC_TCM_EngTrq2 10;
BA_ "FlexKomSigStartValue" SG_ 55 CRC_TCM_EngTrq2 "1FFF1FFF1FFF00FFh";
BA_ "FlexKomSigStartPos" SG_ 55 CRC_TCM_EngTrq2 7;
BA_ "FlexKomSigName" SG_ 55 CRC_TCM_EngTrq2 "TCM_EngTrq2_Pkt";
BA_ "FlexKomSigLaenge" SG_ 55 CRC_TCM_EngTrq2 64;
BA_ "FlexKomSID" SG_ 55 CRC_TCM_EngTrq2 1379;
BA_ "FlexKomIsMotorola" SG_ 55 CRC_TCM_EngTrq2 1;
BA_ "FlexKomComment" SG_ 55 CRC_TCM_EngTrq2 "Engine Torque Pkt";
BA_ "GenSigTimeout_TCM" SG_ 56 SumTrqSel_D_TTC 210;
BA_ "GenSigTimeout_DTCM" SG_ 56 SumTrqSel_D_TTC 210;
BA_ "GenSigStartValue" SG_ 56 SumTrqSel_D_TTC 8191;
BA_ "GenSigSNA" SG_ 56 SumTrqSel_D_TTC "1FFFh";
BA_ "GenSigCycleTime" SG_ 56 SumTrqSel_D_TTC 10;
BA_ "FlexKomSigStartValue" SG_ 56 SumTrqSel_D_TTC "1FFF1FFFFFFE00FFh";
BA_ "FlexKomSigStartPos" SG_ 56 SumTrqSel_D_TTC 7;
BA_ "FlexKomSigName" SG_ 56 SumTrqSel_D_TTC "HCP_A3_PKT";
BA_ "FlexKomSigLaenge" SG_ 56 SumTrqSel_D_TTC 64;
BA_ "FlexKomSID" SG_ 56 SumTrqSel_D_TTC 2995;
BA_ "FlexKomIsMotorola" SG_ 56 SumTrqSel_D_TTC 1;
BA_ "FlexKomComment" SG_ 56 SumTrqSel_D_TTC "HCP_A3_PKT";
BA_ "GenSigTimeout_DTCM" SG_ 56 SumTrq_DrvReqMod 210;
BA_ "GenSigStartValue" SG_ 56 SumTrq_DrvReqMod 8191;
BA_ "GenSigSNA" SG_ 56 SumTrq_DrvReqMod "1FFFh";
BA_ "GenSigCycleTime" SG_ 56 SumTrq_DrvReqMod 10;
BA_ "FlexKomSigStartValue" SG_ 56 SumTrq_DrvReqMod "1FFF1FFFFFFE00FFh";
BA_ "FlexKomSigStartPos" SG_ 56 SumTrq_DrvReqMod 7;
BA_ "FlexKomSigName" SG_ 56 SumTrq_DrvReqMod "HCP_A3_PKT";
BA_ "FlexKomSigLaenge" SG_ 56 SumTrq_DrvReqMod 64;
BA_ "FlexKomSID" SG_ 56 SumTrq_DrvReqMod 2995;
BA_ "FlexKomIsMotorola" SG_ 56 SumTrq_DrvReqMod 1;
BA_ "FlexKomComment" SG_ 56 SumTrq_DrvReqMod "HCP_A3_PKT";
BA_ "GenSigTimeout_TCM" SG_ 56 MotorB_Speed 105;
BA_ "GenSigTimeout_ORC" SG_ 56 MotorB_Speed 35;
BA_ "GenSigTimeout_IC" SG_ 56 MotorB_Speed 105;
BA_ "GenSigTimeout_ESM" SG_ 56 MotorB_Speed 105;
BA_ "GenSigTimeout_EHPS" SG_ 56 MotorB_Speed 105;
BA_ "GenSigTimeout_DTCM" SG_ 56 MotorB_Speed 105;
BA_ "GenSigTimeout_CBC" SG_ 56 MotorB_Speed 105;
BA_ "GenSigStartValue" SG_ 56 MotorB_Speed 65534;
BA_ "GenSigSNA" SG_ 56 MotorB_Speed "FFFFh";
BA_ "GenSigCycleTime" SG_ 56 MotorB_Speed 10;
BA_ "FlexKomSigStartValue" SG_ 56 MotorB_Speed "1FFF1FFFFFFE00FFh";
BA_ "FlexKomSigStartPos" SG_ 56 MotorB_Speed 7;
BA_ "FlexKomSigName" SG_ 56 MotorB_Speed "HCP_A3_PKT";
BA_ "FlexKomSigLaenge" SG_ 56 MotorB_Speed 64;
BA_ "FlexKomSID" SG_ 56 MotorB_Speed 2995;
BA_ "FlexKomIsMotorola" SG_ 56 MotorB_Speed 1;
BA_ "FlexKomComment" SG_ 56 MotorB_Speed "HCP_A3_PKT";
BA_ "GenSigSNA" SG_ 56 MC_HCP_A3 "0h";
BA_ "GenSigCycleTime" SG_ 56 MC_HCP_A3 10;
BA_ "FlexKomSigStartValue" SG_ 56 MC_HCP_A3 "1FFF1FFFFFFE00FFh";
BA_ "FlexKomSigStartPos" SG_ 56 MC_HCP_A3 7;
BA_ "FlexKomSigName" SG_ 56 MC_HCP_A3 "HCP_A3_PKT";
BA_ "FlexKomSigLaenge" SG_ 56 MC_HCP_A3 64;
BA_ "FlexKomSID" SG_ 56 MC_HCP_A3 2995;
BA_ "FlexKomIsMotorola" SG_ 56 MC_HCP_A3 1;
BA_ "FlexKomComment" SG_ 56 MC_HCP_A3 "HCP_A3_PKT";
BA_ "GenSigStartValue" SG_ 56 CRC_HCP_A3 255;
BA_ "GenSigSNA" SG_ 56 CRC_HCP_A3 "FFh";
BA_ "GenSigCycleTime" SG_ 56 CRC_HCP_A3 10;
BA_ "FlexKomSigStartValue" SG_ 56 CRC_HCP_A3 "1FFF1FFFFFFE00FFh";
BA_ "FlexKomSigStartPos" SG_ 56 CRC_HCP_A3 7;
BA_ "FlexKomSigName" SG_ 56 CRC_HCP_A3 "HCP_A3_PKT";
BA_ "FlexKomSigLaenge" SG_ 56 CRC_HCP_A3 64;
BA_ "FlexKomSID" SG_ 56 CRC_HCP_A3 2995;
BA_ "FlexKomIsMotorola" SG_ 56 CRC_HCP_A3 1;
BA_ "FlexKomComment" SG_ 56 CRC_HCP_A3 "HCP_A3_PKT";
BA_ "GenSigTimeout_TBM" SG_ 113 EngTrq_Rq_ESC 210;
BA_ "GenSigTimeout_ETM" SG_ 113 EngTrq_Rq_ESC 210;
BA_ "GenSigTimeout_DTCM" SG_ 113 EngTrq_Rq_ESC 210;
BA_ "GenSigSNA" SG_ 113 EngTrq_Rq_ESC "1FFFh";
BA_ "GenSigCycleTime" SG_ 113 EngTrq_Rq_ESC 20;
BA_ "FlexKomSigStartValue" SG_ 113 EngTrq_Rq_ESC "00000000FF0000FFh";
BA_ "FlexKomSigStartPos" SG_ 113 EngTrq_Rq_ESC 7;
BA_ "FlexKomSigName" SG_ 113 EngTrq_Rq_ESC "Eng_Trq_Rq";
BA_ "FlexKomSigLaenge" SG_ 113 EngTrq_Rq_ESC 64;
BA_ "FlexKomSID" SG_ 113 EngTrq_Rq_ESC 1;
BA_ "FlexKomIsMotorola" SG_ 113 EngTrq_Rq_ESC 1;
BA_ "FlexKomComment" SG_ 113 EngTrq_Rq_ESC "Engine torque request from ESC";
BA_ "GenSigTimeout_ORC" SG_ 113 DAS_Enbl_Rq 70;
BA_ "GenSigSNA" SG_ 113 DAS_Enbl_Rq "0h";
BA_ "GenSigCycleTime" SG_ 113 DAS_Enbl_Rq 20;
BA_ "FlexKomSigStartValue" SG_ 113 DAS_Enbl_Rq "00000000FF0000FFh";
BA_ "FlexKomSigStartPos" SG_ 113 DAS_Enbl_Rq 7;
BA_ "FlexKomSigName" SG_ 113 DAS_Enbl_Rq "Eng_Trq_Rq";
BA_ "FlexKomSigLaenge" SG_ 113 DAS_Enbl_Rq 64;
BA_ "FlexKomSID" SG_ 113 DAS_Enbl_Rq 1;
BA_ "FlexKomIsMotorola" SG_ 113 DAS_Enbl_Rq 1;
BA_ "FlexKomComment" SG_ 113 DAS_Enbl_Rq "Engine torque request from ESC";
BA_ "GenSigSNA" SG_ 113 EngTrqMax_Rq_ESC "0h";
BA_ "GenSigCycleTime" SG_ 113 EngTrqMax_Rq_ESC 20;
BA_ "FlexKomSigStartValue" SG_ 113 EngTrqMax_Rq_ESC "00000000FF0000FFh";
BA_ "FlexKomSigStartPos" SG_ 113 EngTrqMax_Rq_ESC 7;
BA_ "FlexKomSigName" SG_ 113 EngTrqMax_Rq_ESC "Eng_Trq_Rq";
BA_ "FlexKomSigLaenge" SG_ 113 EngTrqMax_Rq_ESC 64;
BA_ "FlexKomSID" SG_ 113 EngTrqMax_Rq_ESC 1;
BA_ "FlexKomIsMotorola" SG_ 113 EngTrqMax_Rq_ESC 1;
BA_ "FlexKomComment" SG_ 113 EngTrqMax_Rq_ESC "Engine torque request from ESC";
BA_ "GenSigTimeout_DTCM" SG_ 113 EngTrqMin_Rq_ESC 210;
BA_ "GenSigSNA" SG_ 113 EngTrqMin_Rq_ESC "0h";
BA_ "GenSigCycleTime" SG_ 113 EngTrqMin_Rq_ESC 20;
BA_ "FlexKomSigStartValue" SG_ 113 EngTrqMin_Rq_ESC "00000000FF0000FFh";
BA_ "FlexKomSigStartPos" SG_ 113 EngTrqMin_Rq_ESC 7;
BA_ "FlexKomSigName" SG_ 113 EngTrqMin_Rq_ESC "Eng_Trq_Rq";
BA_ "FlexKomSigLaenge" SG_ 113 EngTrqMin_Rq_ESC 64;
BA_ "FlexKomSID" SG_ 113 EngTrqMin_Rq_ESC 1;
BA_ "FlexKomIsMotorola" SG_ 113 EngTrqMin_Rq_ESC 1;
BA_ "FlexKomComment" SG_ 113 EngTrqMin_Rq_ESC "Engine torque request from ESC";
BA_ "GenSigTimeout_ORC" SG_ 113 EngTrq_Rq_As 70;
BA_ "GenSigSNA" SG_ 113 EngTrq_Rq_As "1FFFh";
BA_ "GenSigCycleTime" SG_ 113 EngTrq_Rq_As 20;
BA_ "FlexKomSigStartValue" SG_ 113 EngTrq_Rq_As "00000000FF0000FFh";
BA_ "FlexKomSigStartPos" SG_ 113 EngTrq_Rq_As 7;
BA_ "FlexKomSigName" SG_ 113 EngTrq_Rq_As "Eng_Trq_Rq";
BA_ "FlexKomSigLaenge" SG_ 113 EngTrq_Rq_As 64;
BA_ "FlexKomSID" SG_ 113 EngTrq_Rq_As 1;
BA_ "FlexKomIsMotorola" SG_ 113 EngTrq_Rq_As 1;
BA_ "FlexKomComment" SG_ 113 EngTrq_Rq_As "Engine torque request from ESC";
BA_ "RID" SG_ 113 ASRActive "5029";
BA_ "GenSigSNA" SG_ 113 ASRActive "0h";
BA_ "GenSigCycleTime" SG_ 113 ASRActive 20;
BA_ "FlexKomSigStartValue" SG_ 113 ASRActive "00000000FF0000FFh";
BA_ "FlexKomSigStartPos" SG_ 113 ASRActive 7;
BA_ "FlexKomSigName" SG_ 113 ASRActive "Eng_Trq_Rq";
BA_ "FlexKomSigLaenge" SG_ 113 ASRActive 64;
BA_ "FlexKomSID" SG_ 113 ASRActive 1;
BA_ "FlexKomIsMotorola" SG_ 113 ASRActive 1;
BA_ "FlexKomComment" SG_ 113 ASRActive "Engine torque request from ESC";
BA_ "GenSigSNA" SG_ 113 EngTrqMax_Rq_AS "0h";
BA_ "GenSigCycleTime" SG_ 113 EngTrqMax_Rq_AS 20;
BA_ "FlexKomSigStartValue" SG_ 113 EngTrqMax_Rq_AS "00000000FF0000FFh";
BA_ "FlexKomSigStartPos" SG_ 113 EngTrqMax_Rq_AS 7;
BA_ "FlexKomSigName" SG_ 113 EngTrqMax_Rq_AS "Eng_Trq_Rq";
BA_ "FlexKomSigLaenge" SG_ 113 EngTrqMax_Rq_AS 64;
BA_ "FlexKomSID" SG_ 113 EngTrqMax_Rq_AS 1;
BA_ "FlexKomIsMotorola" SG_ 113 EngTrqMax_Rq_AS 1;
BA_ "FlexKomComment" SG_ 113 EngTrqMax_Rq_AS "Engine torque request from ESC";
BA_ "GenSigTimeout_ORC" SG_ 113 BrkBstrVac 70;
BA_ "GenSigStartValue" SG_ 113 BrkBstrVac 255;
BA_ "GenSigSNA" SG_ 113 BrkBstrVac "FFh";
BA_ "GenSigCycleTime" SG_ 113 BrkBstrVac 20;
BA_ "FlexKomSigStartValue" SG_ 113 BrkBstrVac "00000000FF0000FFh";
BA_ "FlexKomSigStartPos" SG_ 113 BrkBstrVac 7;
BA_ "FlexKomSigName" SG_ 113 BrkBstrVac "Eng_Trq_Rq";
BA_ "FlexKomSigLaenge" SG_ 113 BrkBstrVac 64;
BA_ "FlexKomSID" SG_ 113 BrkBstrVac 1;
BA_ "FlexKomIsMotorola" SG_ 113 BrkBstrVac 1;
BA_ "FlexKomComment" SG_ 113 BrkBstrVac "Engine torque request from ESC";
BA_ "GenSigSNA" SG_ 113 PrefillActive "0h";
BA_ "GenSigCycleTime" SG_ 113 PrefillActive 20;
BA_ "FlexKomSigStartValue" SG_ 113 PrefillActive "00000000FF0000FFh";
BA_ "FlexKomSigStartPos" SG_ 113 PrefillActive 7;
BA_ "FlexKomSigName" SG_ 113 PrefillActive "Eng_Trq_Rq";
BA_ "FlexKomSigLaenge" SG_ 113 PrefillActive 64;
BA_ "FlexKomSID" SG_ 113 PrefillActive 1;
BA_ "FlexKomIsMotorola" SG_ 113 PrefillActive 1;
BA_ "FlexKomComment" SG_ 113 PrefillActive "Engine torque request from ESC";
BA_ "GenSigSNA" SG_ 113 DsblFuelShutOff "0h";
BA_ "GenSigCycleTime" SG_ 113 DsblFuelShutOff 20;
BA_ "FlexKomSigStartValue" SG_ 113 DsblFuelShutOff "00000000FF0000FFh";
BA_ "FlexKomSigStartPos" SG_ 113 DsblFuelShutOff 7;
BA_ "FlexKomSigName" SG_ 113 DsblFuelShutOff "Eng_Trq_Rq";
BA_ "FlexKomSigLaenge" SG_ 113 DsblFuelShutOff 64;
BA_ "FlexKomSID" SG_ 113 DsblFuelShutOff 1;
BA_ "FlexKomIsMotorola" SG_ 113 DsblFuelShutOff 1;
BA_ "FlexKomComment" SG_ 113 DsblFuelShutOff "Engine torque request from ESC";
BA_ "GenSigTimeout_ORC" SG_ 113 DAS_RqActv 70;
BA_ "GenSigSNA" SG_ 113 DAS_RqActv "7h";
BA_ "GenSigCycleTime" SG_ 113 DAS_RqActv 20;
BA_ "FlexKomSigStartValue" SG_ 113 DAS_RqActv "00000000FF0000FFh";
BA_ "FlexKomSigStartPos" SG_ 113 DAS_RqActv 7;
BA_ "FlexKomSigName" SG_ 113 DAS_RqActv "Eng_Trq_Rq";
BA_ "FlexKomSigLaenge" SG_ 113 DAS_RqActv 64;
BA_ "FlexKomSID" SG_ 113 DAS_RqActv 1;
BA_ "FlexKomIsMotorola" SG_ 113 DAS_RqActv 1;
BA_ "FlexKomComment" SG_ 113 DAS_RqActv "Engine torque request from ESC";
BA_ "GenSigTimeout_ORC" SG_ 113 Brk_Jrk_Rsp 70;
BA_ "GenSigSNA" SG_ 113 Brk_Jrk_Rsp "0h";
BA_ "GenSigCycleTime" SG_ 113 Brk_Jrk_Rsp 20;
BA_ "FlexKomSigStartValue" SG_ 113 Brk_Jrk_Rsp "00000000FF0000FFh";
BA_ "FlexKomSigStartPos" SG_ 113 Brk_Jrk_Rsp 7;
BA_ "FlexKomSigName" SG_ 113 Brk_Jrk_Rsp "Eng_Trq_Rq";
BA_ "FlexKomSigLaenge" SG_ 113 Brk_Jrk_Rsp 64;
BA_ "FlexKomSID" SG_ 113 Brk_Jrk_Rsp 1;
BA_ "FlexKomIsMotorola" SG_ 113 Brk_Jrk_Rsp 1;
BA_ "FlexKomComment" SG_ 113 Brk_Jrk_Rsp "Engine torque request from ESC";
BA_ "GenSigSNA" SG_ 113 MC_ENG_RQ_ESC "0h";
BA_ "GenSigCycleTime" SG_ 113 MC_ENG_RQ_ESC 20;
BA_ "FlexKomSigStartValue" SG_ 113 MC_ENG_RQ_ESC "00000000FF0000FFh";
BA_ "FlexKomSigStartPos" SG_ 113 MC_ENG_RQ_ESC 7;
BA_ "FlexKomSigName" SG_ 113 MC_ENG_RQ_ESC "Eng_Trq_Rq";
BA_ "FlexKomSigLaenge" SG_ 113 MC_ENG_RQ_ESC 64;
BA_ "FlexKomSID" SG_ 113 MC_ENG_RQ_ESC 1;
BA_ "FlexKomIsMotorola" SG_ 113 MC_ENG_RQ_ESC 1;
BA_ "FlexKomComment" SG_ 113 MC_ENG_RQ_ESC "Engine torque request from ESC";
BA_ "GenSigStartValue" SG_ 113 CRC_ENG_RQ_ESC 255;
BA_ "GenSigSNA" SG_ 113 CRC_ENG_RQ_ESC "FFh";
BA_ "GenSigCycleTime" SG_ 113 CRC_ENG_RQ_ESC 20;
BA_ "FlexKomSigStartValue" SG_ 113 CRC_ENG_RQ_ESC "00000000FF0000FFh";
BA_ "FlexKomSigStartPos" SG_ 113 CRC_ENG_RQ_ESC 7;
BA_ "FlexKomSigName" SG_ 113 CRC_ENG_RQ_ESC "Eng_Trq_Rq";
BA_ "FlexKomSigLaenge" SG_ 113 CRC_ENG_RQ_ESC 64;
BA_ "FlexKomSID" SG_ 113 CRC_ENG_RQ_ESC 1;
BA_ "FlexKomIsMotorola" SG_ 113 CRC_ENG_RQ_ESC 1;
BA_ "FlexKomComment" SG_ 113 CRC_ENG_RQ_ESC "Engine torque request from ESC";
BA_ "GenSigSNA" SG_ 114 BrkTrq_ILE "FFFh";
BA_ "GenSigCycleTime" SG_ 114 BrkTrq_ILE 20;
BA_ "FlexKomSigStartValue" SG_ 114 BrkTrq_ILE "00000000000000FFh";
BA_ "FlexKomSigStartPos" SG_ 114 BrkTrq_ILE 7;
BA_ "FlexKomSigName" SG_ 114 BrkTrq_ILE "ESP_A11_PKT";
BA_ "FlexKomSigLaenge" SG_ 114 BrkTrq_ILE 64;
BA_ "FlexKomSID" SG_ 114 BrkTrq_ILE 3192;
BA_ "FlexKomIsMotorola" SG_ 114 BrkTrq_ILE 1;
BA_ "FlexKomComment" SG_ 114 BrkTrq_ILE "ESP_A11_PKT";
BA_ "GenSigSNA" SG_ 114 MC_ESP_A11 "0h";
BA_ "GenSigCycleTime" SG_ 114 MC_ESP_A11 20;
BA_ "FlexKomSigStartValue" SG_ 114 MC_ESP_A11 "00000000000000FFh";
BA_ "FlexKomSigStartPos" SG_ 114 MC_ESP_A11 7;
BA_ "FlexKomSigName" SG_ 114 MC_ESP_A11 "ESP_A11_PKT";
BA_ "FlexKomSigLaenge" SG_ 114 MC_ESP_A11 64;
BA_ "FlexKomSID" SG_ 114 MC_ESP_A11 3192;
BA_ "FlexKomIsMotorola" SG_ 114 MC_ESP_A11 1;
BA_ "FlexKomComment" SG_ 114 MC_ESP_A11 "ESP_A11_PKT";
BA_ "GenSigStartValue" SG_ 114 CRC_ESP_A11 255;
BA_ "GenSigSNA" SG_ 114 CRC_ESP_A11 "FFh";
BA_ "GenSigCycleTime" SG_ 114 CRC_ESP_A11 20;
BA_ "FlexKomSigStartValue" SG_ 114 CRC_ESP_A11 "00000000000000FFh";
BA_ "FlexKomSigStartPos" SG_ 114 CRC_ESP_A11 7;
BA_ "FlexKomSigName" SG_ 114 CRC_ESP_A11 "ESP_A11_PKT";
BA_ "FlexKomSigLaenge" SG_ 114 CRC_ESP_A11 64;
BA_ "FlexKomSID" SG_ 114 CRC_ESP_A11 3192;
BA_ "FlexKomIsMotorola" SG_ 114 CRC_ESP_A11 1;
BA_ "FlexKomComment" SG_ 114 CRC_ESP_A11 "ESP_A11_PKT";
BA_ "GenSigSNA" SG_ 117 WhlTrq_Rq_As_2 "FFFFh";
BA_ "GenSigCycleTime" SG_ 117 WhlTrq_Rq_As_2 20;
BA_ "FlexKomSigStartValue" SG_ 117 WhlTrq_Rq_As_2 "00000000000000FFh";
BA_ "FlexKomSigStartPos" SG_ 117 WhlTrq_Rq_As_2 7;
BA_ "FlexKomSigName" SG_ 117 WhlTrq_Rq_As_2 "ESP_A9_Pkt";
BA_ "FlexKomSigLaenge" SG_ 117 WhlTrq_Rq_As_2 64;
BA_ "FlexKomSID" SG_ 117 WhlTrq_Rq_As_2 2519;
BA_ "FlexKomIsMotorola" SG_ 117 WhlTrq_Rq_As_2 1;
BA_ "FlexKomComment" SG_ 117 WhlTrq_Rq_As_2 "ESP_A9_Pkt";
BA_ "GenSigSNA" SG_ 117 WhlTrqAct_Rq_AS "0h";
BA_ "GenSigCycleTime" SG_ 117 WhlTrqAct_Rq_AS 20;
BA_ "FlexKomSigStartValue" SG_ 117 WhlTrqAct_Rq_AS "00000000000000FFh";
BA_ "FlexKomSigStartPos" SG_ 117 WhlTrqAct_Rq_AS 7;
BA_ "FlexKomSigName" SG_ 117 WhlTrqAct_Rq_AS "ESP_A9_Pkt";
BA_ "FlexKomSigLaenge" SG_ 117 WhlTrqAct_Rq_AS 64;
BA_ "FlexKomSID" SG_ 117 WhlTrqAct_Rq_AS 2519;
BA_ "FlexKomIsMotorola" SG_ 117 WhlTrqAct_Rq_AS 1;
BA_ "FlexKomComment" SG_ 117 WhlTrqAct_Rq_AS "ESP_A9_Pkt";
BA_ "GenSigSNA" SG_ 117 MC_10Eh "0h";
BA_ "GenSigCycleTime" SG_ 117 MC_10Eh 20;
BA_ "FlexKomSigStartValue" SG_ 117 MC_10Eh "00000000000000FFh";
BA_ "FlexKomSigStartPos" SG_ 117 MC_10Eh 7;
BA_ "FlexKomSigName" SG_ 117 MC_10Eh "ESP_A9_Pkt";
BA_ "FlexKomSigLaenge" SG_ 117 MC_10Eh 64;
BA_ "FlexKomSID" SG_ 117 MC_10Eh 2519;
BA_ "FlexKomIsMotorola" SG_ 117 MC_10Eh 1;
BA_ "FlexKomComment" SG_ 117 MC_10Eh "ESP_A9_Pkt";
BA_ "GenSigStartValue" SG_ 117 CRC_10Eh 255;
BA_ "GenSigSNA" SG_ 117 CRC_10Eh "FFh";
BA_ "GenSigCycleTime" SG_ 117 CRC_10Eh 20;
BA_ "FlexKomSigStartValue" SG_ 117 CRC_10Eh "00000000000000FFh";
BA_ "FlexKomSigStartPos" SG_ 117 CRC_10Eh 7;
BA_ "FlexKomSigName" SG_ 117 CRC_10Eh "ESP_A9_Pkt";
BA_ "FlexKomSigLaenge" SG_ 117 CRC_10Eh 64;
BA_ "FlexKomSID" SG_ 117 CRC_10Eh 2519;
BA_ "FlexKomIsMotorola" SG_ 117 CRC_10Eh 1;
BA_ "FlexKomComment" SG_ 117 CRC_10Eh "ESP_A9_Pkt";
BA_ "GenSigTimeout_TCM" SG_ 119 CmdIgnStat 210;
BA_ "GenSigTimeout_SCCM" SG_ 119 CmdIgnStat 210;
BA_ "GenSigTimeout_PTS" SG_ 119 CmdIgnStat 210;
BA_ "GenSigTimeout_ORC" SG_ 119 CmdIgnStat 70;
BA_ "GenSigTimeout_IC" SG_ 119 CmdIgnStat 210;
BA_ "GenSigTimeout_ESM" SG_ 119 CmdIgnStat 310;
BA_ "GenSigTimeout_ESL" SG_ 119 CmdIgnStat 110;
BA_ "GenSigTimeout_EHPS" SG_ 119 CmdIgnStat 210;
BA_ "GenSigTimeout_DTCM" SG_ 119 CmdIgnStat 210;
BA_ "GenSigTimeout_ASBS" SG_ 119 CmdIgnStat 410;
BA_ "GenSigTimeout_AHLM" SG_ 119 CmdIgnStat 210;
BA_ "GenSigSNA" SG_ 119 CmdIgnStat "7h";
BA_ "GenSigCycleTime" SG_ 119 CmdIgnStat 20;
BA_ "FlexKomSigStartValue" SG_ 119 CmdIgnStat "0000h";
BA_ "FlexKomSigStartPos" SG_ 119 CmdIgnStat 7;
BA_ "FlexKomSigName" SG_ 119 CmdIgnStat "VehStart_PKT";
BA_ "FlexKomSigLaenge" SG_ 119 CmdIgnStat 16;
BA_ "FlexKomSID" SG_ 119 CmdIgnStat 880;
BA_ "FlexKomIsMotorola" SG_ 119 CmdIgnStat 1;
BA_ "FlexKomComment" SG_ 119 CmdIgnStat "Vehicle start packet";
BA_ "GenSigTimeout_ORC" SG_ 119 StTyp 70;
BA_ "GenSigTimeout_IC" SG_ 119 StTyp 210;
BA_ "GenSigSNA" SG_ 119 StTyp "7h";
BA_ "GenSigCycleTime" SG_ 119 StTyp 20;
BA_ "FlexKomSigStartValue" SG_ 119 StTyp "0000h";
BA_ "FlexKomSigStartPos" SG_ 119 StTyp 7;
BA_ "FlexKomSigName" SG_ 119 StTyp "VehStart_PKT";
BA_ "FlexKomSigLaenge" SG_ 119 StTyp 16;
BA_ "FlexKomSID" SG_ 119 StTyp 880;
BA_ "FlexKomIsMotorola" SG_ 119 StTyp 1;
BA_ "FlexKomComment" SG_ 119 StTyp "Vehicle start packet";
BA_ "GenSigTimeout_ORC" SG_ 119 RemStActv 70;
BA_ "GenSigTimeout_IC" SG_ 119 RemStActv 210;
BA_ "GenSigTimeout_ESM" SG_ 119 RemStActv 310;
BA_ "GenSigSNA" SG_ 119 RemStActv "0h";
BA_ "GenSigCycleTime" SG_ 119 RemStActv 20;
BA_ "FlexKomSigStartValue" SG_ 119 RemStActv "0000h";
BA_ "FlexKomSigStartPos" SG_ 119 RemStActv 7;
BA_ "FlexKomSigName" SG_ 119 RemStActv "VehStart_PKT";
BA_ "FlexKomSigLaenge" SG_ 119 RemStActv 16;
BA_ "FlexKomSID" SG_ 119 RemStActv 880;
BA_ "FlexKomIsMotorola" SG_ 119 RemStActv 1;
BA_ "FlexKomComment" SG_ 119 RemStActv "Vehicle start packet";
BA_ "GenSigTimeout_ORC" SG_ 119 KeyInIgn 70;
BA_ "GenSigTimeout_IC" SG_ 119 KeyInIgn 210;
BA_ "GenSigTimeout_ESM" SG_ 119 KeyInIgn 310;
BA_ "GenSigTimeout_ESL" SG_ 119 KeyInIgn 110;
BA_ "GenSigSNA" SG_ 119 KeyInIgn "3h";
BA_ "GenSigCycleTime" SG_ 119 KeyInIgn 20;
BA_ "FlexKomSigStartValue" SG_ 119 KeyInIgn "0000h";
BA_ "FlexKomSigStartPos" SG_ 119 KeyInIgn 7;
BA_ "FlexKomSigName" SG_ 119 KeyInIgn "VehStart_PKT";
BA_ "FlexKomSigLaenge" SG_ 119 KeyInIgn 16;
BA_ "FlexKomSID" SG_ 119 KeyInIgn 880;
BA_ "FlexKomIsMotorola" SG_ 119 KeyInIgn 1;
BA_ "FlexKomComment" SG_ 119 KeyInIgn "Vehicle start packet";
BA_ "GenSigSNA" SG_ 119 StartRelayBCMSts "0h";
BA_ "GenSigCycleTime" SG_ 119 StartRelayBCMSts 20;
BA_ "FlexKomSigStartValue" SG_ 119 StartRelayBCMSts "00h";
BA_ "FlexKomSigStartPos" SG_ 119 StartRelayBCMSts 13;
BA_ "FlexKomSigName" SG_ 119 StartRelayBCMSts "StartRelayBCMSts";
BA_ "FlexKomSigLaenge" SG_ 119 StartRelayBCMSts 1;
BA_ "FlexKomSID" SG_ 119 StartRelayBCMSts 1526;
BA_ "FlexKomIsMotorola" SG_ 119 StartRelayBCMSts 1;
BA_ "FlexKomComment" SG_ 119 StartRelayBCMSts "CBC starter relay status; [1] = ON";
BA_ "GenSigTimeout_ORC" SG_ 119 StartRelayBCMFault 70;
BA_ "GenSigSNA" SG_ 119 StartRelayBCMFault "0h";
BA_ "GenSigCycleTime" SG_ 119 StartRelayBCMFault 20;
BA_ "FlexKomSigStartValue" SG_ 119 StartRelayBCMFault "00h";
BA_ "FlexKomSigStartPos" SG_ 119 StartRelayBCMFault 14;
BA_ "FlexKomSigName" SG_ 119 StartRelayBCMFault "StartRelayBCMFault";
BA_ "FlexKomSigLaenge" SG_ 119 StartRelayBCMFault 1;
BA_ "FlexKomSID" SG_ 119 StartRelayBCMFault 1573;
BA_ "FlexKomIsMotorola" SG_ 119 StartRelayBCMFault 1;
BA_ "FlexKomComment" SG_ 119 StartRelayBCMFault "CBC starter relay fault detected";
BA_ "GenSigSNA" SG_ 120 BrakeBoostPressure "7FFh";
BA_ "GenSigCycleTime" SG_ 120 BrakeBoostPressure 20;
BA_ "FlexKomSigStartValue" SG_ 120 BrakeBoostPressure "00000000000000FFh";
BA_ "FlexKomSigStartPos" SG_ 120 BrakeBoostPressure 7;
BA_ "FlexKomSigName" SG_ 120 BrakeBoostPressure "ESP_A10_Pkt";
BA_ "FlexKomSigLaenge" SG_ 120 BrakeBoostPressure 64;
BA_ "FlexKomSID" SG_ 120 BrakeBoostPressure 2964;
BA_ "FlexKomIsMotorola" SG_ 120 BrakeBoostPressure 1;
BA_ "FlexKomComment" SG_ 120 BrakeBoostPressure "ESP_A10_Pkt";
BA_ "GenSigSNA" SG_ 120 BrakePedalPressure "7FFh";
BA_ "GenSigCycleTime" SG_ 120 BrakePedalPressure 20;
BA_ "FlexKomSigStartValue" SG_ 120 BrakePedalPressure "00000000000000FFh";
BA_ "FlexKomSigStartPos" SG_ 120 BrakePedalPressure 7;
BA_ "FlexKomSigName" SG_ 120 BrakePedalPressure "ESP_A10_Pkt";
BA_ "FlexKomSigLaenge" SG_ 120 BrakePedalPressure 64;
BA_ "FlexKomSID" SG_ 120 BrakePedalPressure 2964;
BA_ "FlexKomIsMotorola" SG_ 120 BrakePedalPressure 1;
BA_ "FlexKomComment" SG_ 120 BrakePedalPressure "ESP_A10_Pkt";
BA_ "GenSigSNA" SG_ 120 BrakePdlPosn "FFh";
BA_ "GenSigCycleTime" SG_ 120 BrakePdlPosn 20;
BA_ "FlexKomSigStartValue" SG_ 120 BrakePdlPosn "00000000000000FFh";
BA_ "FlexKomSigStartPos" SG_ 120 BrakePdlPosn 7;
BA_ "FlexKomSigName" SG_ 120 BrakePdlPosn "ESP_A10_Pkt";
BA_ "FlexKomSigLaenge" SG_ 120 BrakePdlPosn 64;
BA_ "FlexKomSID" SG_ 120 BrakePdlPosn 2964;
BA_ "FlexKomIsMotorola" SG_ 120 BrakePdlPosn 1;
BA_ "FlexKomComment" SG_ 120 BrakePdlPosn "ESP_A10_Pkt";
BA_ "GenSigSNA" SG_ 120 BrakeBoostStat "Fh";
BA_ "GenSigCycleTime" SG_ 120 BrakeBoostStat 20;
BA_ "FlexKomSigStartValue" SG_ 120 BrakeBoostStat "00000000000000FFh";
BA_ "FlexKomSigStartPos" SG_ 120 BrakeBoostStat 7;
BA_ "FlexKomSigName" SG_ 120 BrakeBoostStat "ESP_A10_Pkt";
BA_ "FlexKomSigLaenge" SG_ 120 BrakeBoostStat 64;
BA_ "FlexKomSID" SG_ 120 BrakeBoostStat 2964;
BA_ "FlexKomIsMotorola" SG_ 120 BrakeBoostStat 1;
BA_ "FlexKomComment" SG_ 120 BrakeBoostStat "ESP_A10_Pkt";
BA_ "GenSigSNA" SG_ 120 BSMHybridModeReq "3h";
BA_ "GenSigCycleTime" SG_ 120 BSMHybridModeReq 20;
BA_ "FlexKomSigStartValue" SG_ 120 BSMHybridModeReq "00000000000000FFh";
BA_ "FlexKomSigStartPos" SG_ 120 BSMHybridModeReq 7;
BA_ "FlexKomSigName" SG_ 120 BSMHybridModeReq "ESP_A10_Pkt";
BA_ "FlexKomSigLaenge" SG_ 120 BSMHybridModeReq 64;
BA_ "FlexKomSID" SG_ 120 BSMHybridModeReq 2964;
BA_ "FlexKomIsMotorola" SG_ 120 BSMHybridModeReq 1;
BA_ "FlexKomComment" SG_ 120 BSMHybridModeReq "ESP_A10_Pkt";
BA_ "GenSigSNA" SG_ 120 MC_ESP_A10 "0h";
BA_ "GenSigCycleTime" SG_ 120 MC_ESP_A10 20;
BA_ "FlexKomSigStartValue" SG_ 120 MC_ESP_A10 "00000000000000FFh";
BA_ "FlexKomSigStartPos" SG_ 120 MC_ESP_A10 7;
BA_ "FlexKomSigName" SG_ 120 MC_ESP_A10 "ESP_A10_Pkt";
BA_ "FlexKomSigLaenge" SG_ 120 MC_ESP_A10 64;
BA_ "FlexKomSID" SG_ 120 MC_ESP_A10 2964;
BA_ "FlexKomIsMotorola" SG_ 120 MC_ESP_A10 1;
BA_ "FlexKomComment" SG_ 120 MC_ESP_A10 "ESP_A10_Pkt";
BA_ "GenSigStartValue" SG_ 120 CRC_ESP_A10 255;
BA_ "GenSigSNA" SG_ 120 CRC_ESP_A10 "FFh";
BA_ "GenSigCycleTime" SG_ 120 CRC_ESP_A10 20;
BA_ "FlexKomSigStartValue" SG_ 120 CRC_ESP_A10 "00000000000000FFh";
BA_ "FlexKomSigStartPos" SG_ 120 CRC_ESP_A10 7;
BA_ "FlexKomSigName" SG_ 120 CRC_ESP_A10 "ESP_A10_Pkt";
BA_ "FlexKomSigLaenge" SG_ 120 CRC_ESP_A10 64;
BA_ "FlexKomSID" SG_ 120 CRC_ESP_A10 2964;
BA_ "FlexKomIsMotorola" SG_ 120 CRC_ESP_A10 1;
BA_ "FlexKomComment" SG_ 120 CRC_ESP_A10 "ESP_A10_Pkt";
BA_ "GenSigTimeout_ESM" SG_ 121 BrkTrq 210;
BA_ "GenSigTimeout_CBC" SG_ 121 BrkTrq 210;
BA_ "GenSigStartValue" SG_ 121 BrkTrq 4095;
BA_ "GenSigSNA" SG_ 121 BrkTrq "FFFh";
BA_ "GenSigCycleTime" SG_ 121 BrkTrq 20;
BA_ "FlexKomSigStartValue" SG_ 121 BrkTrq "0FFF0FFFFFFF00FFh";
BA_ "FlexKomSigStartPos" SG_ 121 BrkTrq 7;
BA_ "FlexKomSigName" SG_ 121 BrkTrq "VEH_SPEED_PKT";
BA_ "FlexKomSigLaenge" SG_ 121 BrkTrq 64;
BA_ "FlexKomSID" SG_ 121 BrkTrq 11;
BA_ "FlexKomIsMotorola" SG_ 121 BrkTrq 1;
BA_ "FlexKomComment" SG_ 121 BrkTrq "Vehicle Speed Packet";
BA_ "GenSigSNA" SG_ 121 VehSpSts "0h";
BA_ "GenSigCycleTime" SG_ 121 VehSpSts 20;
BA_ "FlexKomSigStartValue" SG_ 121 VehSpSts "0FFF0FFFFFFF00FFh";
BA_ "FlexKomSigStartPos" SG_ 121 VehSpSts 7;
BA_ "FlexKomSigName" SG_ 121 VehSpSts "VEH_SPEED_PKT";
BA_ "FlexKomSigLaenge" SG_ 121 VehSpSts 64;
BA_ "FlexKomSID" SG_ 121 VehSpSts 11;
BA_ "FlexKomIsMotorola" SG_ 121 VehSpSts 1;
BA_ "FlexKomComment" SG_ 121 VehSpSts "Vehicle Speed Packet";
BA_ "GenSigTimeout_ESM" SG_ 121 BrkTrq_D 210;
BA_ "GenSigTimeout_DTCM" SG_ 121 BrkTrq_D 210;
BA_ "GenSigStartValue" SG_ 121 BrkTrq_D 4095;
BA_ "GenSigSNA" SG_ 121 BrkTrq_D "FFFh";
BA_ "GenSigCycleTime" SG_ 121 BrkTrq_D 20;
BA_ "FlexKomSigStartValue" SG_ 121 BrkTrq_D "0FFF0FFFFFFF00FFh";
BA_ "FlexKomSigStartPos" SG_ 121 BrkTrq_D 7;
BA_ "FlexKomSigName" SG_ 121 BrkTrq_D "VEH_SPEED_PKT";
BA_ "FlexKomSigLaenge" SG_ 121 BrkTrq_D 64;
BA_ "FlexKomSID" SG_ 121 BrkTrq_D 11;
BA_ "FlexKomIsMotorola" SG_ 121 BrkTrq_D 1;
BA_ "FlexKomComment" SG_ 121 BrkTrq_D "Vehicle Speed Packet";
BA_ "RID" SG_ 121 VEH_SPEED "2861 2862 2863";
BA_ "GenSigTimeout_TCM" SG_ 121 VEH_SPEED 210;
BA_ "GenSigTimeout_RF_HUB" SG_ 121 VEH_SPEED 210;
BA_ "GenSigTimeout_ORC" SG_ 121 VEH_SPEED 70;
BA_ "GenSigTimeout_IC" SG_ 121 VEH_SPEED 210;
BA_ "GenSigTimeout_ESM" SG_ 121 VEH_SPEED 210;
BA_ "GenSigTimeout_ESL" SG_ 121 VEH_SPEED 110;
BA_ "GenSigTimeout_EHPS" SG_ 121 VEH_SPEED 210;
BA_ "GenSigTimeout_DTCM" SG_ 121 VEH_SPEED 210;
BA_ "GenSigTimeout_CBC" SG_ 121 VEH_SPEED 110;
BA_ "GenSigStartValue" SG_ 121 VEH_SPEED 65535;
BA_ "GenSigSNA" SG_ 121 VEH_SPEED "FFFFh";
BA_ "GenSigCycleTime" SG_ 121 VEH_SPEED 20;
BA_ "FlexKomSigStartValue" SG_ 121 VEH_SPEED "0FFF0FFFFFFF00FFh";
BA_ "FlexKomSigStartPos" SG_ 121 VEH_SPEED 7;
BA_ "FlexKomSigName" SG_ 121 VEH_SPEED "VEH_SPEED_PKT";
BA_ "FlexKomSigLaenge" SG_ 121 VEH_SPEED 64;
BA_ "FlexKomSID" SG_ 121 VEH_SPEED 11;
BA_ "FlexKomIsMotorola" SG_ 121 VEH_SPEED 1;
BA_ "FlexKomComment" SG_ 121 VEH_SPEED "Vehicle Speed Packet";
BA_ "GenSigTimeout_ORC" SG_ 121 MC_VEH_SPEED 70;
BA_ "GenSigTimeout_IC" SG_ 121 MC_VEH_SPEED 210;
BA_ "GenSigTimeout_ESM" SG_ 121 MC_VEH_SPEED 210;
BA_ "GenSigTimeout_ESL" SG_ 121 MC_VEH_SPEED 110;
BA_ "GenSigTimeout_CBC" SG_ 121 MC_VEH_SPEED 110;
BA_ "GenSigSNA" SG_ 121 MC_VEH_SPEED "0h";
BA_ "GenSigCycleTime" SG_ 121 MC_VEH_SPEED 20;
BA_ "FlexKomSigStartValue" SG_ 121 MC_VEH_SPEED "0FFF0FFFFFFF00FFh";
BA_ "FlexKomSigStartPos" SG_ 121 MC_VEH_SPEED 7;
BA_ "FlexKomSigName" SG_ 121 MC_VEH_SPEED "VEH_SPEED_PKT";
BA_ "FlexKomSigLaenge" SG_ 121 MC_VEH_SPEED 64;
BA_ "FlexKomSID" SG_ 121 MC_VEH_SPEED 11;
BA_ "FlexKomIsMotorola" SG_ 121 MC_VEH_SPEED 1;
BA_ "FlexKomComment" SG_ 121 MC_VEH_SPEED "Vehicle Speed Packet";
BA_ "GenSigTimeout_ORC" SG_ 121 CRC_VEH_SPEED 70;
BA_ "GenSigTimeout_IC" SG_ 121 CRC_VEH_SPEED 210;
BA_ "GenSigTimeout_ESM" SG_ 121 CRC_VEH_SPEED 210;
BA_ "GenSigTimeout_ESL" SG_ 121 CRC_VEH_SPEED 110;
BA_ "GenSigTimeout_CBC" SG_ 121 CRC_VEH_SPEED 110;
BA_ "GenSigStartValue" SG_ 121 CRC_VEH_SPEED 255;
BA_ "GenSigSNA" SG_ 121 CRC_VEH_SPEED "FFh";
BA_ "GenSigCycleTime" SG_ 121 CRC_VEH_SPEED 20;
BA_ "FlexKomSigStartValue" SG_ 121 CRC_VEH_SPEED "0FFF0FFFFFFF00FFh";
BA_ "FlexKomSigStartPos" SG_ 121 CRC_VEH_SPEED 7;
BA_ "FlexKomSigName" SG_ 121 CRC_VEH_SPEED "VEH_SPEED_PKT";
BA_ "FlexKomSigLaenge" SG_ 121 CRC_VEH_SPEED 64;
BA_ "FlexKomSID" SG_ 121 CRC_VEH_SPEED 11;
BA_ "FlexKomIsMotorola" SG_ 121 CRC_VEH_SPEED 1;
BA_ "FlexKomComment" SG_ 121 CRC_VEH_SPEED "Vehicle Speed Packet";
BA_ "GenSigTimeout_TCM" SG_ 123 EngTrqSel_D_TTC 210;
BA_ "GenSigTimeout_DTCM" SG_ 123 EngTrqSel_D_TTC 210;
BA_ "GenSigStartValue" SG_ 123 EngTrqSel_D_TTC 8191;
BA_ "GenSigSNA" SG_ 123 EngTrqSel_D_TTC "1FFFh";
BA_ "GenSigCycleTime" SG_ 123 EngTrqSel_D_TTC 20;
BA_ "FlexKomSigStartValue" SG_ 123 EngTrqSel_D_TTC "1FFFFF1FFF00FFh";
BA_ "FlexKomSigStartPos" SG_ 123 EngTrqSel_D_TTC 7;
BA_ "FlexKomSigName" SG_ 123 EngTrqSel_D_TTC "ECM_A2_PKT";
BA_ "FlexKomSigLaenge" SG_ 123 EngTrqSel_D_TTC 56;
BA_ "FlexKomSID" SG_ 123 EngTrqSel_D_TTC 455;
BA_ "FlexKomIsMotorola" SG_ 123 EngTrqSel_D_TTC 1;
BA_ "FlexKomComment" SG_ 123 EngTrqSel_D_TTC "ECM_A2 Packet";
BA_ "GenSigSNA" SG_ 123 EngTrq_Enbl_Rq_AS "0h";
BA_ "GenSigCycleTime" SG_ 123 EngTrq_Enbl_Rq_AS 20;
BA_ "FlexKomSigStartValue" SG_ 123 EngTrq_Enbl_Rq_AS "1FFFFF1FFF00FFh";
BA_ "FlexKomSigStartPos" SG_ 123 EngTrq_Enbl_Rq_AS 7;
BA_ "FlexKomSigName" SG_ 123 EngTrq_Enbl_Rq_AS "ECM_A2_PKT";
BA_ "FlexKomSigLaenge" SG_ 123 EngTrq_Enbl_Rq_AS 56;
BA_ "FlexKomSID" SG_ 123 EngTrq_Enbl_Rq_AS 455;
BA_ "FlexKomIsMotorola" SG_ 123 EngTrq_Enbl_Rq_AS 1;
BA_ "FlexKomComment" SG_ 123 EngTrq_Enbl_Rq_AS "ECM_A2 Packet";
BA_ "GenSigSNA" SG_ 123 EngTrq_Enbl_Rq_ESC "0h";
BA_ "GenSigCycleTime" SG_ 123 EngTrq_Enbl_Rq_ESC 20;
BA_ "FlexKomSigStartValue" SG_ 123 EngTrq_Enbl_Rq_ESC "1FFFFF1FFF00FFh";
BA_ "FlexKomSigStartPos" SG_ 123 EngTrq_Enbl_Rq_ESC 7;
BA_ "FlexKomSigName" SG_ 123 EngTrq_Enbl_Rq_ESC "ECM_A2_PKT";
BA_ "FlexKomSigLaenge" SG_ 123 EngTrq_Enbl_Rq_ESC 56;
BA_ "FlexKomSID" SG_ 123 EngTrq_Enbl_Rq_ESC 455;
BA_ "FlexKomIsMotorola" SG_ 123 EngTrq_Enbl_Rq_ESC 1;
BA_ "FlexKomComment" SG_ 123 EngTrq_Enbl_Rq_ESC "ECM_A2 Packet";
BA_ "GenSigTimeout_TCM" SG_ 123 EngTrq_Enbl_Rq_TCM 210;
BA_ "GenSigSNA" SG_ 123 EngTrq_Enbl_Rq_TCM "0h";
BA_ "GenSigCycleTime" SG_ 123 EngTrq_Enbl_Rq_TCM 20;
BA_ "FlexKomSigStartValue" SG_ 123 EngTrq_Enbl_Rq_TCM "1FFFFF1FFF00FFh";
BA_ "FlexKomSigStartPos" SG_ 123 EngTrq_Enbl_Rq_TCM 7;
BA_ "FlexKomSigName" SG_ 123 EngTrq_Enbl_Rq_TCM "ECM_A2_PKT";
BA_ "FlexKomSigLaenge" SG_ 123 EngTrq_Enbl_Rq_TCM 56;
BA_ "FlexKomSID" SG_ 123 EngTrq_Enbl_Rq_TCM 455;
BA_ "FlexKomIsMotorola" SG_ 123 EngTrq_Enbl_Rq_TCM 1;
BA_ "FlexKomComment" SG_ 123 EngTrq_Enbl_Rq_TCM "ECM_A2 Packet";
BA_ "RID" SG_ 123 AccelPdlPosn "5036";
BA_ "GenSigTimeout_TCM" SG_ 123 AccelPdlPosn 210;
BA_ "GenSigTimeout_ETM" SG_ 123 AccelPdlPosn 210;
BA_ "GenSigTimeout_DTCM" SG_ 123 AccelPdlPosn 210;
BA_ "GenSigStartValue" SG_ 123 AccelPdlPosn 255;
BA_ "GenSigSNA" SG_ 123 AccelPdlPosn "FFh";
BA_ "GenSigCycleTime" SG_ 123 AccelPdlPosn 20;
BA_ "FlexKomSigStartValue" SG_ 123 AccelPdlPosn "1FFFFF1FFF00FFh";
BA_ "FlexKomSigStartPos" SG_ 123 AccelPdlPosn 7;
BA_ "FlexKomSigName" SG_ 123 AccelPdlPosn "ECM_A2_PKT";
BA_ "FlexKomSigLaenge" SG_ 123 AccelPdlPosn 56;
BA_ "FlexKomSID" SG_ 123 AccelPdlPosn 455;
BA_ "FlexKomIsMotorola" SG_ 123 AccelPdlPosn 1;
BA_ "FlexKomComment" SG_ 123 AccelPdlPosn "ECM_A2 Packet";
BA_ "GenSigTimeout_DTCM" SG_ 123 EngTrq_DrvReqMod 210;
BA_ "GenSigStartValue" SG_ 123 EngTrq_DrvReqMod 8191;
BA_ "GenSigSNA" SG_ 123 EngTrq_DrvReqMod "1FFFh";
BA_ "GenSigCycleTime" SG_ 123 EngTrq_DrvReqMod 20;
BA_ "FlexKomSigStartValue" SG_ 123 EngTrq_DrvReqMod "1FFFFF1FFF00FFh";
BA_ "FlexKomSigStartPos" SG_ 123 EngTrq_DrvReqMod 7;
BA_ "FlexKomSigName" SG_ 123 EngTrq_DrvReqMod "ECM_A2_PKT";
BA_ "FlexKomSigLaenge" SG_ 123 EngTrq_DrvReqMod 56;
BA_ "FlexKomSID" SG_ 123 EngTrq_DrvReqMod 455;
BA_ "FlexKomIsMotorola" SG_ 123 EngTrq_DrvReqMod 1;
BA_ "FlexKomComment" SG_ 123 EngTrq_DrvReqMod "ECM_A2 Packet";
BA_ "GenSigTimeout_TCM" SG_ 123 ECM_LHOM 210;
BA_ "GenSigSNA" SG_ 123 ECM_LHOM "0h";
BA_ "GenSigCycleTime" SG_ 123 ECM_LHOM 20;
BA_ "FlexKomSigStartValue" SG_ 123 ECM_LHOM "1FFFFF1FFF00FFh";
BA_ "FlexKomSigStartPos" SG_ 123 ECM_LHOM 7;
BA_ "FlexKomSigName" SG_ 123 ECM_LHOM "ECM_A2_PKT";
BA_ "FlexKomSigLaenge" SG_ 123 ECM_LHOM 56;
BA_ "FlexKomSID" SG_ 123 ECM_LHOM 455;
BA_ "FlexKomIsMotorola" SG_ 123 ECM_LHOM 1;
BA_ "FlexKomComment" SG_ 123 ECM_LHOM "ECM_A2 Packet";
BA_ "RID" SG_ 123 AccelPdlPosnSens_Flt "5031";
BA_ "GenSigTimeout_DTCM" SG_ 123 AccelPdlPosnSens_Flt 210;
BA_ "GenSigSNA" SG_ 123 AccelPdlPosnSens_Flt "0h";
BA_ "GenSigCycleTime" SG_ 123 AccelPdlPosnSens_Flt 20;
BA_ "FlexKomSigStartValue" SG_ 123 AccelPdlPosnSens_Flt "1FFFFF1FFF00FFh";
BA_ "FlexKomSigStartPos" SG_ 123 AccelPdlPosnSens_Flt 7;
BA_ "FlexKomSigName" SG_ 123 AccelPdlPosnSens_Flt "ECM_A2_PKT";
BA_ "FlexKomSigLaenge" SG_ 123 AccelPdlPosnSens_Flt 56;
BA_ "FlexKomSID" SG_ 123 AccelPdlPosnSens_Flt 455;
BA_ "FlexKomIsMotorola" SG_ 123 AccelPdlPosnSens_Flt 1;
BA_ "FlexKomComment" SG_ 123 AccelPdlPosnSens_Flt "ECM_A2 Packet";
BA_ "GenSigTimeout_TCM" SG_ 123 CRUISE_OVERRIDE 210;
BA_ "GenSigTimeout_IC" SG_ 123 CRUISE_OVERRIDE 210;
BA_ "GenSigSNA" SG_ 123 CRUISE_OVERRIDE "0h";
BA_ "GenSigCycleTime" SG_ 123 CRUISE_OVERRIDE 20;
BA_ "FlexKomSigStartValue" SG_ 123 CRUISE_OVERRIDE "1FFFFF1FFF00FFh";
BA_ "FlexKomSigStartPos" SG_ 123 CRUISE_OVERRIDE 7;
BA_ "FlexKomSigName" SG_ 123 CRUISE_OVERRIDE "ECM_A2_PKT";
BA_ "FlexKomSigLaenge" SG_ 123 CRUISE_OVERRIDE 56;
BA_ "FlexKomSID" SG_ 123 CRUISE_OVERRIDE 455;
BA_ "FlexKomIsMotorola" SG_ 123 CRUISE_OVERRIDE 1;
BA_ "FlexKomComment" SG_ 123 CRUISE_OVERRIDE "ECM_A2 Packet";
BA_ "GenSigSNA" SG_ 123 ESS_RqShftPark "0h";
BA_ "GenSigCycleTime" SG_ 123 ESS_RqShftPark 20;
BA_ "FlexKomSigStartValue" SG_ 123 ESS_RqShftPark "1FFFFF1FFF00FFh";
BA_ "FlexKomSigStartPos" SG_ 123 ESS_RqShftPark 7;
BA_ "FlexKomSigName" SG_ 123 ESS_RqShftPark "ECM_A2_PKT";
BA_ "FlexKomSigLaenge" SG_ 123 ESS_RqShftPark 56;
BA_ "FlexKomSID" SG_ 123 ESS_RqShftPark 455;
BA_ "FlexKomIsMotorola" SG_ 123 ESS_RqShftPark 1;
BA_ "FlexKomComment" SG_ 123 ESS_RqShftPark "ECM_A2 Packet";
BA_ "GenSigSNA" SG_ 123 RPMOverRev "0h";
BA_ "GenSigCycleTime" SG_ 123 RPMOverRev 20;
BA_ "FlexKomSigStartValue" SG_ 123 RPMOverRev "1FFFFF1FFF00FFh";
BA_ "FlexKomSigStartPos" SG_ 123 RPMOverRev 7;
BA_ "FlexKomSigName" SG_ 123 RPMOverRev "ECM_A2_PKT";
BA_ "FlexKomSigLaenge" SG_ 123 RPMOverRev 56;
BA_ "FlexKomSID" SG_ 123 RPMOverRev 455;
BA_ "FlexKomIsMotorola" SG_ 123 RPMOverRev 1;
BA_ "FlexKomComment" SG_ 123 RPMOverRev "ECM_A2 Packet";
BA_ "GenSigSNA" SG_ 123 LV12PwrFreeRq "0h";
BA_ "GenSigCycleTime" SG_ 123 LV12PwrFreeRq 20;
BA_ "FlexKomSigStartValue" SG_ 123 LV12PwrFreeRq "1FFFFF1FFF00FFh";
BA_ "FlexKomSigStartPos" SG_ 123 LV12PwrFreeRq 7;
BA_ "FlexKomSigName" SG_ 123 LV12PwrFreeRq "ECM_A2_PKT";
BA_ "FlexKomSigLaenge" SG_ 123 LV12PwrFreeRq 56;
BA_ "FlexKomSID" SG_ 123 LV12PwrFreeRq 455;
BA_ "FlexKomIsMotorola" SG_ 123 LV12PwrFreeRq 1;
BA_ "FlexKomComment" SG_ 123 LV12PwrFreeRq "ECM_A2 Packet";
BA_ "GenSigSNA" SG_ 123 MC_ECM_A2 "0h";
BA_ "GenSigCycleTime" SG_ 123 MC_ECM_A2 20;
BA_ "FlexKomSigStartValue" SG_ 123 MC_ECM_A2 "1FFFFF1FFF00FFh";
BA_ "FlexKomSigStartPos" SG_ 123 MC_ECM_A2 7;
BA_ "FlexKomSigName" SG_ 123 MC_ECM_A2 "ECM_A2_PKT";
BA_ "FlexKomSigLaenge" SG_ 123 MC_ECM_A2 56;
BA_ "FlexKomSID" SG_ 123 MC_ECM_A2 455;
BA_ "FlexKomIsMotorola" SG_ 123 MC_ECM_A2 1;
BA_ "FlexKomComment" SG_ 123 MC_ECM_A2 "ECM_A2 Packet";
BA_ "GenSigStartValue" SG_ 123 CRC_ECM_A2 255;
BA_ "GenSigSNA" SG_ 123 CRC_ECM_A2 "FFh";
BA_ "GenSigCycleTime" SG_ 123 CRC_ECM_A2 20;
BA_ "FlexKomSigStartValue" SG_ 123 CRC_ECM_A2 "1FFFFF1FFF00FFh";
BA_ "FlexKomSigStartPos" SG_ 123 CRC_ECM_A2 7;
BA_ "FlexKomSigName" SG_ 123 CRC_ECM_A2 "ECM_A2_PKT";
BA_ "FlexKomSigLaenge" SG_ 123 CRC_ECM_A2 56;
BA_ "FlexKomSID" SG_ 123 CRC_ECM_A2 455;
BA_ "FlexKomIsMotorola" SG_ 123 CRC_ECM_A2 1;
BA_ "FlexKomComment" SG_ 123 CRC_ECM_A2 "ECM_A2 Packet";
BA_ "GenSigSNA" SG_ 124 EngTrq_Enbl_Rq_AS_PHEV "0h";
BA_ "GenSigCycleTime" SG_ 124 EngTrq_Enbl_Rq_AS_PHEV 20;
BA_ "FlexKomSigStartValue" SG_ 124 EngTrq_Enbl_Rq_AS_PHEV "FF0000001FFF00FFh";
BA_ "FlexKomSigStartPos" SG_ 124 EngTrq_Enbl_Rq_AS_PHEV 7;
BA_ "FlexKomSigName" SG_ 124 EngTrq_Enbl_Rq_AS_PHEV "ECM_A2_PHEV_PKT";
BA_ "FlexKomSigLaenge" SG_ 124 EngTrq_Enbl_Rq_AS_PHEV 64;
BA_ "FlexKomSID" SG_ 124 EngTrq_Enbl_Rq_AS_PHEV 2991;
BA_ "FlexKomIsMotorola" SG_ 124 EngTrq_Enbl_Rq_AS_PHEV 1;
BA_ "FlexKomComment" SG_ 124 EngTrq_Enbl_Rq_AS_PHEV "ECM_A2_PHEV_PKT";
BA_ "GenSigSNA" SG_ 124 EngTrq_Enbl_Rq_ESC_PHEV "0h";
BA_ "GenSigCycleTime" SG_ 124 EngTrq_Enbl_Rq_ESC_PHEV 20;
BA_ "FlexKomSigStartValue" SG_ 124 EngTrq_Enbl_Rq_ESC_PHEV "FF0000001FFF00FFh";
BA_ "FlexKomSigStartPos" SG_ 124 EngTrq_Enbl_Rq_ESC_PHEV 7;
BA_ "FlexKomSigName" SG_ 124 EngTrq_Enbl_Rq_ESC_PHEV "ECM_A2_PHEV_PKT";
BA_ "FlexKomSigLaenge" SG_ 124 EngTrq_Enbl_Rq_ESC_PHEV 64;
BA_ "FlexKomSID" SG_ 124 EngTrq_Enbl_Rq_ESC_PHEV 2991;
BA_ "FlexKomIsMotorola" SG_ 124 EngTrq_Enbl_Rq_ESC_PHEV 1;
BA_ "FlexKomComment" SG_ 124 EngTrq_Enbl_Rq_ESC_PHEV "ECM_A2_PHEV_PKT";
BA_ "GenSigTimeout_TCM" SG_ 124 EngTrq_Enbl_Rq_TCM_PHEV 210;
BA_ "GenSigSNA" SG_ 124 EngTrq_Enbl_Rq_TCM_PHEV "0h";
BA_ "GenSigCycleTime" SG_ 124 EngTrq_Enbl_Rq_TCM_PHEV 20;
BA_ "FlexKomSigStartValue" SG_ 124 EngTrq_Enbl_Rq_TCM_PHEV "FF0000001FFF00FFh";
BA_ "FlexKomSigStartPos" SG_ 124 EngTrq_Enbl_Rq_TCM_PHEV 7;
BA_ "FlexKomSigName" SG_ 124 EngTrq_Enbl_Rq_TCM_PHEV "ECM_A2_PHEV_PKT";
BA_ "FlexKomSigLaenge" SG_ 124 EngTrq_Enbl_Rq_TCM_PHEV 64;
BA_ "FlexKomSID" SG_ 124 EngTrq_Enbl_Rq_TCM_PHEV 2991;
BA_ "FlexKomIsMotorola" SG_ 124 EngTrq_Enbl_Rq_TCM_PHEV 1;
BA_ "FlexKomComment" SG_ 124 EngTrq_Enbl_Rq_TCM_PHEV "ECM_A2_PHEV_PKT";
BA_ "GenSigTimeout_TCM" SG_ 124 ECM_LHOM_PHEV 210;
BA_ "GenSigSNA" SG_ 124 ECM_LHOM_PHEV "0h";
BA_ "GenSigCycleTime" SG_ 124 ECM_LHOM_PHEV 20;
BA_ "FlexKomSigStartValue" SG_ 124 ECM_LHOM_PHEV "FF0000001FFF00FFh";
BA_ "FlexKomSigStartPos" SG_ 124 ECM_LHOM_PHEV 7;
BA_ "FlexKomSigName" SG_ 124 ECM_LHOM_PHEV "ECM_A2_PHEV_PKT";
BA_ "FlexKomSigLaenge" SG_ 124 ECM_LHOM_PHEV 64;
BA_ "FlexKomSID" SG_ 124 ECM_LHOM_PHEV 2991;
BA_ "FlexKomIsMotorola" SG_ 124 ECM_LHOM_PHEV 1;
BA_ "FlexKomComment" SG_ 124 ECM_LHOM_PHEV "ECM_A2_PHEV_PKT";
BA_ "RID" SG_ 124 AccelPdlPosnSens_Flt_PHEV "6416";
BA_ "GenSigTimeout_DTCM" SG_ 124 AccelPdlPosnSens_Flt_PHEV 210;
BA_ "GenSigSNA" SG_ 124 AccelPdlPosnSens_Flt_PHEV "0h";
BA_ "GenSigCycleTime" SG_ 124 AccelPdlPosnSens_Flt_PHEV 20;
BA_ "FlexKomSigStartValue" SG_ 124 AccelPdlPosnSens_Flt_PHEV "FF0000001FFF00FFh";
BA_ "FlexKomSigStartPos" SG_ 124 AccelPdlPosnSens_Flt_PHEV 7;
BA_ "FlexKomSigName" SG_ 124 AccelPdlPosnSens_Flt_PHEV "ECM_A2_PHEV_PKT";
BA_ "FlexKomSigLaenge" SG_ 124 AccelPdlPosnSens_Flt_PHEV 64;
BA_ "FlexKomSID" SG_ 124 AccelPdlPosnSens_Flt_PHEV 2991;
BA_ "FlexKomIsMotorola" SG_ 124 AccelPdlPosnSens_Flt_PHEV 1;
BA_ "FlexKomComment" SG_ 124 AccelPdlPosnSens_Flt_PHEV "ECM_A2_PHEV_PKT";
BA_ "GenSigTimeout_TCM" SG_ 124 CRUISE_OVERRIDE_PHEV 210;
BA_ "GenSigTimeout_IC" SG_ 124 CRUISE_OVERRIDE_PHEV 210;
BA_ "GenSigSNA" SG_ 124 CRUISE_OVERRIDE_PHEV "0h";
BA_ "GenSigCycleTime" SG_ 124 CRUISE_OVERRIDE_PHEV 20;
BA_ "FlexKomSigStartValue" SG_ 124 CRUISE_OVERRIDE_PHEV "FF0000001FFF00FFh";
BA_ "FlexKomSigStartPos" SG_ 124 CRUISE_OVERRIDE_PHEV 7;
BA_ "FlexKomSigName" SG_ 124 CRUISE_OVERRIDE_PHEV "ECM_A2_PHEV_PKT";
BA_ "FlexKomSigLaenge" SG_ 124 CRUISE_OVERRIDE_PHEV 64;
BA_ "FlexKomSID" SG_ 124 CRUISE_OVERRIDE_PHEV 2991;
BA_ "FlexKomIsMotorola" SG_ 124 CRUISE_OVERRIDE_PHEV 1;
BA_ "FlexKomComment" SG_ 124 CRUISE_OVERRIDE_PHEV "ECM_A2_PHEV_PKT";
BA_ "GenSigSNA" SG_ 124 ESS_RqShftPark_PHEV "0h";
BA_ "GenSigCycleTime" SG_ 124 ESS_RqShftPark_PHEV 20;
BA_ "FlexKomSigStartValue" SG_ 124 ESS_RqShftPark_PHEV "FF0000001FFF00FFh";
BA_ "FlexKomSigStartPos" SG_ 124 ESS_RqShftPark_PHEV 7;
BA_ "FlexKomSigName" SG_ 124 ESS_RqShftPark_PHEV "ECM_A2_PHEV_PKT";
BA_ "FlexKomSigLaenge" SG_ 124 ESS_RqShftPark_PHEV 64;
BA_ "FlexKomSID" SG_ 124 ESS_RqShftPark_PHEV 2991;
BA_ "FlexKomIsMotorola" SG_ 124 ESS_RqShftPark_PHEV 1;
BA_ "FlexKomComment" SG_ 124 ESS_RqShftPark_PHEV "ECM_A2_PHEV_PKT";
BA_ "GenSigSNA" SG_ 124 RPMOverRev_PHEV "0h";
BA_ "GenSigCycleTime" SG_ 124 RPMOverRev_PHEV 20;
BA_ "FlexKomSigStartValue" SG_ 124 RPMOverRev_PHEV "FF0000001FFF00FFh";
BA_ "FlexKomSigStartPos" SG_ 124 RPMOverRev_PHEV 7;
BA_ "FlexKomSigName" SG_ 124 RPMOverRev_PHEV "ECM_A2_PHEV_PKT";
BA_ "FlexKomSigLaenge" SG_ 124 RPMOverRev_PHEV 64;
BA_ "FlexKomSID" SG_ 124 RPMOverRev_PHEV 2991;
BA_ "FlexKomIsMotorola" SG_ 124 RPMOverRev_PHEV 1;
BA_ "FlexKomComment" SG_ 124 RPMOverRev_PHEV "ECM_A2_PHEV_PKT";
BA_ "GenSigSNA" SG_ 124 LV12PwrFreeRq_PHEV "0h";
BA_ "GenSigCycleTime" SG_ 124 LV12PwrFreeRq_PHEV 20;
BA_ "FlexKomSigStartValue" SG_ 124 LV12PwrFreeRq_PHEV "FF0000001FFF00FFh";
BA_ "FlexKomSigStartPos" SG_ 124 LV12PwrFreeRq_PHEV 7;
BA_ "FlexKomSigName" SG_ 124 LV12PwrFreeRq_PHEV "ECM_A2_PHEV_PKT";
BA_ "FlexKomSigLaenge" SG_ 124 LV12PwrFreeRq_PHEV 64;
BA_ "FlexKomSID" SG_ 124 LV12PwrFreeRq_PHEV 2991;
BA_ "FlexKomIsMotorola" SG_ 124 LV12PwrFreeRq_PHEV 1;
BA_ "FlexKomComment" SG_ 124 LV12PwrFreeRq_PHEV "ECM_A2_PHEV_PKT";
BA_ "GenSigSNA" SG_ 124 ECM_AllwEV_PHEV "0h";
BA_ "GenSigCycleTime" SG_ 124 ECM_AllwEV_PHEV 20;
BA_ "FlexKomSigStartValue" SG_ 124 ECM_AllwEV_PHEV "FF0000001FFF00FFh";
BA_ "FlexKomSigStartPos" SG_ 124 ECM_AllwEV_PHEV 7;
BA_ "FlexKomSigName" SG_ 124 ECM_AllwEV_PHEV "ECM_A2_PHEV_PKT";
BA_ "FlexKomSigLaenge" SG_ 124 ECM_AllwEV_PHEV 64;
BA_ "FlexKomSID" SG_ 124 ECM_AllwEV_PHEV 2991;
BA_ "FlexKomIsMotorola" SG_ 124 ECM_AllwEV_PHEV 1;
BA_ "FlexKomComment" SG_ 124 ECM_AllwEV_PHEV "ECM_A2_PHEV_PKT";
BA_ "GenSigSNA" SG_ 124 ECM_Comm_Fail_ePT "0h";
BA_ "GenSigCycleTime" SG_ 124 ECM_Comm_Fail_ePT 20;
BA_ "FlexKomSigStartValue" SG_ 124 ECM_Comm_Fail_ePT "FF0000001FFF00FFh";
BA_ "FlexKomSigStartPos" SG_ 124 ECM_Comm_Fail_ePT 7;
BA_ "FlexKomSigName" SG_ 124 ECM_Comm_Fail_ePT "ECM_A2_PHEV_PKT";
BA_ "FlexKomSigLaenge" SG_ 124 ECM_Comm_Fail_ePT 64;
BA_ "FlexKomSID" SG_ 124 ECM_Comm_Fail_ePT 2991;
BA_ "FlexKomIsMotorola" SG_ 124 ECM_Comm_Fail_ePT 1;
BA_ "FlexKomComment" SG_ 124 ECM_Comm_Fail_ePT "ECM_A2_PHEV_PKT";
BA_ "GenSigSNA" SG_ 124 MC_ECM_A2_PHEV "0h";
BA_ "GenSigCycleTime" SG_ 124 MC_ECM_A2_PHEV 20;
BA_ "FlexKomSigStartValue" SG_ 124 MC_ECM_A2_PHEV "FF0000001FFF00FFh";
BA_ "FlexKomSigStartPos" SG_ 124 MC_ECM_A2_PHEV 7;
BA_ "FlexKomSigName" SG_ 124 MC_ECM_A2_PHEV "ECM_A2_PHEV_PKT";
BA_ "FlexKomSigLaenge" SG_ 124 MC_ECM_A2_PHEV 64;
BA_ "FlexKomSID" SG_ 124 MC_ECM_A2_PHEV 2991;
BA_ "FlexKomIsMotorola" SG_ 124 MC_ECM_A2_PHEV 1;
BA_ "FlexKomComment" SG_ 124 MC_ECM_A2_PHEV "ECM_A2_PHEV_PKT";
BA_ "GenSigStartValue" SG_ 124 CRC_ECM_A2_PHEV 255;
BA_ "GenSigSNA" SG_ 124 CRC_ECM_A2_PHEV "FFh";
BA_ "GenSigCycleTime" SG_ 124 CRC_ECM_A2_PHEV 20;
BA_ "FlexKomSigStartValue" SG_ 124 CRC_ECM_A2_PHEV "FF0000001FFF00FFh";
BA_ "FlexKomSigStartPos" SG_ 124 CRC_ECM_A2_PHEV 7;
BA_ "FlexKomSigName" SG_ 124 CRC_ECM_A2_PHEV "ECM_A2_PHEV_PKT";
BA_ "FlexKomSigLaenge" SG_ 124 CRC_ECM_A2_PHEV 64;
BA_ "FlexKomSID" SG_ 124 CRC_ECM_A2_PHEV 2991;
BA_ "FlexKomIsMotorola" SG_ 124 CRC_ECM_A2_PHEV 1;
BA_ "FlexKomComment" SG_ 124 CRC_ECM_A2_PHEV "ECM_A2_PHEV_PKT";
BA_ "GenSigSNA" SG_ 125 KickDnSw_Psd "0h";
BA_ "GenSigCycleTime" SG_ 125 KickDnSw_Psd 20;
BA_ "FlexKomSigStartValue" SG_ 125 KickDnSw_Psd "00h";
BA_ "FlexKomSigStartPos" SG_ 125 KickDnSw_Psd 3;
BA_ "FlexKomSigName" SG_ 125 KickDnSw_Psd "KickDnSw_Psd";
BA_ "FlexKomSigLaenge" SG_ 125 KickDnSw_Psd 1;
BA_ "FlexKomSID" SG_ 125 KickDnSw_Psd 1238;
BA_ "FlexKomIsMotorola" SG_ 125 KickDnSw_Psd 1;
BA_ "FlexKomComment" SG_ 125 KickDnSw_Psd "kick-down (change-over scenario open!)";
BA_ "GenSigSNA" SG_ 125 TxAC_EMCC_rq "0h";
BA_ "GenSigCycleTime" SG_ 125 TxAC_EMCC_rq 20;
BA_ "FlexKomSigStartValue" SG_ 125 TxAC_EMCC_rq "00h";
BA_ "FlexKomSigStartPos" SG_ 125 TxAC_EMCC_rq 5;
BA_ "FlexKomSigName" SG_ 125 TxAC_EMCC_rq "TxAC_EMCC_rq";
BA_ "FlexKomSigLaenge" SG_ 125 TxAC_EMCC_rq 1;
BA_ "FlexKomSID" SG_ 125 TxAC_EMCC_rq 1240;
BA_ "FlexKomIsMotorola" SG_ 125 TxAC_EMCC_rq 1;
BA_ "FlexKomComment" SG_ 125 TxAC_EMCC_rq "Transmission  AC converter clutch slip request; [1";
BA_ "GenSigStartValue" SG_ 125 EngTrqMaxCorrFctr 255;
BA_ "GenSigSNA" SG_ 125 EngTrqMaxCorrFctr "FFh";
BA_ "GenSigCycleTime" SG_ 125 EngTrqMaxCorrFctr 20;
BA_ "FlexKomSigStartValue" SG_ 125 EngTrqMaxCorrFctr "FFh";
BA_ "FlexKomSigStartPos" SG_ 125 EngTrqMaxCorrFctr 15;
BA_ "FlexKomSigName" SG_ 125 EngTrqMaxCorrFctr "EngTrqMaxCorrFctr";
BA_ "FlexKomSigLaenge" SG_ 125 EngTrqMaxCorrFctr 8;
BA_ "FlexKomSID" SG_ 125 EngTrqMaxCorrFctr 1242;
BA_ "FlexKomIsMotorola" SG_ 125 EngTrqMaxCorrFctr 1;
BA_ "FlexKomComment" SG_ 125 EngTrqMaxCorrFctr "Factor of reduction from max. torque";
BA_ "GenSigSNA" SG_ 125 GrMin_Rq_ECM "0h";
BA_ "GenSigCycleTime" SG_ 125 GrMin_Rq_ECM 20;
BA_ "FlexKomSigStartValue" SG_ 125 GrMin_Rq_ECM "00h";
BA_ "FlexKomSigStartPos" SG_ 125 GrMin_Rq_ECM 21;
BA_ "FlexKomSigName" SG_ 125 GrMin_Rq_ECM "ECM_Gear";
BA_ "FlexKomSigLaenge" SG_ 125 GrMin_Rq_ECM 6;
BA_ "FlexKomSID" SG_ 125 GrMin_Rq_ECM 1243;
BA_ "FlexKomIsMotorola" SG_ 125 GrMin_Rq_ECM 1;
BA_ "FlexKomComment" SG_ 125 GrMin_Rq_ECM "Target gear upper and lower limit";
BA_ "GenSigSNA" SG_ 125 GrMax_Rq_ECM "0h";
BA_ "GenSigCycleTime" SG_ 125 GrMax_Rq_ECM 20;
BA_ "FlexKomSigStartValue" SG_ 125 GrMax_Rq_ECM "00h";
BA_ "FlexKomSigStartPos" SG_ 125 GrMax_Rq_ECM 21;
BA_ "FlexKomSigName" SG_ 125 GrMax_Rq_ECM "ECM_Gear";
BA_ "FlexKomSigLaenge" SG_ 125 GrMax_Rq_ECM 6;
BA_ "FlexKomSID" SG_ 125 GrMax_Rq_ECM 1243;
BA_ "FlexKomIsMotorola" SG_ 125 GrMax_Rq_ECM 1;
BA_ "FlexKomComment" SG_ 125 GrMax_Rq_ECM "Target gear upper and lower limit";
BA_ "GenSigStartValue" SG_ 125 NMOTS 65535;
BA_ "GenSigSNA" SG_ 125 NMOTS "FFFFh";
BA_ "GenSigCycleTime" SG_ 125 NMOTS 20;
BA_ "FlexKomSigStartValue" SG_ 125 NMOTS "FFFFh";
BA_ "FlexKomSigStartPos" SG_ 125 NMOTS 39;
BA_ "FlexKomSigName" SG_ 125 NMOTS "NMOTS";
BA_ "FlexKomSigLaenge" SG_ 125 NMOTS 16;
BA_ "FlexKomSID" SG_ 125 NMOTS 1248;
BA_ "FlexKomIsMotorola" SG_ 125 NMOTS 1;
BA_ "FlexKomComment" SG_ 125 NMOTS "Target idle speed";
BA_ "RID" SG_ 127 WhlPlsCnt_FL "1251";
BA_ "GenSigTimeout_IC" SG_ 127 WhlPlsCnt_FL 210;
BA_ "GenSigTimeout_CBC" SG_ 127 WhlPlsCnt_FL 210;
BA_ "GenSigSNA" SG_ 127 WhlPlsCnt_FL "FFh";
BA_ "GenSigCycleTime" SG_ 127 WhlPlsCnt_FL 20;
BA_ "FlexKomSigStartValue" SG_ 127 WhlPlsCnt_FL "00000000h";
BA_ "FlexKomSigStartPos" SG_ 127 WhlPlsCnt_FL 7;
BA_ "FlexKomSigName" SG_ 127 WhlPlsCnt_FL "ESP_WHL_PULS";
BA_ "FlexKomSigLaenge" SG_ 127 WhlPlsCnt_FL 32;
BA_ "FlexKomSID" SG_ 127 WhlPlsCnt_FL 65;
BA_ "FlexKomIsMotorola" SG_ 127 WhlPlsCnt_FL 1;
BA_ "FlexKomComment" SG_ 127 WhlPlsCnt_FL "ESP Wheel pulse counts";
BA_ "RID" SG_ 127 WhlPlsCnt_FR "1086";
BA_ "GenSigTimeout_IC" SG_ 127 WhlPlsCnt_FR 210;
BA_ "GenSigTimeout_CBC" SG_ 127 WhlPlsCnt_FR 210;
BA_ "GenSigSNA" SG_ 127 WhlPlsCnt_FR "FFh";
BA_ "GenSigCycleTime" SG_ 127 WhlPlsCnt_FR 20;
BA_ "FlexKomSigStartValue" SG_ 127 WhlPlsCnt_FR "00000000h";
BA_ "FlexKomSigStartPos" SG_ 127 WhlPlsCnt_FR 7;
BA_ "FlexKomSigName" SG_ 127 WhlPlsCnt_FR "ESP_WHL_PULS";
BA_ "FlexKomSigLaenge" SG_ 127 WhlPlsCnt_FR 32;
BA_ "FlexKomSID" SG_ 127 WhlPlsCnt_FR 65;
BA_ "FlexKomIsMotorola" SG_ 127 WhlPlsCnt_FR 1;
BA_ "FlexKomComment" SG_ 127 WhlPlsCnt_FR "ESP Wheel pulse counts";
BA_ "RID" SG_ 127 WhlPlsCnt_RL "1049";
BA_ "GenSigTimeout_IC" SG_ 127 WhlPlsCnt_RL 210;
BA_ "GenSigTimeout_CBC" SG_ 127 WhlPlsCnt_RL 210;
BA_ "GenSigSNA" SG_ 127 WhlPlsCnt_RL "FFh";
BA_ "GenSigCycleTime" SG_ 127 WhlPlsCnt_RL 20;
BA_ "FlexKomSigStartValue" SG_ 127 WhlPlsCnt_RL "00000000h";
BA_ "FlexKomSigStartPos" SG_ 127 WhlPlsCnt_RL 7;
BA_ "FlexKomSigName" SG_ 127 WhlPlsCnt_RL "ESP_WHL_PULS";
BA_ "FlexKomSigLaenge" SG_ 127 WhlPlsCnt_RL 32;
BA_ "FlexKomSID" SG_ 127 WhlPlsCnt_RL 65;
BA_ "FlexKomIsMotorola" SG_ 127 WhlPlsCnt_RL 1;
BA_ "FlexKomComment" SG_ 127 WhlPlsCnt_RL "ESP Wheel pulse counts";
BA_ "RID" SG_ 127 WhlPlsCnt_RR "1047";
BA_ "GenSigTimeout_IC" SG_ 127 WhlPlsCnt_RR 210;
BA_ "GenSigTimeout_CBC" SG_ 127 WhlPlsCnt_RR 210;
BA_ "GenSigSNA" SG_ 127 WhlPlsCnt_RR "FFh";
BA_ "GenSigCycleTime" SG_ 127 WhlPlsCnt_RR 20;
BA_ "FlexKomSigStartValue" SG_ 127 WhlPlsCnt_RR "00000000h";
BA_ "FlexKomSigStartPos" SG_ 127 WhlPlsCnt_RR 7;
BA_ "FlexKomSigName" SG_ 127 WhlPlsCnt_RR "ESP_WHL_PULS";
BA_ "FlexKomSigLaenge" SG_ 127 WhlPlsCnt_RR 32;
BA_ "FlexKomSID" SG_ 127 WhlPlsCnt_RR 65;
BA_ "FlexKomIsMotorola" SG_ 127 WhlPlsCnt_RR 1;
BA_ "FlexKomComment" SG_ 127 WhlPlsCnt_RR "ESP Wheel pulse counts";
BA_ "GenSigTimeout_DTCM" SG_ 127 CENT_DIFF_ESP_RQ 210;
BA_ "GenSigSNA" SG_ 127 CENT_DIFF_ESP_RQ "3h";
BA_ "GenSigCycleTime" SG_ 127 CENT_DIFF_ESP_RQ 20;
BA_ "FlexKomSigStartValue" SG_ 127 CENT_DIFF_ESP_RQ "00FFFFFFh";
BA_ "FlexKomSigStartPos" SG_ 127 CENT_DIFF_ESP_RQ 39;
BA_ "FlexKomSigName" SG_ 127 CENT_DIFF_ESP_RQ "ESP_DIFF_RQ";
BA_ "FlexKomSigLaenge" SG_ 127 CENT_DIFF_ESP_RQ 32;
BA_ "FlexKomSID" SG_ 127 CENT_DIFF_ESP_RQ 394;
BA_ "FlexKomIsMotorola" SG_ 127 CENT_DIFF_ESP_RQ 1;
BA_ "FlexKomComment" SG_ 127 CENT_DIFF_ESP_RQ "ESP DIFF Control Requests";
BA_ "GenSigTimeout_DTCM" SG_ 127 CENT_DIFF_TRQ_RQ 210;
BA_ "GenSigStartValue" SG_ 127 CENT_DIFF_TRQ_RQ 255;
BA_ "GenSigSNA" SG_ 127 CENT_DIFF_TRQ_RQ "FFh";
BA_ "GenSigCycleTime" SG_ 127 CENT_DIFF_TRQ_RQ 20;
BA_ "FlexKomSigStartValue" SG_ 127 CENT_DIFF_TRQ_RQ "00FFFFFFh";
BA_ "FlexKomSigStartPos" SG_ 127 CENT_DIFF_TRQ_RQ 39;
BA_ "FlexKomSigName" SG_ 127 CENT_DIFF_TRQ_RQ "ESP_DIFF_RQ";
BA_ "FlexKomSigLaenge" SG_ 127 CENT_DIFF_TRQ_RQ 32;
BA_ "FlexKomSID" SG_ 127 CENT_DIFF_TRQ_RQ 394;
BA_ "FlexKomIsMotorola" SG_ 127 CENT_DIFF_TRQ_RQ 1;
BA_ "FlexKomComment" SG_ 127 CENT_DIFF_TRQ_RQ "ESP DIFF Control Requests";
BA_ "GenSigTimeout_IC" SG_ 129 SpeedLimitSts 210;
BA_ "GenSigStartValue" SG_ 129 SpeedLimitSts 2;
BA_ "GenSigSNA" SG_ 129 SpeedLimitSts "7h";
BA_ "GenSigCycleTime" SG_ 129 SpeedLimitSts 20;
BA_ "FlexKomSigStartValue" SG_ 129 SpeedLimitSts "02h";
BA_ "FlexKomSigStartPos" SG_ 129 SpeedLimitSts 4;
BA_ "FlexKomSigName" SG_ 129 SpeedLimitSts "SpeedLimitSts";
BA_ "FlexKomSigLaenge" SG_ 129 SpeedLimitSts 3;
BA_ "FlexKomSID" SG_ 129 SpeedLimitSts 1865;
BA_ "FlexKomIsMotorola" SG_ 129 SpeedLimitSts 1;
BA_ "FlexKomComment" SG_ 129 SpeedLimitSts "Speed limiter status";
BA_ "RID" SG_ 129 CRUISE_EGD "1101";
BA_ "GenSigTimeout_TCM" SG_ 129 CRUISE_EGD 210;
BA_ "GenSigTimeout_ORC" SG_ 129 CRUISE_EGD 70;
BA_ "GenSigTimeout_IC" SG_ 129 CRUISE_EGD 210;
BA_ "GenSigTimeout_CBC" SG_ 129 CRUISE_EGD 210;
BA_ "GenSigSNA" SG_ 129 CRUISE_EGD "0h";
BA_ "GenSigCycleTime" SG_ 129 CRUISE_EGD 20;
BA_ "FlexKomSigStartValue" SG_ 129 CRUISE_EGD "00h";
BA_ "FlexKomSigStartPos" SG_ 129 CRUISE_EGD 5;
BA_ "FlexKomSigName" SG_ 129 CRUISE_EGD "CRUISE_EGD";
BA_ "FlexKomSigLaenge" SG_ 129 CRUISE_EGD 1;
BA_ "FlexKomSID" SG_ 129 CRUISE_EGD 856;
BA_ "FlexKomIsMotorola" SG_ 129 CRUISE_EGD 1;
BA_ "FlexKomComment" SG_ 129 CRUISE_EGD "Cruise system is controlling speed";
BA_ "GenSigTimeout_SCCM" SG_ 129 CRUISE_ON 210;
BA_ "GenSigTimeout_ORC" SG_ 129 CRUISE_ON 70;
BA_ "GenSigTimeout_IC" SG_ 129 CRUISE_ON 210;
BA_ "GenSigSNA" SG_ 129 CRUISE_ON "0h";
BA_ "GenSigCycleTime" SG_ 129 CRUISE_ON 20;
BA_ "FlexKomSigStartValue" SG_ 129 CRUISE_ON "00h";
BA_ "FlexKomSigStartPos" SG_ 129 CRUISE_ON 7;
BA_ "FlexKomSigName" SG_ 129 CRUISE_ON "CRUISE_ON";
BA_ "FlexKomSigLaenge" SG_ 129 CRUISE_ON 1;
BA_ "FlexKomSID" SG_ 129 CRUISE_ON 1250;
BA_ "FlexKomIsMotorola" SG_ 129 CRUISE_ON 1;
BA_ "FlexKomComment" SG_ 129 CRUISE_ON "Cruise control system 'on'";
BA_ "GenSigStartValue" SG_ 129 V_MAX_TM 255;
BA_ "GenSigSNA" SG_ 129 V_MAX_TM "FFh";
BA_ "GenSigCycleTime" SG_ 129 V_MAX_TM 20;
BA_ "FlexKomSigStartValue" SG_ 129 V_MAX_TM "FFh";
BA_ "FlexKomSigStartPos" SG_ 129 V_MAX_TM 15;
BA_ "FlexKomSigName" SG_ 129 V_MAX_TM "V_MAX_TM";
BA_ "FlexKomSigLaenge" SG_ 129 V_MAX_TM 8;
BA_ "FlexKomSID" SG_ 129 V_MAX_TM 1252;
BA_ "FlexKomIsMotorola" SG_ 129 V_MAX_TM 1;
BA_ "FlexKomComment" SG_ 129 V_MAX_TM "Max. or cruise control set speed";
BA_ "GenSigTimeout_TBM" SG_ 129 MAP_ENG 210;
BA_ "GenSigTimeout_ETM" SG_ 129 MAP_ENG 1010;
BA_ "GenSigStartValue" SG_ 129 MAP_ENG 255;
BA_ "GenSigSNA" SG_ 129 MAP_ENG "FFh";
BA_ "GenSigCycleTime" SG_ 129 MAP_ENG 20;
BA_ "FlexKomSigStartValue" SG_ 129 MAP_ENG "FF00FFFF00FFh";
BA_ "FlexKomSigStartPos" SG_ 129 MAP_ENG 23;
BA_ "FlexKomSigName" SG_ 129 MAP_ENG "Engine_1_Pkt";
BA_ "FlexKomSigLaenge" SG_ 129 MAP_ENG 48;
BA_ "FlexKomSID" SG_ 129 MAP_ENG 1352;
BA_ "FlexKomIsMotorola" SG_ 129 MAP_ENG 1;
BA_ "FlexKomComment" SG_ 129 MAP_ENG "General engine Data";
BA_ "GenSigTimeout_IC" SG_ 129 BARO_ENG 210;
BA_ "GenSigSNA" SG_ 129 BARO_ENG "FFh";
BA_ "GenSigCycleTime" SG_ 129 BARO_ENG 20;
BA_ "FlexKomSigStartValue" SG_ 129 BARO_ENG "FF00FFFF00FFh";
BA_ "FlexKomSigStartPos" SG_ 129 BARO_ENG 23;
BA_ "FlexKomSigName" SG_ 129 BARO_ENG "Engine_1_Pkt";
BA_ "FlexKomSigLaenge" SG_ 129 BARO_ENG 48;
BA_ "FlexKomSID" SG_ 129 BARO_ENG 1352;
BA_ "FlexKomIsMotorola" SG_ 129 BARO_ENG 1;
BA_ "FlexKomComment" SG_ 129 BARO_ENG "General engine Data";
BA_ "GenSigStartValue" SG_ 129 Rel_Thrt_ENG 255;
BA_ "GenSigSNA" SG_ 129 Rel_Thrt_ENG "FFh";
BA_ "GenSigCycleTime" SG_ 129 Rel_Thrt_ENG 20;
BA_ "FlexKomSigStartValue" SG_ 129 Rel_Thrt_ENG "FF00FFFF00FFh";
BA_ "FlexKomSigStartPos" SG_ 129 Rel_Thrt_ENG 23;
BA_ "FlexKomSigName" SG_ 129 Rel_Thrt_ENG "Engine_1_Pkt";
BA_ "FlexKomSigLaenge" SG_ 129 Rel_Thrt_ENG 48;
BA_ "FlexKomSID" SG_ 129 Rel_Thrt_ENG 1352;
BA_ "FlexKomIsMotorola" SG_ 129 Rel_Thrt_ENG 1;
BA_ "FlexKomComment" SG_ 129 Rel_Thrt_ENG "General engine Data";
BA_ "GenSigStartValue" SG_ 129 Rel_Pdl_ENG 255;
BA_ "GenSigSNA" SG_ 129 Rel_Pdl_ENG "FFh";
BA_ "GenSigCycleTime" SG_ 129 Rel_Pdl_ENG 20;
BA_ "FlexKomSigStartValue" SG_ 129 Rel_Pdl_ENG "FF00FFFF00FFh";
BA_ "FlexKomSigStartPos" SG_ 129 Rel_Pdl_ENG 23;
BA_ "FlexKomSigName" SG_ 129 Rel_Pdl_ENG "Engine_1_Pkt";
BA_ "FlexKomSigLaenge" SG_ 129 Rel_Pdl_ENG 48;
BA_ "FlexKomSID" SG_ 129 Rel_Pdl_ENG 1352;
BA_ "FlexKomIsMotorola" SG_ 129 Rel_Pdl_ENG 1;
BA_ "FlexKomComment" SG_ 129 Rel_Pdl_ENG "General engine Data";
BA_ "GenSigTimeout_IC" SG_ 129 ECM_WARN 210;
BA_ "GenSigSNA" SG_ 129 ECM_WARN "7h";
BA_ "GenSigCycleTime" SG_ 129 ECM_WARN 20;
BA_ "FlexKomSigStartValue" SG_ 129 ECM_WARN "FF00FFFF00FFh";
BA_ "FlexKomSigStartPos" SG_ 129 ECM_WARN 23;
BA_ "FlexKomSigName" SG_ 129 ECM_WARN "Engine_1_Pkt";
BA_ "FlexKomSigLaenge" SG_ 129 ECM_WARN 48;
BA_ "FlexKomSID" SG_ 129 ECM_WARN 1352;
BA_ "FlexKomIsMotorola" SG_ 129 ECM_WARN 1;
BA_ "FlexKomComment" SG_ 129 ECM_WARN "General engine Data";
BA_ "RID" SG_ 131 Brk_Stat "1226";
BA_ "GenSigTimeout_ORC" SG_ 131 Brk_Stat 70;
BA_ "GenSigTimeout_CBC" SG_ 131 Brk_Stat 210;
BA_ "GenSigStartValue" SG_ 131 Brk_Stat 3;
BA_ "GenSigSNA" SG_ 131 Brk_Stat "3h";
BA_ "GenSigCycleTime" SG_ 131 Brk_Stat 20;
BA_ "FlexKomSigStartValue" SG_ 131 Brk_Stat "0F3400C003FF00FFh";
BA_ "FlexKomSigStartPos" SG_ 131 Brk_Stat 7;
BA_ "FlexKomSigName" SG_ 131 Brk_Stat "ESP_BRK_STAT";
BA_ "FlexKomSigLaenge" SG_ 131 Brk_Stat 64;
BA_ "FlexKomIsMotorola" SG_ 131 Brk_Stat 1;
BA_ "FlexKomComment" SG_ 131 Brk_Stat "ESP Brake Status Information";
BA_ "RID" SG_ 131 BrkPdl_Stat "1135";
BA_ "GenSigTimeout_TCM" SG_ 131 BrkPdl_Stat 210;
BA_ "GenSigTimeout_ORC" SG_ 131 BrkPdl_Stat 70;
BA_ "GenSigTimeout_IC" SG_ 131 BrkPdl_Stat 210;
BA_ "GenSigTimeout_ETM" SG_ 131 BrkPdl_Stat 210;
BA_ "GenSigTimeout_ESM" SG_ 131 BrkPdl_Stat 210;
BA_ "GenSigTimeout_DTCM" SG_ 131 BrkPdl_Stat 210;
BA_ "GenSigTimeout_CBC" SG_ 131 BrkPdl_Stat 510;
BA_ "GenSigStartValue" SG_ 131 BrkPdl_Stat 3;
BA_ "GenSigSNA" SG_ 131 BrkPdl_Stat "3h";
BA_ "GenSigCycleTime" SG_ 131 BrkPdl_Stat 20;
BA_ "FlexKomSigStartValue" SG_ 131 BrkPdl_Stat "0F3400C003FF00FFh";
BA_ "FlexKomSigStartPos" SG_ 131 BrkPdl_Stat 7;
BA_ "FlexKomSigName" SG_ 131 BrkPdl_Stat "ESP_BRK_STAT";
BA_ "FlexKomSigLaenge" SG_ 131 BrkPdl_Stat 64;
BA_ "FlexKomIsMotorola" SG_ 131 BrkPdl_Stat 1;
BA_ "FlexKomComment" SG_ 131 BrkPdl_Stat "ESP Brake Status Information";
BA_ "RID" SG_ 131 BrkPdl_Flt "5033";
BA_ "GenSigSNA" SG_ 131 BrkPdl_Flt "0h";
BA_ "GenSigCycleTime" SG_ 131 BrkPdl_Flt 20;
BA_ "FlexKomSigStartValue" SG_ 131 BrkPdl_Flt "0F3400C003FF00FFh";
BA_ "FlexKomSigStartPos" SG_ 131 BrkPdl_Flt 7;
BA_ "FlexKomSigName" SG_ 131 BrkPdl_Flt "ESP_BRK_STAT";
BA_ "FlexKomSigLaenge" SG_ 131 BrkPdl_Flt 64;
BA_ "FlexKomIsMotorola" SG_ 131 BrkPdl_Flt 1;
BA_ "FlexKomComment" SG_ 131 BrkPdl_Flt "ESP Brake Status Information";
BA_ "GenSigTimeout_TBM" SG_ 131 BrkIntrvntn_Actv_ESP 210;
BA_ "GenSigTimeout_ORC" SG_ 131 BrkIntrvntn_Actv_ESP 70;
BA_ "GenSigTimeout_ESM" SG_ 131 BrkIntrvntn_Actv_ESP 210;
BA_ "GenSigTimeout_DTCM" SG_ 131 BrkIntrvntn_Actv_ESP 210;
BA_ "GenSigSNA" SG_ 131 BrkIntrvntn_Actv_ESP "0h";
BA_ "GenSigCycleTime" SG_ 131 BrkIntrvntn_Actv_ESP 20;
BA_ "FlexKomSigStartValue" SG_ 131 BrkIntrvntn_Actv_ESP "0F3400C003FF00FFh";
BA_ "FlexKomSigStartPos" SG_ 131 BrkIntrvntn_Actv_ESP 7;
BA_ "FlexKomSigName" SG_ 131 BrkIntrvntn_Actv_ESP "ESP_BRK_STAT";
BA_ "FlexKomSigLaenge" SG_ 131 BrkIntrvntn_Actv_ESP 64;
BA_ "FlexKomIsMotorola" SG_ 131 BrkIntrvntn_Actv_ESP 1;
BA_ "FlexKomComment" SG_ 131 BrkIntrvntn_Actv_ESP "ESP Brake Status Information";
BA_ "GenSigTimeout_TBM" SG_ 131 BrkIntrvntn_Actv_AS 210;
BA_ "GenSigTimeout_ORC" SG_ 131 BrkIntrvntn_Actv_AS 70;
BA_ "GenSigSNA" SG_ 131 BrkIntrvntn_Actv_AS "0h";
BA_ "GenSigCycleTime" SG_ 131 BrkIntrvntn_Actv_AS 20;
BA_ "FlexKomSigStartValue" SG_ 131 BrkIntrvntn_Actv_AS "0F3400C003FF00FFh";
BA_ "FlexKomSigStartPos" SG_ 131 BrkIntrvntn_Actv_AS 7;
BA_ "FlexKomSigName" SG_ 131 BrkIntrvntn_Actv_AS "ESP_BRK_STAT";
BA_ "FlexKomSigLaenge" SG_ 131 BrkIntrvntn_Actv_AS 64;
BA_ "FlexKomIsMotorola" SG_ 131 BrkIntrvntn_Actv_AS 1;
BA_ "FlexKomComment" SG_ 131 BrkIntrvntn_Actv_AS "ESP Brake Status Information";
BA_ "GenSigTimeout_ORC" SG_ 131 BrkIntrvntn_Enbl 70;
BA_ "GenSigSNA" SG_ 131 BrkIntrvntn_Enbl "0h";
BA_ "GenSigCycleTime" SG_ 131 BrkIntrvntn_Enbl 20;
BA_ "FlexKomSigStartValue" SG_ 131 BrkIntrvntn_Enbl "0F3400C003FF00FFh";
BA_ "FlexKomSigStartPos" SG_ 131 BrkIntrvntn_Enbl 7;
BA_ "FlexKomSigName" SG_ 131 BrkIntrvntn_Enbl "ESP_BRK_STAT";
BA_ "FlexKomSigLaenge" SG_ 131 BrkIntrvntn_Enbl 64;
BA_ "FlexKomIsMotorola" SG_ 131 BrkIntrvntn_Enbl 1;
BA_ "FlexKomComment" SG_ 131 BrkIntrvntn_Enbl "ESP Brake Status Information";
BA_ "GenSigTimeout_ORC" SG_ 131 EmgBrk_Actv 70;
BA_ "GenSigSNA" SG_ 131 EmgBrk_Actv "0h";
BA_ "GenSigCycleTime" SG_ 131 EmgBrk_Actv 20;
BA_ "FlexKomSigStartValue" SG_ 131 EmgBrk_Actv "0F3400C003FF00FFh";
BA_ "FlexKomSigStartPos" SG_ 131 EmgBrk_Actv 7;
BA_ "FlexKomSigName" SG_ 131 EmgBrk_Actv "ESP_BRK_STAT";
BA_ "FlexKomSigLaenge" SG_ 131 EmgBrk_Actv 64;
BA_ "FlexKomIsMotorola" SG_ 131 EmgBrk_Actv 1;
BA_ "FlexKomComment" SG_ 131 EmgBrk_Actv "ESP Brake Status Information";
BA_ "GenSigTimeout_ORC" SG_ 131 FullBrk_Actv 70;
BA_ "GenSigTimeout_IC" SG_ 131 FullBrk_Actv 210;
BA_ "GenSigTimeout_CBC" SG_ 131 FullBrk_Actv 210;
BA_ "GenSigSNA" SG_ 131 FullBrk_Actv "0h";
BA_ "GenSigCycleTime" SG_ 131 FullBrk_Actv 20;
BA_ "FlexKomSigStartValue" SG_ 131 FullBrk_Actv "0F3400C003FF00FFh";
BA_ "FlexKomSigStartPos" SG_ 131 FullBrk_Actv 7;
BA_ "FlexKomSigName" SG_ 131 FullBrk_Actv "ESP_BRK_STAT";
BA_ "FlexKomSigLaenge" SG_ 131 FullBrk_Actv 64;
BA_ "FlexKomIsMotorola" SG_ 131 FullBrk_Actv 1;
BA_ "FlexKomComment" SG_ 131 FullBrk_Actv "ESP Brake Status Information";
BA_ "GenSigTimeout_TBM" SG_ 131 ESP_Sys_Stat 210;
BA_ "GenSigTimeout_ORC" SG_ 131 ESP_Sys_Stat 70;
BA_ "GenSigTimeout_IC" SG_ 131 ESP_Sys_Stat 210;
BA_ "GenSigTimeout_DTCM" SG_ 131 ESP_Sys_Stat 210;
BA_ "GenSigStartValue" SG_ 131 ESP_Sys_Stat 1;
BA_ "GenSigSNA" SG_ 131 ESP_Sys_Stat "1h";
BA_ "GenSigCycleTime" SG_ 131 ESP_Sys_Stat 20;
BA_ "FlexKomSigStartValue" SG_ 131 ESP_Sys_Stat "0F3400C003FF00FFh";
BA_ "FlexKomSigStartPos" SG_ 131 ESP_Sys_Stat 7;
BA_ "FlexKomSigName" SG_ 131 ESP_Sys_Stat "ESP_BRK_STAT";
BA_ "FlexKomSigLaenge" SG_ 131 ESP_Sys_Stat 64;
BA_ "FlexKomIsMotorola" SG_ 131 ESP_Sys_Stat 1;
BA_ "FlexKomComment" SG_ 131 ESP_Sys_Stat "ESP Brake Status Information";
BA_ "RID" SG_ 131 SelSpdSts "1982";
BA_ "GenSigTimeout_ORC" SG_ 131 SelSpdSts 70;
BA_ "GenSigTimeout_IC" SG_ 131 SelSpdSts 210;
BA_ "GenSigTimeout_ETM" SG_ 131 SelSpdSts 210;
BA_ "GenSigTimeout_CBC" SG_ 131 SelSpdSts 210;
BA_ "GenSigStartValue" SG_ 131 SelSpdSts 3;
BA_ "GenSigSNA" SG_ 131 SelSpdSts "3h";
BA_ "GenSigCycleTime" SG_ 131 SelSpdSts 20;
BA_ "FlexKomSigStartValue" SG_ 131 SelSpdSts "0F3400C003FF00FFh";
BA_ "FlexKomSigStartPos" SG_ 131 SelSpdSts 7;
BA_ "FlexKomSigName" SG_ 131 SelSpdSts "ESP_BRK_STAT";
BA_ "FlexKomSigLaenge" SG_ 131 SelSpdSts 64;
BA_ "FlexKomIsMotorola" SG_ 131 SelSpdSts 1;
BA_ "FlexKomComment" SG_ 131 SelSpdSts "ESP Brake Status Information";
BA_ "RID" SG_ 131 ABS_BrkEvt "5034";
BA_ "GenSigTimeout_ORC" SG_ 131 ABS_BrkEvt 70;
BA_ "GenSigTimeout_ETM" SG_ 131 ABS_BrkEvt 210;
BA_ "GenSigTimeout_DTCM" SG_ 131 ABS_BrkEvt 210;
BA_ "GenSigSNA" SG_ 131 ABS_BrkEvt "0h";
BA_ "GenSigCycleTime" SG_ 131 ABS_BrkEvt 20;
BA_ "FlexKomSigStartValue" SG_ 131 ABS_BrkEvt "0F3400C003FF00FFh";
BA_ "FlexKomSigStartPos" SG_ 131 ABS_BrkEvt 7;
BA_ "FlexKomSigName" SG_ 131 ABS_BrkEvt "ESP_BRK_STAT";
BA_ "FlexKomSigLaenge" SG_ 131 ABS_BrkEvt 64;
BA_ "FlexKomIsMotorola" SG_ 131 ABS_BrkEvt 1;
BA_ "FlexKomComment" SG_ 131 ABS_BrkEvt "ESP Brake Status Information";
BA_ "GenSigTimeout_ORC" SG_ 131 DTR_CC_Engaged 70;
BA_ "GenSigSNA" SG_ 131 DTR_CC_Engaged "0h";
BA_ "GenSigCycleTime" SG_ 131 DTR_CC_Engaged 20;
BA_ "FlexKomSigStartValue" SG_ 131 DTR_CC_Engaged "0F3400C003FF00FFh";
BA_ "FlexKomSigStartPos" SG_ 131 DTR_CC_Engaged 7;
BA_ "FlexKomSigName" SG_ 131 DTR_CC_Engaged "ESP_BRK_STAT";
BA_ "FlexKomSigLaenge" SG_ 131 DTR_CC_Engaged 64;
BA_ "FlexKomIsMotorola" SG_ 131 DTR_CC_Engaged 1;
BA_ "FlexKomComment" SG_ 131 DTR_CC_Engaged "ESP Brake Status Information";
BA_ "GenSigTimeout_TCM" SG_ 131 GrMin_Rq_ESC 210;
BA_ "GenSigSNA" SG_ 131 GrMin_Rq_ESC "0h";
BA_ "GenSigCycleTime" SG_ 131 GrMin_Rq_ESC 20;
BA_ "FlexKomSigStartValue" SG_ 131 GrMin_Rq_ESC "0F3400C003FF00FFh";
BA_ "FlexKomSigStartPos" SG_ 131 GrMin_Rq_ESC 7;
BA_ "FlexKomSigName" SG_ 131 GrMin_Rq_ESC "ESP_BRK_STAT";
BA_ "FlexKomSigLaenge" SG_ 131 GrMin_Rq_ESC 64;
BA_ "FlexKomIsMotorola" SG_ 131 GrMin_Rq_ESC 1;
BA_ "FlexKomComment" SG_ 131 GrMin_Rq_ESC "ESP Brake Status Information";
BA_ "GenSigTimeout_TCM" SG_ 131 GrMax_Rq_ESC 210;
BA_ "GenSigSNA" SG_ 131 GrMax_Rq_ESC "0h";
BA_ "GenSigCycleTime" SG_ 131 GrMax_Rq_ESC 20;
BA_ "FlexKomSigStartValue" SG_ 131 GrMax_Rq_ESC "0F3400C003FF00FFh";
BA_ "FlexKomSigStartPos" SG_ 131 GrMax_Rq_ESC 7;
BA_ "FlexKomSigName" SG_ 131 GrMax_Rq_ESC "ESP_BRK_STAT";
BA_ "FlexKomSigLaenge" SG_ 131 GrMax_Rq_ESC 64;
BA_ "FlexKomIsMotorola" SG_ 131 GrMax_Rq_ESC 1;
BA_ "FlexKomComment" SG_ 131 GrMax_Rq_ESC "ESP Brake Status Information";
BA_ "GenSigTimeout_ORC" SG_ 131 GrMinMax_Rq_DTR 70;
BA_ "GenSigSNA" SG_ 131 GrMinMax_Rq_DTR "0h";
BA_ "GenSigCycleTime" SG_ 131 GrMinMax_Rq_DTR 20;
BA_ "FlexKomSigStartValue" SG_ 131 GrMinMax_Rq_DTR "0F3400C003FF00FFh";
BA_ "FlexKomSigStartPos" SG_ 131 GrMinMax_Rq_DTR 7;
BA_ "FlexKomSigName" SG_ 131 GrMinMax_Rq_DTR "ESP_BRK_STAT";
BA_ "FlexKomSigLaenge" SG_ 131 GrMinMax_Rq_DTR 64;
BA_ "FlexKomIsMotorola" SG_ 131 GrMinMax_Rq_DTR 1;
BA_ "FlexKomComment" SG_ 131 GrMinMax_Rq_DTR "ESP Brake Status Information";
BA_ "GenSigSNA" SG_ 131 DTR_CC_Enabled "0h";
BA_ "GenSigCycleTime" SG_ 131 DTR_CC_Enabled 20;
BA_ "FlexKomSigStartValue" SG_ 131 DTR_CC_Enabled "0F3400C003FF00FFh";
BA_ "FlexKomSigStartPos" SG_ 131 DTR_CC_Enabled 7;
BA_ "FlexKomSigName" SG_ 131 DTR_CC_Enabled "ESP_BRK_STAT";
BA_ "FlexKomSigLaenge" SG_ 131 DTR_CC_Enabled 64;
BA_ "FlexKomIsMotorola" SG_ 131 DTR_CC_Enabled 1;
BA_ "FlexKomComment" SG_ 131 DTR_CC_Enabled "ESP Brake Status Information";
BA_ "GenSigSNA" SG_ 131 Brk_Thermdl "0h";
BA_ "GenSigCycleTime" SG_ 131 Brk_Thermdl 20;
BA_ "FlexKomSigStartValue" SG_ 131 Brk_Thermdl "0F3400C003FF00FFh";
BA_ "FlexKomSigStartPos" SG_ 131 Brk_Thermdl 7;
BA_ "FlexKomSigName" SG_ 131 Brk_Thermdl "ESP_BRK_STAT";
BA_ "FlexKomSigLaenge" SG_ 131 Brk_Thermdl 64;
BA_ "FlexKomIsMotorola" SG_ 131 Brk_Thermdl 1;
BA_ "FlexKomComment" SG_ 131 Brk_Thermdl "ESP Brake Status Information";
BA_ "GenSigSNA" SG_ 131 ShftChrDsp_Rq_ESC "Fh";
BA_ "GenSigCycleTime" SG_ 131 ShftChrDsp_Rq_ESC 20;
BA_ "FlexKomSigStartValue" SG_ 131 ShftChrDsp_Rq_ESC "0F3400C003FF00FFh";
BA_ "FlexKomSigStartPos" SG_ 131 ShftChrDsp_Rq_ESC 7;
BA_ "FlexKomSigName" SG_ 131 ShftChrDsp_Rq_ESC "ESP_BRK_STAT";
BA_ "FlexKomSigLaenge" SG_ 131 ShftChrDsp_Rq_ESC 64;
BA_ "FlexKomIsMotorola" SG_ 131 ShftChrDsp_Rq_ESC 1;
BA_ "FlexKomComment" SG_ 131 ShftChrDsp_Rq_ESC "ESP Brake Status Information";
BA_ "GenSigTimeout_DTCM" SG_ 131 RollTestMd_Actv 210;
BA_ "GenSigStartValue" SG_ 131 RollTestMd_Actv 3;
BA_ "GenSigSNA" SG_ 131 RollTestMd_Actv "3h";
BA_ "GenSigCycleTime" SG_ 131 RollTestMd_Actv 20;
BA_ "FlexKomSigStartValue" SG_ 131 RollTestMd_Actv "0F3400C003FF00FFh";
BA_ "FlexKomSigStartPos" SG_ 131 RollTestMd_Actv 7;
BA_ "FlexKomSigName" SG_ 131 RollTestMd_Actv "ESP_BRK_STAT";
BA_ "FlexKomSigLaenge" SG_ 131 RollTestMd_Actv 64;
BA_ "FlexKomIsMotorola" SG_ 131 RollTestMd_Actv 1;
BA_ "FlexKomComment" SG_ 131 RollTestMd_Actv "ESP Brake Status Information";
BA_ "GenSigTimeout_ORC" SG_ 131 REF_VEH_SPEED 70;
BA_ "GenSigTimeout_IC" SG_ 131 REF_VEH_SPEED 210;
BA_ "GenSigStartValue" SG_ 131 REF_VEH_SPEED 1023;
BA_ "GenSigSNA" SG_ 131 REF_VEH_SPEED "3FFh";
BA_ "GenSigCycleTime" SG_ 131 REF_VEH_SPEED 20;
BA_ "FlexKomSigStartValue" SG_ 131 REF_VEH_SPEED "0F3400C003FF00FFh";
BA_ "FlexKomSigStartPos" SG_ 131 REF_VEH_SPEED 7;
BA_ "FlexKomSigName" SG_ 131 REF_VEH_SPEED "ESP_BRK_STAT";
BA_ "FlexKomSigLaenge" SG_ 131 REF_VEH_SPEED 64;
BA_ "FlexKomIsMotorola" SG_ 131 REF_VEH_SPEED 1;
BA_ "FlexKomComment" SG_ 131 REF_VEH_SPEED "ESP Brake Status Information";
BA_ "GenSigSNA" SG_ 131 SPCR_AS_Off_Rq "0h";
BA_ "GenSigCycleTime" SG_ 131 SPCR_AS_Off_Rq 20;
BA_ "FlexKomSigStartValue" SG_ 131 SPCR_AS_Off_Rq "0F3400C003FF00FFh";
BA_ "FlexKomSigStartPos" SG_ 131 SPCR_AS_Off_Rq 7;
BA_ "FlexKomSigName" SG_ 131 SPCR_AS_Off_Rq "ESP_BRK_STAT";
BA_ "FlexKomSigLaenge" SG_ 131 SPCR_AS_Off_Rq 64;
BA_ "FlexKomIsMotorola" SG_ 131 SPCR_AS_Off_Rq 1;
BA_ "FlexKomComment" SG_ 131 SPCR_AS_Off_Rq "ESP Brake Status Information";
BA_ "GenSigTimeout_ORC" SG_ 131 MC_Brk_Stat 70;
BA_ "GenSigTimeout_IC" SG_ 131 MC_Brk_Stat 210;
BA_ "GenSigTimeout_DTCM" SG_ 131 MC_Brk_Stat 210;
BA_ "GenSigSNA" SG_ 131 MC_Brk_Stat "0h";
BA_ "GenSigCycleTime" SG_ 131 MC_Brk_Stat 20;
BA_ "FlexKomSigStartValue" SG_ 131 MC_Brk_Stat "0F3400C003FF00FFh";
BA_ "FlexKomSigStartPos" SG_ 131 MC_Brk_Stat 7;
BA_ "FlexKomSigName" SG_ 131 MC_Brk_Stat "ESP_BRK_STAT";
BA_ "FlexKomSigLaenge" SG_ 131 MC_Brk_Stat 64;
BA_ "FlexKomIsMotorola" SG_ 131 MC_Brk_Stat 1;
BA_ "FlexKomComment" SG_ 131 MC_Brk_Stat "ESP Brake Status Information";
BA_ "GenSigTimeout_ORC" SG_ 131 CRC_Brk_Stat 70;
BA_ "GenSigTimeout_IC" SG_ 131 CRC_Brk_Stat 210;
BA_ "GenSigTimeout_DTCM" SG_ 131 CRC_Brk_Stat 210;
BA_ "GenSigStartValue" SG_ 131 CRC_Brk_Stat 255;
BA_ "GenSigSNA" SG_ 131 CRC_Brk_Stat "FFh";
BA_ "GenSigCycleTime" SG_ 131 CRC_Brk_Stat 20;
BA_ "FlexKomSigStartValue" SG_ 131 CRC_Brk_Stat "0F3400C003FF00FFh";
BA_ "FlexKomSigStartPos" SG_ 131 CRC_Brk_Stat 7;
BA_ "FlexKomSigName" SG_ 131 CRC_Brk_Stat "ESP_BRK_STAT";
BA_ "FlexKomSigLaenge" SG_ 131 CRC_Brk_Stat 64;
BA_ "FlexKomIsMotorola" SG_ 131 CRC_Brk_Stat 1;
BA_ "FlexKomComment" SG_ 131 CRC_Brk_Stat "ESP Brake Status Information";
BA_ "GenSigSNA" SG_ 131 HillHolderActive "0h";
BA_ "GenSigCycleTime" SG_ 131 HillHolderActive 20;
BA_ "FlexKomSigStartValue" SG_ 131 HillHolderActive "0F3400C003FF00FFh";
BA_ "FlexKomSigStartPos" SG_ 131 HillHolderActive 7;
BA_ "FlexKomSigName" SG_ 131 HillHolderActive "ESP_BRK_STAT";
BA_ "FlexKomSigLaenge" SG_ 131 HillHolderActive 64;
BA_ "FlexKomIsMotorola" SG_ 131 HillHolderActive 1;
BA_ "FlexKomComment" SG_ 131 HillHolderActive "ESP Brake Status Information";
BA_ "GenSigSNA" SG_ 133 K_STO_B "0h";
BA_ "GenSigCycleTime" SG_ 133 K_STO_B 20;
BA_ "FlexKomSigStartValue" SG_ 133 K_STO_B "000000h";
BA_ "FlexKomSigStartPos" SG_ 133 K_STO_B 7;
BA_ "FlexKomSigName" SG_ 133 K_STO_B "K_B";
BA_ "FlexKomSigLaenge" SG_ 133 K_STO_B 24;
BA_ "FlexKomSID" SG_ 133 K_STO_B 1129;
BA_ "FlexKomIsMotorola" SG_ 133 K_STO_B 1;
BA_ "FlexKomComment" SG_ 133 K_STO_B "Torque converter lock-up status";
BA_ "GenSigSNA" SG_ 133 GearSwitchActiveSts "0h";
BA_ "GenSigCycleTime" SG_ 133 GearSwitchActiveSts 20;
BA_ "FlexKomSigStartValue" SG_ 133 GearSwitchActiveSts "00h";
BA_ "FlexKomSigStartPos" SG_ 133 GearSwitchActiveSts 2;
BA_ "FlexKomSigName" SG_ 133 GearSwitchActiveSts "GearSwitchActiveSts";
BA_ "FlexKomSigLaenge" SG_ 133 GearSwitchActiveSts 1;
BA_ "FlexKomSID" SG_ 133 GearSwitchActiveSts 1528;
BA_ "FlexKomIsMotorola" SG_ 133 GearSwitchActiveSts 1;
BA_ "FlexKomComment" SG_ 133 GearSwitchActiveSts "Transmission shift in progress";
BA_ "GenSigSNA" SG_ 133 EngSt_Enbl_Rq_TCM "0h";
BA_ "GenSigCycleTime" SG_ 133 EngSt_Enbl_Rq_TCM 20;
BA_ "FlexKomSigStartValue" SG_ 133 EngSt_Enbl_Rq_TCM "00h";
BA_ "FlexKomSigStartPos" SG_ 133 EngSt_Enbl_Rq_TCM 5;
BA_ "FlexKomSigName" SG_ 133 EngSt_Enbl_Rq_TCM "EngSt_Enbl_Rq_TCM";
BA_ "FlexKomSigLaenge" SG_ 133 EngSt_Enbl_Rq_TCM 1;
BA_ "FlexKomSID" SG_ 133 EngSt_Enbl_Rq_TCM 1125;
BA_ "FlexKomIsMotorola" SG_ 133 EngSt_Enbl_Rq_TCM 1;
BA_ "FlexKomComment" SG_ 133 EngSt_Enbl_Rq_TCM "Enable engine start request";
BA_ "RID" SG_ 133 Gr "1069";
BA_ "GenSigTimeout_RF_HUB" SG_ 133 Gr 210;
BA_ "GenSigTimeout_ORC" SG_ 133 Gr 70;
BA_ "GenSigTimeout_IC" SG_ 133 Gr 210;
BA_ "GenSigTimeout_ESM" SG_ 133 Gr 210;
BA_ "GenSigTimeout_DTCM" SG_ 133 Gr 210;
BA_ "GenSigTimeout_CBC" SG_ 133 Gr 210;
BA_ "GenSigStartValue" SG_ 133 Gr 15;
BA_ "GenSigSNA" SG_ 133 Gr "Fh";
BA_ "GenSigCycleTime" SG_ 133 Gr 20;
BA_ "FlexKomSigStartValue" SG_ 133 Gr "FF00h";
BA_ "FlexKomSigStartPos" SG_ 133 Gr 15;
BA_ "FlexKomSigName" SG_ 133 Gr "Gear_Pkt";
BA_ "FlexKomSigLaenge" SG_ 133 Gr 16;
BA_ "FlexKomSID" SG_ 133 Gr 1128;
BA_ "FlexKomIsMotorola" SG_ 133 Gr 1;
BA_ "FlexKomComment" SG_ 133 Gr "Current Gear/Target Gear";
BA_ "RID" SG_ 133 Gr_Target "1814";
BA_ "GenSigTimeout_DTCM" SG_ 133 Gr_Target 210;
BA_ "GenSigTimeout_CBC" SG_ 133 Gr_Target 210;
BA_ "GenSigStartValue" SG_ 133 Gr_Target 15;
BA_ "GenSigSNA" SG_ 133 Gr_Target "Fh";
BA_ "GenSigCycleTime" SG_ 133 Gr_Target 20;
BA_ "FlexKomSigStartValue" SG_ 133 Gr_Target "FF00h";
BA_ "FlexKomSigStartPos" SG_ 133 Gr_Target 15;
BA_ "FlexKomSigName" SG_ 133 Gr_Target "Gear_Pkt";
BA_ "FlexKomSigLaenge" SG_ 133 Gr_Target 16;
BA_ "FlexKomSID" SG_ 133 Gr_Target 1128;
BA_ "FlexKomIsMotorola" SG_ 133 Gr_Target 1;
BA_ "FlexKomComment" SG_ 133 Gr_Target "Current Gear/Target Gear";
BA_ "GenSigSNA" SG_ 133 K_G_B "0h";
BA_ "GenSigCycleTime" SG_ 133 K_G_B 20;
BA_ "FlexKomSigStartValue" SG_ 133 K_G_B "000000h";
BA_ "FlexKomSigStartPos" SG_ 133 K_G_B 7;
BA_ "FlexKomSigName" SG_ 133 K_G_B "K_B";
BA_ "FlexKomSigLaenge" SG_ 133 K_G_B 24;
BA_ "FlexKomSID" SG_ 133 K_G_B 1129;
BA_ "FlexKomIsMotorola" SG_ 133 K_G_B 1;
BA_ "FlexKomComment" SG_ 133 K_G_B "Torque converter lock-up status";
BA_ "GenSigSNA" SG_ 133 K_O_B "0h";
BA_ "GenSigCycleTime" SG_ 133 K_O_B 20;
BA_ "FlexKomSigStartValue" SG_ 133 K_O_B "000000h";
BA_ "FlexKomSigStartPos" SG_ 133 K_O_B 7;
BA_ "FlexKomSigName" SG_ 133 K_O_B "K_B";
BA_ "FlexKomSigLaenge" SG_ 133 K_O_B 24;
BA_ "FlexKomSID" SG_ 133 K_O_B 1129;
BA_ "FlexKomIsMotorola" SG_ 133 K_O_B 1;
BA_ "FlexKomComment" SG_ 133 K_O_B "Torque converter lock-up status";
BA_ "GenSigSNA" SG_ 133 K_S_B "0h";
BA_ "GenSigCycleTime" SG_ 133 K_S_B 20;
BA_ "FlexKomSigStartValue" SG_ 133 K_S_B "000000h";
BA_ "FlexKomSigStartPos" SG_ 133 K_S_B 7;
BA_ "FlexKomSigName" SG_ 133 K_S_B "K_B";
BA_ "FlexKomSigLaenge" SG_ 133 K_S_B 24;
BA_ "FlexKomSID" SG_ 133 K_S_B 1129;
BA_ "FlexKomIsMotorola" SG_ 133 K_S_B 1;
BA_ "FlexKomComment" SG_ 133 K_S_B "Torque converter lock-up status";
BA_ "GenSigSNA" SG_ 133 Trns_EMCC_Achvd "0h";
BA_ "GenSigCycleTime" SG_ 133 Trns_EMCC_Achvd 20;
BA_ "FlexKomSigStartValue" SG_ 133 Trns_EMCC_Achvd "00h";
BA_ "FlexKomSigStartPos" SG_ 133 Trns_EMCC_Achvd 20;
BA_ "FlexKomSigName" SG_ 133 Trns_EMCC_Achvd "Trns_EMCC_Achvd";
BA_ "FlexKomSigLaenge" SG_ 133 Trns_EMCC_Achvd 1;
BA_ "FlexKomSID" SG_ 133 Trns_EMCC_Achvd 1130;
BA_ "FlexKomIsMotorola" SG_ 133 Trns_EMCC_Achvd 1;
BA_ "FlexKomComment" SG_ 133 Trns_EMCC_Achvd "Trans A/C Converter Clutch Slipping; [1] = True";
BA_ "GenSigStartValue" SG_ 133 OUTPUT_SPEED 65535;
BA_ "GenSigSNA" SG_ 133 OUTPUT_SPEED "FFFFh";
BA_ "GenSigCycleTime" SG_ 133 OUTPUT_SPEED 20;
BA_ "FlexKomSigStartValue" SG_ 133 OUTPUT_SPEED "FFFF000000h";
BA_ "FlexKomSigStartPos" SG_ 133 OUTPUT_SPEED 31;
BA_ "FlexKomSigName" SG_ 133 OUTPUT_SPEED "OutputSpdPkt";
BA_ "FlexKomSigLaenge" SG_ 133 OUTPUT_SPEED 40;
BA_ "FlexKomSID" SG_ 133 OUTPUT_SPEED 1605;
BA_ "FlexKomIsMotorola" SG_ 133 OUTPUT_SPEED 1;
BA_ "FlexKomComment" SG_ 133 OUTPUT_SPEED "Output shaft speed packet";
BA_ "GenSigStartValue" SG_ 133 N_Turb 65535;
BA_ "GenSigSNA" SG_ 133 N_Turb "FFFFh";
BA_ "GenSigCycleTime" SG_ 133 N_Turb 20;
BA_ "FlexKomSigStartValue" SG_ 133 N_Turb "FFFFh";
BA_ "FlexKomSigStartPos" SG_ 133 N_Turb 47;
BA_ "FlexKomSigName" SG_ 133 N_Turb "N_Turb";
BA_ "FlexKomSigLaenge" SG_ 133 N_Turb 16;
BA_ "FlexKomSID" SG_ 133 N_Turb 1133;
BA_ "FlexKomIsMotorola" SG_ 133 N_Turb 1;
BA_ "FlexKomComment" SG_ 133 N_Turb "Unfiltered turbine speed (n_t_v)";
BA_ "GenSigSNA" SG_ 133 OutputSpdPolarity "3h";
BA_ "GenSigCycleTime" SG_ 133 OutputSpdPolarity 20;
BA_ "FlexKomSigStartValue" SG_ 133 OutputSpdPolarity "FFFF000000h";
BA_ "FlexKomSigStartPos" SG_ 133 OutputSpdPolarity 31;
BA_ "FlexKomSigName" SG_ 133 OutputSpdPolarity "OutputSpdPkt";
BA_ "FlexKomSigLaenge" SG_ 133 OutputSpdPolarity 40;
BA_ "FlexKomSID" SG_ 133 OutputSpdPolarity 1605;
BA_ "FlexKomIsMotorola" SG_ 133 OutputSpdPolarity 1;
BA_ "FlexKomComment" SG_ 133 OutputSpdPolarity "Output shaft speed packet";
BA_ "GenSigSNA" SG_ 133 TRNS_SPD_MC "0h";
BA_ "GenSigCycleTime" SG_ 133 TRNS_SPD_MC 20;
BA_ "FlexKomSigStartValue" SG_ 133 TRNS_SPD_MC "00h";
BA_ "FlexKomSigStartPos" SG_ 133 TRNS_SPD_MC 61;
BA_ "FlexKomSigName" SG_ 133 TRNS_SPD_MC "TRNS_SPD_MC";
BA_ "FlexKomSigLaenge" SG_ 133 TRNS_SPD_MC 4;
BA_ "FlexKomSID" SG_ 133 TRNS_SPD_MC 2607;
BA_ "FlexKomIsMotorola" SG_ 133 TRNS_SPD_MC 1;
BA_ "FlexKomComment" SG_ 133 TRNS_SPD_MC "TRNS_SPD message counter";
BA_ "RID" SG_ 133 TCM_ManMd "1696";
BA_ "GenSigTimeout_IC" SG_ 133 TCM_ManMd 210;
BA_ "GenSigSNA" SG_ 133 TCM_ManMd "0h";
BA_ "GenSigCycleTime" SG_ 133 TCM_ManMd 20;
BA_ "FlexKomSigStartValue" SG_ 133 TCM_ManMd "00h";
BA_ "FlexKomSigStartPos" SG_ 133 TCM_ManMd 63;
BA_ "FlexKomSigName" SG_ 133 TCM_ManMd "ManualMdPkt";
BA_ "FlexKomSigLaenge" SG_ 133 TCM_ManMd 2;
BA_ "FlexKomSID" SG_ 133 TCM_ManMd 1762;
BA_ "FlexKomIsMotorola" SG_ 133 TCM_ManMd 1;
BA_ "FlexKomComment" SG_ 133 TCM_ManMd "Manual mode packet";
BA_ "GenSigTimeout_TBM" SG_ 135 BrkPrss_TMC 210;
BA_ "GenSigTimeout_ORC" SG_ 135 BrkPrss_TMC 70;
BA_ "GenSigTimeout_IC" SG_ 135 BrkPrss_TMC 210;
BA_ "GenSigTimeout_ETM" SG_ 135 BrkPrss_TMC 210;
BA_ "GenSigTimeout_DTCM" SG_ 135 BrkPrss_TMC 210;
BA_ "GenSigSNA" SG_ 135 BrkPrss_TMC "7FFh";
BA_ "GenSigCycleTime" SG_ 135 BrkPrss_TMC 20;
BA_ "FlexKomSigStartValue" SG_ 135 BrkPrss_TMC "7000FFFF00FF00FFh";
BA_ "FlexKomSigStartPos" SG_ 135 BrkPrss_TMC 7;
BA_ "FlexKomSigName" SG_ 135 BrkPrss_TMC "ESC_data";
BA_ "FlexKomSigLaenge" SG_ 135 BrkPrss_TMC 64;
BA_ "FlexKomSID" SG_ 135 BrkPrss_TMC 1416;
BA_ "FlexKomIsMotorola" SG_ 135 BrkPrss_TMC 1;
BA_ "FlexKomComment" SG_ 135 BrkPrss_TMC "ESC data";
BA_ "GenSigTimeout_TBM" SG_ 135 HSA_BrkPrss 210;
BA_ "GenSigTimeout_ORC" SG_ 135 HSA_BrkPrss 70;
BA_ "GenSigTimeout_ETM" SG_ 135 HSA_BrkPrss 210;
BA_ "GenSigSNA" SG_ 135 HSA_BrkPrss "3Fh";
BA_ "GenSigCycleTime" SG_ 135 HSA_BrkPrss 20;
BA_ "FlexKomSigStartValue" SG_ 135 HSA_BrkPrss "7000FFFF00FF00FFh";
BA_ "FlexKomSigStartPos" SG_ 135 HSA_BrkPrss 7;
BA_ "FlexKomSigName" SG_ 135 HSA_BrkPrss "ESC_data";
BA_ "FlexKomSigLaenge" SG_ 135 HSA_BrkPrss 64;
BA_ "FlexKomSID" SG_ 135 HSA_BrkPrss 1416;
BA_ "FlexKomIsMotorola" SG_ 135 HSA_BrkPrss 1;
BA_ "FlexKomComment" SG_ 135 HSA_BrkPrss "ESC data";
BA_ "GenSigStartValue" SG_ 135 BrkBstrVac_OBD 255;
BA_ "GenSigSNA" SG_ 135 BrkBstrVac_OBD "FFh";
BA_ "GenSigCycleTime" SG_ 135 BrkBstrVac_OBD 20;
BA_ "FlexKomSigStartValue" SG_ 135 BrkBstrVac_OBD "7000FFFF00FF00FFh";
BA_ "FlexKomSigStartPos" SG_ 135 BrkBstrVac_OBD 7;
BA_ "FlexKomSigName" SG_ 135 BrkBstrVac_OBD "ESC_data";
BA_ "FlexKomSigLaenge" SG_ 135 BrkBstrVac_OBD 64;
BA_ "FlexKomSID" SG_ 135 BrkBstrVac_OBD 1416;
BA_ "FlexKomIsMotorola" SG_ 135 BrkBstrVac_OBD 1;
BA_ "FlexKomComment" SG_ 135 BrkBstrVac_OBD "ESC data";
BA_ "GenSigTimeout_ORC" SG_ 135 MC_ESP_A3 70;
BA_ "GenSigSNA" SG_ 135 MC_ESP_A3 "0h";
BA_ "GenSigCycleTime" SG_ 135 MC_ESP_A3 20;
BA_ "FlexKomSigStartValue" SG_ 135 MC_ESP_A3 "7000FFFF00FF00FFh";
BA_ "FlexKomSigStartPos" SG_ 135 MC_ESP_A3 7;
BA_ "FlexKomSigName" SG_ 135 MC_ESP_A3 "ESC_data";
BA_ "FlexKomSigLaenge" SG_ 135 MC_ESP_A3 64;
BA_ "FlexKomSID" SG_ 135 MC_ESP_A3 1416;
BA_ "FlexKomIsMotorola" SG_ 135 MC_ESP_A3 1;
BA_ "FlexKomComment" SG_ 135 MC_ESP_A3 "ESC data";
BA_ "GenSigTimeout_ORC" SG_ 135 CRC_ESP_A3 70;
BA_ "GenSigStartValue" SG_ 135 CRC_ESP_A3 255;
BA_ "GenSigSNA" SG_ 135 CRC_ESP_A3 "FFh";
BA_ "GenSigCycleTime" SG_ 135 CRC_ESP_A3 20;
BA_ "FlexKomSigStartValue" SG_ 135 CRC_ESP_A3 "7000FFFF00FF00FFh";
BA_ "FlexKomSigStartPos" SG_ 135 CRC_ESP_A3 7;
BA_ "FlexKomSigName" SG_ 135 CRC_ESP_A3 "ESC_data";
BA_ "FlexKomSigLaenge" SG_ 135 CRC_ESP_A3 64;
BA_ "FlexKomSID" SG_ 135 CRC_ESP_A3 1416;
BA_ "FlexKomIsMotorola" SG_ 135 CRC_ESP_A3 1;
BA_ "FlexKomComment" SG_ 135 CRC_ESP_A3 "ESC data";
BA_ "RID" SG_ 137 VehYawRate_Raw "1058 1289 1711";
BA_ "GenSigTimeout_TBM" SG_ 137 VehYawRate_Raw 210;
BA_ "GenSigTimeout_ORC" SG_ 137 VehYawRate_Raw 70;
BA_ "GenSigTimeout_IC" SG_ 137 VehYawRate_Raw 210;
BA_ "GenSigTimeout_DTCM" SG_ 137 VehYawRate_Raw 210;
BA_ "GenSigTimeout_CBC" SG_ 137 VehYawRate_Raw 210;
BA_ "GenSigStartValue" SG_ 137 VehYawRate_Raw 65535;
BA_ "GenSigSNA" SG_ 137 VehYawRate_Raw "FFFFh";
BA_ "GenSigCycleTime" SG_ 137 VehYawRate_Raw 20;
BA_ "FlexKomSigStartValue" SG_ 137 VehYawRate_Raw "FFFFh";
BA_ "FlexKomSigStartPos" SG_ 137 VehYawRate_Raw 7;
BA_ "FlexKomSigName" SG_ 137 VehYawRate_Raw "VehYawRate_Raw";
BA_ "FlexKomSigLaenge" SG_ 137 VehYawRate_Raw 16;
BA_ "FlexKomSID" SG_ 137 VehYawRate_Raw 1262;
BA_ "FlexKomIsMotorola" SG_ 137 VehYawRate_Raw 1;
BA_ "FlexKomComment" SG_ 137 VehYawRate_Raw "Vehicle yaw rate unfiltered/unadjusted (+ means le";
BA_ "RID" SG_ 137 VehYawRate_Offset "1299 1710 5037";
BA_ "GenSigTimeout_ORC" SG_ 137 VehYawRate_Offset 70;
BA_ "GenSigTimeout_IC" SG_ 137 VehYawRate_Offset 210;
BA_ "GenSigTimeout_ETM" SG_ 137 VehYawRate_Offset 210;
BA_ "GenSigTimeout_CBC" SG_ 137 VehYawRate_Offset 210;
BA_ "GenSigStartValue" SG_ 137 VehYawRate_Offset 255;
BA_ "GenSigSNA" SG_ 137 VehYawRate_Offset "FFh";
BA_ "GenSigCycleTime" SG_ 137 VehYawRate_Offset 20;
BA_ "FlexKomSigStartValue" SG_ 137 VehYawRate_Offset "FFh";
BA_ "FlexKomSigStartPos" SG_ 137 VehYawRate_Offset 23;
BA_ "FlexKomSigName" SG_ 137 VehYawRate_Offset "VehYawRate_Offset";
BA_ "FlexKomSigLaenge" SG_ 137 VehYawRate_Offset 8;
BA_ "FlexKomSID" SG_ 137 VehYawRate_Offset 1263;
BA_ "FlexKomIsMotorola" SG_ 137 VehYawRate_Offset 1;
BA_ "FlexKomComment" SG_ 137 VehYawRate_Offset "Offset of vehicle yaw rate unfiltered/unadjusted (";
BA_ "GenSigTimeout_TBM" SG_ 137 VehAccel_X_Offset 210;
BA_ "GenSigTimeout_ORC" SG_ 137 VehAccel_X_Offset 70;
BA_ "GenSigTimeout_IC" SG_ 137 VehAccel_X_Offset 210;
BA_ "GenSigTimeout_ETM" SG_ 137 VehAccel_X_Offset 210;
BA_ "GenSigStartValue" SG_ 137 VehAccel_X_Offset 255;
BA_ "GenSigSNA" SG_ 137 VehAccel_X_Offset "FFh";
BA_ "GenSigCycleTime" SG_ 137 VehAccel_X_Offset 20;
BA_ "FlexKomSigStartValue" SG_ 137 VehAccel_X_Offset "FFh";
BA_ "FlexKomSigStartPos" SG_ 137 VehAccel_X_Offset 31;
BA_ "FlexKomSigName" SG_ 137 VehAccel_X_Offset "VehAccel_X_Offset";
BA_ "FlexKomSigLaenge" SG_ 137 VehAccel_X_Offset 8;
BA_ "FlexKomSID" SG_ 137 VehAccel_X_Offset 1264;
BA_ "FlexKomIsMotorola" SG_ 137 VehAccel_X_Offset 1;
BA_ "FlexKomComment" SG_ 137 VehAccel_X_Offset "Offset of vehicle longitudinal acceleration (+ mea";
BA_ "RID" SG_ 137 VehAccel_X "1277";
BA_ "GenSigTimeout_ORC" SG_ 137 VehAccel_X 70;
BA_ "GenSigTimeout_IC" SG_ 137 VehAccel_X 210;
BA_ "GenSigTimeout_CBC" SG_ 137 VehAccel_X 210;
BA_ "GenSigStartValue" SG_ 137 VehAccel_X 255;
BA_ "GenSigSNA" SG_ 137 VehAccel_X "FFh";
BA_ "GenSigCycleTime" SG_ 137 VehAccel_X 20;
BA_ "FlexKomSigStartValue" SG_ 137 VehAccel_X "FFh";
BA_ "FlexKomSigStartPos" SG_ 137 VehAccel_X 39;
BA_ "FlexKomSigName" SG_ 137 VehAccel_X "VehAccel_X";
BA_ "FlexKomSigLaenge" SG_ 137 VehAccel_X 8;
BA_ "FlexKomSID" SG_ 137 VehAccel_X 1265;
BA_ "FlexKomIsMotorola" SG_ 137 VehAccel_X 1;
BA_ "FlexKomComment" SG_ 137 VehAccel_X "Vehicle longitudinal acceleration (+ means forward";
BA_ "RID" SG_ 137 VehAccel_Y "1137";
BA_ "GenSigTimeout_ORC" SG_ 137 VehAccel_Y 70;
BA_ "GenSigTimeout_IC" SG_ 137 VehAccel_Y 210;
BA_ "GenSigTimeout_DTCM" SG_ 137 VehAccel_Y 210;
BA_ "GenSigTimeout_CBC" SG_ 137 VehAccel_Y 210;
BA_ "GenSigStartValue" SG_ 137 VehAccel_Y 255;
BA_ "GenSigSNA" SG_ 137 VehAccel_Y "FFh";
BA_ "GenSigCycleTime" SG_ 137 VehAccel_Y 20;
BA_ "FlexKomSigStartValue" SG_ 137 VehAccel_Y "FFh";
BA_ "FlexKomSigStartPos" SG_ 137 VehAccel_Y 47;
BA_ "FlexKomSigName" SG_ 137 VehAccel_Y "VehAccel_Y";
BA_ "FlexKomSigLaenge" SG_ 137 VehAccel_Y 8;
BA_ "FlexKomSID" SG_ 137 VehAccel_Y 1266;
BA_ "FlexKomIsMotorola" SG_ 137 VehAccel_Y 1;
BA_ "FlexKomComment" SG_ 137 VehAccel_Y "Vehicle lateral acceleration (+ means left, specif";
BA_ "GenSigTimeout_TBM" SG_ 137 MC_VEH_DYN_STAT 210;
BA_ "GenSigTimeout_ORC" SG_ 137 MC_VEH_DYN_STAT 70;
BA_ "GenSigTimeout_ETM" SG_ 137 MC_VEH_DYN_STAT 210;
BA_ "GenSigSNA" SG_ 137 MC_VEH_DYN_STAT "0h";
BA_ "GenSigCycleTime" SG_ 137 MC_VEH_DYN_STAT 20;
BA_ "FlexKomSigStartValue" SG_ 137 MC_VEH_DYN_STAT "00h";
BA_ "FlexKomSigStartPos" SG_ 137 MC_VEH_DYN_STAT 55;
BA_ "FlexKomSigName" SG_ 137 MC_VEH_DYN_STAT "MC_VEH_DYN_STAT";
BA_ "FlexKomSigLaenge" SG_ 137 MC_VEH_DYN_STAT 4;
BA_ "FlexKomSID" SG_ 137 MC_VEH_DYN_STAT 1267;
BA_ "FlexKomIsMotorola" SG_ 137 MC_VEH_DYN_STAT 1;
BA_ "FlexKomComment" SG_ 137 MC_VEH_DYN_STAT "Message counter";
BA_ "GenSigTimeout_TBM" SG_ 137 VehAccel_Y_Offset 210;
BA_ "GenSigTimeout_ORC" SG_ 137 VehAccel_Y_Offset 70;
BA_ "GenSigTimeout_IC" SG_ 137 VehAccel_Y_Offset 210;
BA_ "GenSigTimeout_ETM" SG_ 137 VehAccel_Y_Offset 210;
BA_ "GenSigStartValue" SG_ 137 VehAccel_Y_Offset 255;
BA_ "GenSigSNA" SG_ 137 VehAccel_Y_Offset "FFh";
BA_ "GenSigCycleTime" SG_ 137 VehAccel_Y_Offset 20;
BA_ "FlexKomSigStartValue" SG_ 137 VehAccel_Y_Offset "FFh";
BA_ "FlexKomSigStartPos" SG_ 137 VehAccel_Y_Offset 63;
BA_ "FlexKomSigName" SG_ 137 VehAccel_Y_Offset "VehAccel_Y_Offset";
BA_ "FlexKomSigLaenge" SG_ 137 VehAccel_Y_Offset 8;
BA_ "FlexKomSID" SG_ 137 VehAccel_Y_Offset 1268;
BA_ "FlexKomIsMotorola" SG_ 137 VehAccel_Y_Offset 1;
BA_ "FlexKomComment" SG_ 137 VehAccel_Y_Offset "Offset of vehicle lateral acceleration (+ means le";
BA_ "GenSigTimeout_ORC" SG_ 139 WhlRPM_FL 70;
BA_ "GenSigTimeout_ESL" SG_ 139 WhlRPM_FL 210;
BA_ "GenSigTimeout_DTCM" SG_ 139 WhlRPM_FL 210;
BA_ "GenSigStartValue" SG_ 139 WhlRPM_FL 16383;
BA_ "GenSigSNA" SG_ 139 WhlRPM_FL "3FFFh";
BA_ "GenSigCycleTime" SG_ 139 WhlRPM_FL 20;
BA_ "FlexKomSigStartValue" SG_ 139 WhlRPM_FL "FFFFFFFFFFFFFFFFh";
BA_ "FlexKomSigStartPos" SG_ 139 WhlRPM_FL 7;
BA_ "FlexKomSigName" SG_ 139 WhlRPM_FL "WHEEL_SPEED";
BA_ "FlexKomSigLaenge" SG_ 139 WhlRPM_FL 64;
BA_ "FlexKomSID" SG_ 139 WhlRPM_FL 64;
BA_ "FlexKomIsMotorola" SG_ 139 WhlRPM_FL 1;
BA_ "FlexKomComment" SG_ 139 WhlRPM_FL "ESP Wheel Speed";
BA_ "GenSigTimeout_ORC" SG_ 139 WhlDir_FL_Stat 70;
BA_ "GenSigStartValue" SG_ 139 WhlDir_FL_Stat 3;
BA_ "GenSigSNA" SG_ 139 WhlDir_FL_Stat "3h";
BA_ "GenSigCycleTime" SG_ 139 WhlDir_FL_Stat 20;
BA_ "FlexKomSigStartValue" SG_ 139 WhlDir_FL_Stat "FFFFFFFFFFFFFFFFh";
BA_ "FlexKomSigStartPos" SG_ 139 WhlDir_FL_Stat 7;
BA_ "FlexKomSigName" SG_ 139 WhlDir_FL_Stat "WHEEL_SPEED";
BA_ "FlexKomSigLaenge" SG_ 139 WhlDir_FL_Stat 64;
BA_ "FlexKomSID" SG_ 139 WhlDir_FL_Stat 64;
BA_ "FlexKomIsMotorola" SG_ 139 WhlDir_FL_Stat 1;
BA_ "FlexKomComment" SG_ 139 WhlDir_FL_Stat "ESP Wheel Speed";
BA_ "GenSigTimeout_ORC" SG_ 139 WhlRPM_FR 70;
BA_ "GenSigTimeout_ESL" SG_ 139 WhlRPM_FR 210;
BA_ "GenSigTimeout_DTCM" SG_ 139 WhlRPM_FR 210;
BA_ "GenSigStartValue" SG_ 139 WhlRPM_FR 16383;
BA_ "GenSigSNA" SG_ 139 WhlRPM_FR "3FFFh";
BA_ "GenSigCycleTime" SG_ 139 WhlRPM_FR 20;
BA_ "FlexKomSigStartValue" SG_ 139 WhlRPM_FR "FFFFFFFFFFFFFFFFh";
BA_ "FlexKomSigStartPos" SG_ 139 WhlRPM_FR 7;
BA_ "FlexKomSigName" SG_ 139 WhlRPM_FR "WHEEL_SPEED";
BA_ "FlexKomSigLaenge" SG_ 139 WhlRPM_FR 64;
BA_ "FlexKomSID" SG_ 139 WhlRPM_FR 64;
BA_ "FlexKomIsMotorola" SG_ 139 WhlRPM_FR 1;
BA_ "FlexKomComment" SG_ 139 WhlRPM_FR "ESP Wheel Speed";
BA_ "GenSigTimeout_ORC" SG_ 139 WhlDir_FR_Stat 70;
BA_ "GenSigStartValue" SG_ 139 WhlDir_FR_Stat 3;
BA_ "GenSigSNA" SG_ 139 WhlDir_FR_Stat "3h";
BA_ "GenSigCycleTime" SG_ 139 WhlDir_FR_Stat 20;
BA_ "FlexKomSigStartValue" SG_ 139 WhlDir_FR_Stat "FFFFFFFFFFFFFFFFh";
BA_ "FlexKomSigStartPos" SG_ 139 WhlDir_FR_Stat 7;
BA_ "FlexKomSigName" SG_ 139 WhlDir_FR_Stat "WHEEL_SPEED";
BA_ "FlexKomSigLaenge" SG_ 139 WhlDir_FR_Stat 64;
BA_ "FlexKomSID" SG_ 139 WhlDir_FR_Stat 64;
BA_ "FlexKomIsMotorola" SG_ 139 WhlDir_FR_Stat 1;
BA_ "FlexKomComment" SG_ 139 WhlDir_FR_Stat "ESP Wheel Speed";
BA_ "GenSigTimeout_TCM" SG_ 139 WhlRPM_RL 210;
BA_ "GenSigTimeout_ORC" SG_ 139 WhlRPM_RL 70;
BA_ "GenSigTimeout_ESL" SG_ 139 WhlRPM_RL 210;
BA_ "GenSigTimeout_DTCM" SG_ 139 WhlRPM_RL 210;
BA_ "GenSigTimeout_CBC" SG_ 139 WhlRPM_RL 110;
BA_ "GenSigStartValue" SG_ 139 WhlRPM_RL 16383;
BA_ "GenSigSNA" SG_ 139 WhlRPM_RL "3FFFh";
BA_ "GenSigCycleTime" SG_ 139 WhlRPM_RL 20;
BA_ "FlexKomSigStartValue" SG_ 139 WhlRPM_RL "FFFFFFFFFFFFFFFFh";
BA_ "FlexKomSigStartPos" SG_ 139 WhlRPM_RL 7;
BA_ "FlexKomSigName" SG_ 139 WhlRPM_RL "WHEEL_SPEED";
BA_ "FlexKomSigLaenge" SG_ 139 WhlRPM_RL 64;
BA_ "FlexKomSID" SG_ 139 WhlRPM_RL 64;
BA_ "FlexKomIsMotorola" SG_ 139 WhlRPM_RL 1;
BA_ "FlexKomComment" SG_ 139 WhlRPM_RL "ESP Wheel Speed";
BA_ "GenSigTimeout_ORC" SG_ 139 WhlDir_RL_Stat 70;
BA_ "GenSigStartValue" SG_ 139 WhlDir_RL_Stat 3;
BA_ "GenSigSNA" SG_ 139 WhlDir_RL_Stat "3h";
BA_ "GenSigCycleTime" SG_ 139 WhlDir_RL_Stat 20;
BA_ "FlexKomSigStartValue" SG_ 139 WhlDir_RL_Stat "FFFFFFFFFFFFFFFFh";
BA_ "FlexKomSigStartPos" SG_ 139 WhlDir_RL_Stat 7;
BA_ "FlexKomSigName" SG_ 139 WhlDir_RL_Stat "WHEEL_SPEED";
BA_ "FlexKomSigLaenge" SG_ 139 WhlDir_RL_Stat 64;
BA_ "FlexKomSID" SG_ 139 WhlDir_RL_Stat 64;
BA_ "FlexKomIsMotorola" SG_ 139 WhlDir_RL_Stat 1;
BA_ "FlexKomComment" SG_ 139 WhlDir_RL_Stat "ESP Wheel Speed";
BA_ "GenSigTimeout_TCM" SG_ 139 WhlRPM_RR 210;
BA_ "GenSigTimeout_ORC" SG_ 139 WhlRPM_RR 70;
BA_ "GenSigTimeout_ESL" SG_ 139 WhlRPM_RR 210;
BA_ "GenSigTimeout_DTCM" SG_ 139 WhlRPM_RR 210;
BA_ "GenSigTimeout_CBC" SG_ 139 WhlRPM_RR 110;
BA_ "GenSigStartValue" SG_ 139 WhlRPM_RR 16383;
BA_ "GenSigSNA" SG_ 139 WhlRPM_RR "3FFFh";
BA_ "GenSigCycleTime" SG_ 139 WhlRPM_RR 20;
BA_ "FlexKomSigStartValue" SG_ 139 WhlRPM_RR "FFFFFFFFFFFFFFFFh";
BA_ "FlexKomSigStartPos" SG_ 139 WhlRPM_RR 7;
BA_ "FlexKomSigName" SG_ 139 WhlRPM_RR "WHEEL_SPEED";
BA_ "FlexKomSigLaenge" SG_ 139 WhlRPM_RR 64;
BA_ "FlexKomSID" SG_ 139 WhlRPM_RR 64;
BA_ "FlexKomIsMotorola" SG_ 139 WhlRPM_RR 1;
BA_ "FlexKomComment" SG_ 139 WhlRPM_RR "ESP Wheel Speed";
BA_ "GenSigTimeout_ORC" SG_ 139 WhlDir_RR_Stat 70;
BA_ "GenSigStartValue" SG_ 139 WhlDir_RR_Stat 3;
BA_ "GenSigSNA" SG_ 139 WhlDir_RR_Stat "3h";
BA_ "GenSigCycleTime" SG_ 139 WhlDir_RR_Stat 20;
BA_ "FlexKomSigStartValue" SG_ 139 WhlDir_RR_Stat "FFFFFFFFFFFFFFFFh";
BA_ "FlexKomSigStartPos" SG_ 139 WhlDir_RR_Stat 7;
BA_ "FlexKomSigName" SG_ 139 WhlDir_RR_Stat "WHEEL_SPEED";
BA_ "FlexKomSigLaenge" SG_ 139 WhlDir_RR_Stat 64;
BA_ "FlexKomSID" SG_ 139 WhlDir_RR_Stat 64;
BA_ "FlexKomIsMotorola" SG_ 139 WhlDir_RR_Stat 1;
BA_ "FlexKomComment" SG_ 139 WhlDir_RR_Stat "ESP Wheel Speed";
BA_ "RID" SG_ 141 ACT_CNT_DIF_TRQ "1268";
BA_ "GenSigTimeout_ETM" SG_ 141 ACT_CNT_DIF_TRQ 210;
BA_ "GenSigTimeout_CBC" SG_ 141 ACT_CNT_DIF_TRQ 210;
BA_ "GenSigStartValue" SG_ 141 ACT_CNT_DIF_TRQ 255;
BA_ "GenSigSNA" SG_ 141 ACT_CNT_DIF_TRQ "FFh";
BA_ "GenSigCycleTime" SG_ 141 ACT_CNT_DIF_TRQ 20;
BA_ "FlexKomSigStartValue" SG_ 141 ACT_CNT_DIF_TRQ "CEC0FFFFFFFFFFFFh";
BA_ "FlexKomSigStartPos" SG_ 141 ACT_CNT_DIF_TRQ 7;
BA_ "FlexKomSigName" SG_ 141 ACT_CNT_DIF_TRQ "DTCM_A1_PKT";
BA_ "FlexKomSigLaenge" SG_ 141 ACT_CNT_DIF_TRQ 64;
BA_ "FlexKomSID" SG_ 141 ACT_CNT_DIF_TRQ 807;
BA_ "FlexKomIsMotorola" SG_ 141 ACT_CNT_DIF_TRQ 1;
BA_ "FlexKomComment" SG_ 141 ACT_CNT_DIF_TRQ "DTCM_A1_PKT";
BA_ "GenSigStartValue" SG_ 141 DES_CNT_DIF_TRQ 255;
BA_ "GenSigSNA" SG_ 141 DES_CNT_DIF_TRQ "FFh";
BA_ "GenSigCycleTime" SG_ 141 DES_CNT_DIF_TRQ 20;
BA_ "FlexKomSigStartValue" SG_ 141 DES_CNT_DIF_TRQ "CEC0FFFFFFFFFFFFh";
BA_ "FlexKomSigStartPos" SG_ 141 DES_CNT_DIF_TRQ 7;
BA_ "FlexKomSigName" SG_ 141 DES_CNT_DIF_TRQ "DTCM_A1_PKT";
BA_ "FlexKomSigLaenge" SG_ 141 DES_CNT_DIF_TRQ 64;
BA_ "FlexKomSID" SG_ 141 DES_CNT_DIF_TRQ 807;
BA_ "FlexKomIsMotorola" SG_ 141 DES_CNT_DIF_TRQ 1;
BA_ "FlexKomComment" SG_ 141 DES_CNT_DIF_TRQ "DTCM_A1_PKT";
BA_ "GenSigSNA" SG_ 141 TCASERANGESTATUS "3h";
BA_ "GenSigCycleTime" SG_ 141 TCASERANGESTATUS 20;
BA_ "FlexKomSigStartValue" SG_ 141 TCASERANGESTATUS "CEC0FFFFFFFFFFFFh";
BA_ "FlexKomSigStartPos" SG_ 141 TCASERANGESTATUS 7;
BA_ "FlexKomSigName" SG_ 141 TCASERANGESTATUS "DTCM_A1_PKT";
BA_ "FlexKomSigLaenge" SG_ 141 TCASERANGESTATUS 64;
BA_ "FlexKomSID" SG_ 141 TCASERANGESTATUS 807;
BA_ "FlexKomIsMotorola" SG_ 141 TCASERANGESTATUS 1;
BA_ "FlexKomComment" SG_ 141 TCASERANGESTATUS "DTCM_A1_PKT";
BA_ "RID" SG_ 141 TCASE_STAT "1238";
BA_ "GenSigTimeout_TCM" SG_ 141 TCASE_STAT 210;
BA_ "GenSigTimeout_RF_HUB" SG_ 141 TCASE_STAT 210;
BA_ "GenSigTimeout_PTS" SG_ 141 TCASE_STAT 210;
BA_ "GenSigTimeout_ORC" SG_ 141 TCASE_STAT 70;
BA_ "GenSigTimeout_IC" SG_ 141 TCASE_STAT 210;
BA_ "GenSigTimeout_ETM" SG_ 141 TCASE_STAT 210;
BA_ "GenSigTimeout_CBC" SG_ 141 TCASE_STAT 210;
BA_ "GenSigStartValue" SG_ 141 TCASE_STAT 7;
BA_ "GenSigSNA" SG_ 141 TCASE_STAT "7h";
BA_ "GenSigCycleTime" SG_ 141 TCASE_STAT 20;
BA_ "FlexKomSigStartValue" SG_ 141 TCASE_STAT "CEC0FFFFFFFFFFFFh";
BA_ "FlexKomSigStartPos" SG_ 141 TCASE_STAT 7;
BA_ "FlexKomSigName" SG_ 141 TCASE_STAT "DTCM_A1_PKT";
BA_ "FlexKomSigLaenge" SG_ 141 TCASE_STAT 64;
BA_ "FlexKomSID" SG_ 141 TCASE_STAT 807;
BA_ "FlexKomIsMotorola" SG_ 141 TCASE_STAT 1;
BA_ "FlexKomComment" SG_ 141 TCASE_STAT "DTCM_A1_PKT";
BA_ "GenSigSNA" SG_ 141 SHFT_ABRT "1h";
BA_ "GenSigCycleTime" SG_ 141 SHFT_ABRT 20;
BA_ "FlexKomSigStartValue" SG_ 141 SHFT_ABRT "CEC0FFFFFFFFFFFFh";
BA_ "FlexKomSigStartPos" SG_ 141 SHFT_ABRT 7;
BA_ "FlexKomSigName" SG_ 141 SHFT_ABRT "DTCM_A1_PKT";
BA_ "FlexKomSigLaenge" SG_ 141 SHFT_ABRT 64;
BA_ "FlexKomSID" SG_ 141 SHFT_ABRT 807;
BA_ "FlexKomIsMotorola" SG_ 141 SHFT_ABRT 1;
BA_ "FlexKomComment" SG_ 141 SHFT_ABRT "DTCM_A1_PKT";
BA_ "GenSigSNA" SG_ 141 TCASE_2LO_STAT "3h";
BA_ "GenSigCycleTime" SG_ 141 TCASE_2LO_STAT 20;
BA_ "FlexKomSigStartValue" SG_ 141 TCASE_2LO_STAT "CEC0FFFFFFFFFFFFh";
BA_ "FlexKomSigStartPos" SG_ 141 TCASE_2LO_STAT 7;
BA_ "FlexKomSigName" SG_ 141 TCASE_2LO_STAT "DTCM_A1_PKT";
BA_ "FlexKomSigLaenge" SG_ 141 TCASE_2LO_STAT 64;
BA_ "FlexKomSID" SG_ 141 TCASE_2LO_STAT 807;
BA_ "FlexKomIsMotorola" SG_ 141 TCASE_2LO_STAT 1;
BA_ "FlexKomComment" SG_ 141 TCASE_2LO_STAT "DTCM_A1_PKT";
BA_ "GenSigStartValue" SG_ 145 DrvLnTrqRq 511;
BA_ "GenSigSNA" SG_ 145 DrvLnTrqRq "1FFh";
BA_ "GenSigCycleTime" SG_ 145 DrvLnTrqRq 20;
BA_ "FlexKomSigStartValue" SG_ 145 DrvLnTrqRq "01FF7F00000000FFh";
BA_ "FlexKomSigStartPos" SG_ 145 DrvLnTrqRq 7;
BA_ "FlexKomSigName" SG_ 145 DrvLnTrqRq "DTCM_A2_PKT";
BA_ "FlexKomSigLaenge" SG_ 145 DrvLnTrqRq 64;
BA_ "FlexKomSID" SG_ 145 DrvLnTrqRq 1520;
BA_ "FlexKomIsMotorola" SG_ 145 DrvLnTrqRq 1;
BA_ "FlexKomComment" SG_ 145 DrvLnTrqRq "DTCM_A2_PKT";
BA_ "GenSigSNA" SG_ 145 DrvLnMinTrqMd "0h";
BA_ "GenSigCycleTime" SG_ 145 DrvLnMinTrqMd 20;
BA_ "FlexKomSigStartValue" SG_ 145 DrvLnMinTrqMd "01FF7F00000000FFh";
BA_ "FlexKomSigStartPos" SG_ 145 DrvLnMinTrqMd 7;
BA_ "FlexKomSigName" SG_ 145 DrvLnMinTrqMd "DTCM_A2_PKT";
BA_ "FlexKomSigLaenge" SG_ 145 DrvLnMinTrqMd 64;
BA_ "FlexKomSID" SG_ 145 DrvLnMinTrqMd 1520;
BA_ "FlexKomIsMotorola" SG_ 145 DrvLnMinTrqMd 1;
BA_ "FlexKomComment" SG_ 145 DrvLnMinTrqMd "DTCM_A2_PKT";
BA_ "GenSigSNA" SG_ 145 MC_DTCM_A2 "0h";
BA_ "GenSigCycleTime" SG_ 145 MC_DTCM_A2 20;
BA_ "FlexKomSigStartValue" SG_ 145 MC_DTCM_A2 "01FF7F00000000FFh";
BA_ "FlexKomSigStartPos" SG_ 145 MC_DTCM_A2 7;
BA_ "FlexKomSigName" SG_ 145 MC_DTCM_A2 "DTCM_A2_PKT";
BA_ "FlexKomSigLaenge" SG_ 145 MC_DTCM_A2 64;
BA_ "FlexKomSID" SG_ 145 MC_DTCM_A2 1520;
BA_ "FlexKomIsMotorola" SG_ 145 MC_DTCM_A2 1;
BA_ "FlexKomComment" SG_ 145 MC_DTCM_A2 "DTCM_A2_PKT";
BA_ "GenSigStartValue" SG_ 145 CRC_DTCM_A2 255;
BA_ "GenSigSNA" SG_ 145 CRC_DTCM_A2 "FFh";
BA_ "GenSigCycleTime" SG_ 145 CRC_DTCM_A2 20;
BA_ "FlexKomSigStartValue" SG_ 145 CRC_DTCM_A2 "01FF7F00000000FFh";
BA_ "FlexKomSigStartPos" SG_ 145 CRC_DTCM_A2 7;
BA_ "FlexKomSigName" SG_ 145 CRC_DTCM_A2 "DTCM_A2_PKT";
BA_ "FlexKomSigLaenge" SG_ 145 CRC_DTCM_A2 64;
BA_ "FlexKomSID" SG_ 145 CRC_DTCM_A2 1520;
BA_ "FlexKomIsMotorola" SG_ 145 CRC_DTCM_A2 1;
BA_ "FlexKomComment" SG_ 145 CRC_DTCM_A2 "DTCM_A2_PKT";
BA_ "GenSigSNA" SG_ 145 FAD_STAT "3h";
BA_ "GenSigCycleTime" SG_ 145 FAD_STAT 20;
BA_ "FlexKomSigStartValue" SG_ 145 FAD_STAT "01FF7F00000000FFh";
BA_ "FlexKomSigStartPos" SG_ 145 FAD_STAT 7;
BA_ "FlexKomSigName" SG_ 145 FAD_STAT "DTCM_A2_PKT";
BA_ "FlexKomSigLaenge" SG_ 145 FAD_STAT 64;
BA_ "FlexKomSID" SG_ 145 FAD_STAT 1520;
BA_ "FlexKomIsMotorola" SG_ 145 FAD_STAT 1;
BA_ "FlexKomComment" SG_ 145 FAD_STAT "DTCM_A2_PKT";
VAL_ 35 LRW 16383 "SNA" ;
VAL_ 35 VLRW 16383 "SNA" ;
VAL_ 35 LRWS_ST 0 "OK" 1 "INI" 2 "ERR" 3 "ERR_INI" ;
VAL_ 35 Pad_Shft 0 "PS_OFF" 1 "PS_RIGHT" 2 "PS_LEFT" 3 "PS_BOTH" 7 "SNA" ;
VAL_ 37 EngRPM 65535 "SNA" ;
VAL_ 37 EngTrqStatic 8191 "SNA" ;
VAL_ 37 ExpEngTrq 8191 "SNA" ;
VAL_ 37 ECM_LHOM_Trans 0 "LH_NOT_ACTIVE" 1 "RM_UNAVAILABLE" 2 "PRECISE_TRQ" 3 "IMPRECISE_TRQ" ;
VAL_ 38 EngRPM_PHEV 65535 "SNA" ;
VAL_ 38 ECM_LHOM_Trans_PHEV 0 "LH_NOT_ACTIVE" 1 "RM_UNAVAILABLE" 2 "PRECISE_TRQ" 3 "IMPRECISE_TRQ" ;
VAL_ 38 EngMaxRPM_PHEV 255 "SNA" ;
VAL_ 38 ESS_ENG_ST_PHEV 1 "ENS_STOPPED" 2 "ENS_RQ_ST" 3 "ENS_RUN" 4 "ENS_STOP_PEND" 5 "ENS_ST_PRTCT" 6 "ENS_ST_INH" 7 "ENS_DSBL" 8 "ENS_IHB_LATCH" 9 "ENS_STARTING" 10 "KEY_START" 11 "ENS_CHANGE_MIND" 15 "SNA" ;
VAL_ 38 ECM_IMMO_STAT_CANC_PHEV 0 "IS" 1 "KILL" 2 "RUN" 3 "SNA" ;
VAL_ 39 EngTrqMax 8191 "SNA" ;
VAL_ 39 EngTrqMin 8191 "SNA" ;
VAL_ 39 StartRelayBCMCmd 0 "SNA" ;
VAL_ 40 SumTrqMax 8191 "SNA" ;
VAL_ 40 SumTrqMin 8191 "SNA" ;
VAL_ 40 SumTrqStatic 8191 "SNA" ;
VAL_ 41 PropulsionMode 0 "Hybrid_Parallel" 1 "EV_Only" 2 "Hybrid_Series" 7 "SNA" ;
VAL_ 43 LatAcceleration 4095 "SNA" ;
VAL_ 43 AXSStat 0 "SISL" 1 "TSE" 2 "PSE" 3 "SEII" ;
VAL_ 43 AYSStat 0 "SISL" 1 "TSE" 2 "PSE" 3 "SEII" ;
VAL_ 43 LongAcceleration 4095 "SNA" ;
VAL_ 43 YRSStat 0 "SISL" 1 "TSE" 2 "PSE" 3 "SEII" ;
VAL_ 43 YawRate 4095 "SNA" ;
VAL_ 53 EngTrqTgt_SEM 8191 "SNA" ;
VAL_ 53 EngRdyForESS 0 "SNA" ;
VAL_ 53 EngTrqStatic_SEM 8191 "SNA" ;
VAL_ 53 TRANS_CLU_SLIP_MODE 0 "NORMAL" 1 "MDS_RQ" 2 "IDFSO_RQ" 3 "AC_EN_DIS_RQ" 4 "IDFSO_ACTIVE" 5 "MDS_IDFSO_ACT" 7 "SNA" ;
VAL_ 53 EngMaxRPM 255 "SNA" ;
VAL_ 53 ESS_ENG_ST 1 "ENS_STOPPED" 2 "ENS_RQ_ST" 3 "ENS_RUN" 4 "ENS_STOP_PEND" 5 "ENS_ST_PRTCT" 6 "ENS_ST_INH" 7 "ENS_DSBL" 8 "ENS_IHB_LATCH" 9 "ENS_STARTING" 10 "KEY_START" 11 "ENS_CHANGE_MIND" 15 "SNA" ;
VAL_ 53 EngStallSts 0 "NOT_STALL" 1 "STALL" 3 "SNA" ;
VAL_ 54 SumTrqTgt_SEM 8191 "SNA" ;
VAL_ 54 SumTrqStatic_SEM 8191 "SNA" ;
VAL_ 54 ExpSumTrq 8191 "SNA" ;
VAL_ 55 EngTrqRq 8191 "SNA" ;
VAL_ 55 TrqCtrlModeRq 0 "NONE" 1 "TRQ_INC_Fast" 2 "TRQ_DEC_Fast" 7 "SNA" ;
VAL_ 55 MaxTrqDes 8191 "SNA" ;
VAL_ 56 SumTrqSel_D_TTC 8191 "SNA" ;
VAL_ 56 SumTrq_DrvReqMod 8191 "SNA" ;
VAL_ 56 MotorB_Speed 65535 "SNA" ;
VAL_ 113 EngTrq_Rq_ESC 8191 "SNA" ;
VAL_ 113 EngTrq_Rq_As 8191 "SNA" ;
VAL_ 113 BrkBstrVac 255 "SNA" ;
VAL_ 113 DAS_RqActv 0 "IDLE" 1 "ACC" 2 "CMS" 3 "ABA" 4 "LSCM" 5 "CMS_XTD" 6 "PEB" 7 "SNA" ;
VAL_ 114 BrkTrq_ILE 4095 "SNA" ;
VAL_ 117 WhlTrq_Rq_As_2 65535 "SNA" ;
VAL_ 119 CmdIgnStat 0 "IGN_LK" 3 "IGN_OFF_ACC" 4 "IGN_RUN" 5 "IGN_START" 7 "SNA" ;
VAL_ 119 StTyp 0 "ST_NOT_ACT" 1 "NOR_ST" 2 "TIP_ST" 3 "REM_ST" 7 "SNA" ;
VAL_ 119 KeyInIgn 0 "KEY_DEF" 1 "KEY_NOT_IN_IGN" 2 "KEY_IN_IGN" 3 "SNA" ;
VAL_ 120 BrakeBoostPressure 2047 "SNA" ;
VAL_ 120 BrakePedalPressure 2047 "SNA" ;
VAL_ 120 BrakePdlPosn 255 "SNA" ;
VAL_ 120 BrakeBoostStat 0 "INIT_Bst" 1 "Normal_Bst" 2 "Limited_Bst" 3 "Shutdown_Bst" 4 "MOCO" 5 "Half_Sys_Bst" 6 "No_Bst" 15 "SNA" ;
VAL_ 120 BSMHybridModeReq 0 "No_Request" 1 "Electric_Mode" 2 "Engine_On_Mode" 3 "SNA" ;
VAL_ 121 BrkTrq 4095 "SNA" ;
VAL_ 121 BrkTrq_D 4095 "SNA" ;
VAL_ 121 VEH_SPEED 65535 "SNA" ;
VAL_ 123 EngTrqSel_D_TTC 8191 "SNA" ;
VAL_ 123 AccelPdlPosn 255 "SNA" ;
VAL_ 123 EngTrq_DrvReqMod 8191 "SNA" ;
VAL_ 124 ECM_Comm_Fail_ePT 0 "No_Fault" 1 "ECM_LoC_ePT_TCM" 2 "ECM_LoC_ePT_HCP" 3 "ECM_LoC_ePT_HCP_TCM" 7 "ECM_Bus_Failure_ePT" ;
VAL_ 125 EngTrqMaxCorrFctr 255 "SNA" ;
VAL_ 125 GrMin_Rq_ECM 0 "PASSIVE" 1 "G1" 2 "G2" 3 "G3" 4 "G4" 5 "G5" 6 "G6" 7 "G7" ;
VAL_ 125 GrMax_Rq_ECM 0 "PASSIVE" 1 "G1" 2 "G2" 3 "G3" 4 "G4" 5 "G5" 6 "G6" 7 "G7" ;
VAL_ 125 NMOTS 65535 "SNA" ;
VAL_ 127 WhlPlsCnt_FL 255 "SNA" ;
VAL_ 127 WhlPlsCnt_FR 255 "SNA" ;
VAL_ 127 WhlPlsCnt_RL 255 "SNA" ;
VAL_ 127 WhlPlsCnt_RR 255 "SNA" ;
VAL_ 127 CENT_DIFF_ESP_RQ 0 "FREE" 1 "HOLD" 2 "OPEN" 3 "SNA" ;
VAL_ 127 CENT_DIFF_TRQ_RQ 255 "SNA" ;
VAL_ 129 SpeedLimitSts 0 "S_B" 1 "ACT" 2 "N_A" 3 "OVER" 4 "OVER_SPEED" 5 "DEACTIVATED" 6 "OFF" 7 "SNA" ;
VAL_ 129 CRUISE_EGD 0 "SNA" ;
VAL_ 129 CRUISE_ON 0 "SNA" ;
VAL_ 129 V_MAX_TM 255 "SNA" ;
VAL_ 129 MAP_ENG 255 "SNA" ;
VAL_ 129 BARO_ENG 255 "SNA" ;
VAL_ 129 Rel_Thrt_ENG 255 "SNA" ;
VAL_ 129 Rel_Pdl_ENG 255 "SNA" ;
VAL_ 129 ECM_WARN 0 "None" 1 "WARN_1" 2 "WARN_2" 3 "WARN_3" 4 "WARN_4" 5 "WARN_5" 6 "WARN_6" 7 "SNA" ;
VAL_ 131 Brk_Stat 0 "IDLE" 1 "BRAKING" 2 "NDEF2" 3 "SNA" ;
VAL_ 131 BrkPdl_Stat 0 "UPSTOP" 1 "PSD" 2 "NDEF2" 3 "SNA" ;
VAL_ 131 ESP_Sys_Stat 0 "ABSERR" 1 "NORM" 2 "HALF" 3 "ABGAS" ;
VAL_ 131 SelSpdSts 0 "OFF" 1 "SELECT" 2 "INHIBIT" 3 "SNA" ;
VAL_ 131 DTR_CC_Engaged 0 "SNA" ;
VAL_ 131 GrMin_Rq_ESC 0 "PASSIVE" 1 "G1" 2 "G2" 3 "G3" 4 "G4" 5 "G5" 6 "G6" 7 "G7" ;
VAL_ 131 GrMax_Rq_ESC 0 "PASSIVE" 1 "G1" 2 "G2" 3 "G3" 4 "G4" 5 "G5" 6 "G6" 7 "G7" ;
VAL_ 131 DTR_CC_Enabled 0 "SNA" ;
VAL_ 131 ShftChrDsp_Rq_ESC 0 "SKL0" 1 "SKL1" 2 "SKL2" 3 "SKL3" 4 "SKL4" 5 "SKL5" 6 "SKL6" 7 "SKL7" 8 "SKL8" 9 "SKL9" 10 "SKL10" 11 "SKL11" 12 "SKL12" 15 "SNA" ;
VAL_ 131 RollTestMd_Actv 0 "OFF" 1 "ON" 2 "NDEF2" 3 "SNA" ;
VAL_ 131 REF_VEH_SPEED 1023 "SNA" ;
VAL_ 131 SPCR_AS_Off_Rq 0 "IDLE" 1 "AS_TMP_OFF" 2 "AS_CNTS_OFF" 3 "SPCR_NA" ;
VAL_ 131 HillHolderActive 0 "Not_Active" 1 "Active" ;
VAL_ 133 Gr 0 "N" 1 "D1" 2 "D2" 3 "D3" 4 "D4" 5 "D5" 6 "D6" 7 "D7" 8 "D8" 9 "D2P" 10 "D9" 11 "R" 12 "R2" 13 "P" 14 "KRAFTFREI" 15 "SNA" ;
VAL_ 133 Gr_Target 0 "N" 1 "D1" 2 "D2" 3 "D3" 4 "D4" 5 "D5" 6 "D6" 7 "D7" 8 "D8" 9 "D2P" 10 "D9" 11 "R" 12 "R2" 13 "P" 14 "ABBRUCH" 15 "SNA" ;
VAL_ 133 OUTPUT_SPEED 65535 "SNA" ;
VAL_ 133 N_Turb 65535 "SNA" ;
VAL_ 133 OutputSpdPolarity 0 "DND" 1 "DF" 2 "DB" 3 "SNA" ;
VAL_ 135 BrkPrss_TMC 2047 "SNA" ;
VAL_ 135 HSA_BrkPrss 63 "SNA" ;
VAL_ 137 VehYawRate_Raw 65535 "SNA" ;
VAL_ 137 VehYawRate_Offset 255 "SNA" ;
VAL_ 137 VehAccel_X_Offset 255 "SNA" ;
VAL_ 137 VehAccel_X 255 "SNA" ;
VAL_ 137 VehAccel_Y 255 "SNA" ;
VAL_ 137 VehAccel_Y_Offset 255 "SNA" ;
VAL_ 139 WhlRPM_FL 16383 "SNA" ;
VAL_ 139 WhlDir_FL_Stat 0 "VOID" 1 "FORWARD" 2 "BACKWARD" 3 "SNA" ;
VAL_ 139 WhlRPM_FR 16383 "SNA" ;
VAL_ 139 WhlDir_FR_Stat 0 "VOID" 1 "FORWARD" 2 "BACKWARD" 3 "SNA" ;
VAL_ 139 WhlRPM_RL 16383 "SNA" ;
VAL_ 139 WhlDir_RL_Stat 0 "VOID" 1 "FORWARD" 2 "BACKWARD" 3 "SNA" ;
VAL_ 139 WhlRPM_RR 16383 "SNA" ;
VAL_ 139 WhlDir_RR_Stat 0 "VOID" 1 "FORWARD" 2 "BACKWARD" 3 "SNA" ;
VAL_ 141 ACT_CNT_DIF_TRQ 255 "SNA" ;
VAL_ 141 DES_CNT_DIF_TRQ 255 "SNA" ;
VAL_ 141 TCASERANGESTATUS 0 "HIGH" 1 "NTRL" 2 "LOW" 3 "SNA" ;
VAL_ 141 TCASE_STAT 0 "SH_IPG" 1 "4LO" 2 "4HI" 3 "2WD" 4 "N" 5 "AUTO" 6 "PT" 7 "SNA" ;
VAL_ 141 SHFT_ABRT 1 "SNA" ;
VAL_ 141 TCASE_2LO_STAT 0 "Not_Active" 1 "Active" 2 "Not_Used" 3 "SNA" ;
VAL_ 145 DrvLnTrqRq 511 "SNA" ;
VAL_ 145 FAD_STAT 0 "SH_IPG" 1 "Engaged" 2 "Disengaged" 3 "SNA" ;
